VERSION "hnnbnnnynnnnnnnnnnnnnnnnnnnnnnnnnnnnnnnnnn/4/%%%/4/'%**4nnn///"

NS_ :

BS_:

BU_: BAP_Tester Fahrerdisplay_Kombi HUD ICAS1_X_Gateway ICAS3_Gateway ICC_IO_Node Kombi SmartLight_01 ZR_MIB_TOP_ab_Gen3

BO_ 1646 Klima_03: 8 ICAS1_X_Gateway
	SG_ KL_Anf_AussenspiegelHzg : 48|1@1+ (1,0) [0|1] ""  Vector__XXX
	SG_ KL_BCmE_Livetip_Freigabe : 24|1@1+ (1,0) [0|1] ""  Kombi
	SG_ KL_ErwVK_Anf : 31|1@1+ (1,0) [0|1] ""  Vector__XXX
	SG_ KL_FSH_Automatikbetrieb : 51|1@1+ (1,0) [0|1] ""  Vector__XXX
	SG_ KL_Geblaese_Fond_Status : 4|4@1+ (1,0) [0|15] ""  Vector__XXX
	SG_ KL_Geblaese_Status : 18|4@1+ (1,0) [0|15] ""  Kombi
	SG_ KL_Heizkreisventilstellung : 49|2@1+ (1,0) [0|3] ""  Vector__XXX
	SG_ KL_I_Geblaese_Fond : 40|8@1+ (0.25,0) [0|63.5] "Amper"  Vector__XXX
	SG_ KL_Innen_Temp : 32|8@1+ (0.5,-50) [-50|76] "DegreCelsi"  SmartLight_01
	SG_ KL_Kompressorkupplung : 23|1@1+ (1,0) [0|1] ""  Vector__XXX
	SG_ KL_Magnetventil : 16|1@1+ (1,0) [0|1] ""  Vector__XXX
	SG_ KL_Restwaerme_aktiv : 22|1@1+ (1,0) [0|1] ""  Vector__XXX
	SG_ KL_SH_Soll_hl : 25|3@1+ (1,0) [0|7] ""  Vector__XXX
	SG_ KL_SH_Soll_hr : 28|3@1+ (1,0) [0|7] ""  Vector__XXX
	SG_ KL_SIH_LEH_Verteilung_VL : 52|3@1+ (1,0) [0|7] ""  Vector__XXX
	SG_ KL_SIH_LEH_Verteilung_VR : 58|3@1+ (1,0) [0|7] ""  Vector__XXX
	SG_ KL_SIH_LEL_Verteilung_VL : 55|3@1+ (1,0) [0|7] ""  Vector__XXX
	SG_ KL_SIH_LEL_Verteilung_VR : 61|3@1+ (1,0) [0|7] ""  Vector__XXX
	SG_ KL_Solarluefter_aktiv : 2|1@1+ (1,0) [0|1] ""  Vector__XXX
	SG_ KL_STH_aktiv : 1|1@1+ (1,0) [0|1] ""  Vector__XXX
	SG_ KL_STH_Ansteuerung : 8|2@1+ (1,0) [0|3] ""  Vector__XXX
	SG_ KL_STH_Betriebsdauer : 10|6@1+ (1,0) [0|60] "Minut"  Vector__XXX
	SG_ KL_STL_aktiv : 0|1@1+ (1,0) [0|1] ""  Vector__XXX
	SG_ KL_Umluft_Taste : 3|1@1+ (1,0) [0|1] ""  Vector__XXX
	SG_ KL_WaPu : 17|1@1+ (1,0) [0|1] ""  Vector__XXX

BO_ 1649 Klima_06: 8 ICAS1_X_Gateway
	SG_ KL_Betriebsmodus_FH : 29|3@1+ (1,0) [0|7] ""  Vector__XXX
	SG_ KL_ErwVK_Beifahrerzone : 60|1@1+ (1,0) [0|1] ""  Vector__XXX
	SG_ KL_ErwVK_Fahrerzone : 61|1@1+ (1,0) [0|1] ""  Vector__XXX
	SG_ KL_ErwVK_Heckzone_links : 62|1@1+ (1,0) [0|1] ""  Vector__XXX
	SG_ Kl_ErwVK_Heckzone_rechts : 63|1@1+ (1,0) [0|1] ""  Vector__XXX
	SG_ KL_ErwVK_Scheibenheizung : 12|1@1+ (1,0) [0|1] ""  Vector__XXX
	SG_ KL_ErwVK_Status : 54|4@1+ (1,0) [0|15] ""  Vector__XXX
	SG_ KL_Hinweis_Kuehlmodus : 58|2@1+ (1,0) [0|3] ""  ICAS3_Gateway,Kombi
	SG_ KL_Meldung_Status : 50|4@1+ (1,0) [0|15] ""  Kombi,ZR_MIB_TOP_ab_Gen3
	SG_ KL_STH_Betriebsdauer_lang : 43|7@1+ (1,0) [0|120] "Minut"  Vector__XXX
	SG_ KL_Stopp_Wiederstart_Anz_01 : 32|1@1+ (1,0) [0|1] ""  Vector__XXX
	SG_ KL_Stopp_Wiederstart_Anz_02 : 33|1@1+ (1,0) [0|1] ""  Vector__XXX
	SG_ KL_Stopp_Wiederstart_Anz_03 : 34|1@1+ (1,0) [0|1] ""  Vector__XXX
	SG_ KL_Stopp_Wiederstart_Anz_04 : 35|1@1+ (1,0) [0|1] ""  Vector__XXX
	SG_ KL_Stopp_Wiederstart_Anz_05 : 36|1@1+ (1,0) [0|1] ""  Vector__XXX
	SG_ KL_Stopp_Wiederstart_Anz_06 : 37|1@1+ (1,0) [0|1] ""  Vector__XXX
	SG_ KL_Stopp_Wiederstart_Anz_07 : 38|1@1+ (1,0) [0|1] ""  Vector__XXX
	SG_ KL_Stopp_Wiederstart_Anz_08 : 39|1@1+ (1,0) [0|1] ""  Vector__XXX
	SG_ KL_Stopp_Wiederstart_Anz_09 : 40|1@1+ (1,0) [0|1] ""  Vector__XXX
	SG_ KL_Stopp_Wiederstart_Anz_Std1 : 41|1@1+ (1,0) [0|1] ""  Vector__XXX
	SG_ KL_Stopp_Wiederstart_Anz_Std2 : 42|1@1+ (1,0) [0|1] ""  Vector__XXX
	SG_ KL_ZZ_Betriebsmodus : 21|3@1+ (1,0) [0|7] ""  Vector__XXX
	SG_ KL_ZZ_Minute : 0|6@1+ (1,0) [0|59] "Minut"  Vector__XXX
	SG_ KL_ZZ_Monat : 8|4@1+ (1,0) [1|12] "Month"  Vector__XXX
	SG_ KL_ZZ_Status_Timer : 6|2@1+ (1,0) [0|3] ""  Vector__XXX
	SG_ KL_ZZ_Stunde : 16|5@1+ (1,0) [0|23] "Hours"  Vector__XXX
	SG_ KL_ZZ_Tag : 24|5@1+ (1,0) [1|31] "Day"  Vector__XXX

BO_ 1640 Klima_12: 8 ICAS1_X_Gateway
	SG_ FSH_Taster : 5|1@1+ (1,0) [0|1] ""  Vector__XXX
	SG_ HSH_Taster : 3|2@1+ (1,0) [0|3] ""  Vector__XXX
	SG_ KL_Beschlagsgefahr : 7|1@1+ (1,0) [0|1] ""  Vector__XXX
	SG_ KL_Geblspng_Fond_Soll : 32|8@1+ (0.05,1.45) [1.5|14] "Volt"  Vector__XXX
	SG_ KL_Geblspng_Soll : 24|8@1+ (0.05,1.45) [1.5|14] "Volt"  Vector__XXX
	SG_ KL_I_Geblaese : 40|8@1+ (0.25,0) [0|63.5] "Amper"  ZR_MIB_TOP_ab_Gen3
	SG_ KL_Kompressorstrom_soll : 48|10@1+ (1,0) [0|1021] ""  Vector__XXX
	SG_ KL_LRH_Stufe : 1|2@1+ (1,0) [0|3] ""  Kombi
	SG_ KL_LRH_Taster : 0|1@1+ (1,0) [0|1] ""  Vector__XXX
	SG_ KL_PTC_Verbauinfo : 62|2@1+ (1,0) [0|3] ""  Vector__XXX
	SG_ KL_SIH_Soll_li : 8|3@1+ (1,0) [0|6] ""  Vector__XXX
	SG_ KL_SIH_Soll_re : 11|3@1+ (1,0) [0|6] ""  Vector__XXX
	SG_ KL_SIL_Soll_li : 16|3@1+ (1,0) [0|6] ""  Vector__XXX
	SG_ KL_SIL_Soll_re : 19|3@1+ (1,0) [0|6] ""  Vector__XXX
	SG_ KL_Umluftklappe_Status : 58|4@1+ (1,0) [0|15] ""  Vector__XXX
	SG_ KL_Zuheizer_Freigabe : 6|1@1+ (1,0) [0|1] ""  Vector__XXX
	SG_ KRH_Soll_li : 14|2@1+ (1,0) [0|3] ""  Vector__XXX
	SG_ KRH_Soll_re : 22|2@1+ (1,0) [0|3] ""  Vector__XXX

BO_ 2527679635 Klima_16: 8 ICAS1_X_Gateway
	SG_ FSH_Status : 28|2@1+ (1,0) [0|3] ""  Vector__XXX
	SG_ HSH_Relais_Anf : 27|1@1+ (1,0) [0|1] ""  Vector__XXX
	SG_ KL_AL_HL_Anf : 18|2@1+ (1,0) [0|3] ""  Vector__XXX
	SG_ KL_AL_HR_Anf : 16|2@1+ (1,0) [0|3] ""  Vector__XXX
	SG_ KL_AL_VL_Anf : 14|2@1+ (1,0) [0|3] ""  Vector__XXX
	SG_ KL_AL_VR_Anf : 12|2@1+ (1,0) [0|3] ""  Vector__XXX
	SG_ KL_Defrost_LED : 25|1@1+ (1,0) [0|1] ""  Vector__XXX
	SG_ KL_FSH_LED : 36|1@1+ (1,0) [0|1] ""  Vector__XXX
	SG_ KL_FSH_Soll : 21|1@1+ (1,0) [0|1] ""  Vector__XXX
	SG_ KL_Heizstufe_LSH : 45|4@1+ (1,0) [0|15] ""  Vector__XXX
	SG_ KL_HSH_LED : 26|1@1+ (1,0) [0|1] ""  Vector__XXX
	SG_ KL_HSH_Soll : 20|1@1+ (1,0) [0|1] ""  Vector__XXX
	SG_ KL_HUP_aktiv : 37|1@1+ (1,0) [0|1] ""  Vector__XXX
	SG_ KL_Klappe_Status : 40|3@1+ (1,0) [0|7] ""  Vector__XXX
	SG_ KL_LRH_PWM : 4|7@1+ (1,0) [0|100] "PerCent"  Vector__XXX
	SG_ KL_LRH_Soll : 11|1@1+ (1,0) [0|1] ""  Vector__XXX
	SG_ KL_LSH_Ansteuerung : 43|2@1+ (1,0) [0|3] ""  Vector__XXX
	SG_ KL_LSH_Betriebsdauer : 49|7@1+ (1,0) [0|120] "Minut"  Vector__XXX
	SG_ KL_LSH_DBetr_Bestaet : 39|1@1+ (1,0) [0|1] ""  Vector__XXX
	SG_ KL_LSH_DBetr_Ein : 38|1@1+ (1,0) [0|1] ""  Vector__XXX
	SG_ KL_Temp_ZH_Soll : 56|8@1+ (0.5,0) [0.5|127] "DegreCelsi"  Vector__XXX
	SG_ KL_VoKo_LED : 24|1@1+ (1,0) [0|1] ""  Vector__XXX
	SG_ KL_Voko_Status : 0|4@1+ (1,0) [0|15] ""  Vector__XXX
	SG_ KL_ZR_Anforderung : 22|2@1+ (1,0) [0|3] ""  ICAS3_Gateway,ZR_MIB_TOP_ab_Gen3
	SG_ SIH_Stufe_LED_li : 30|3@1+ (1,0) [0|7] ""  Vector__XXX
	SG_ SIH_Stufe_LED_re : 33|3@1+ (1,0) [0|7] ""  Vector__XXX

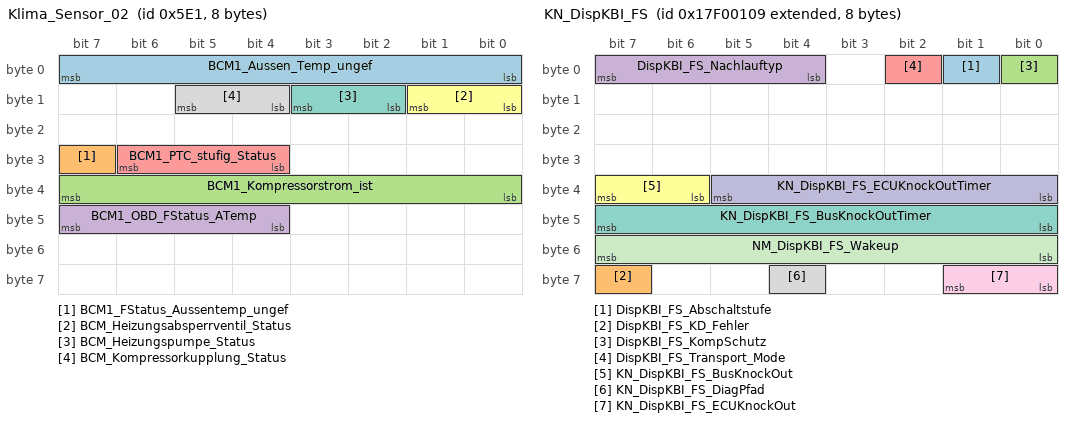
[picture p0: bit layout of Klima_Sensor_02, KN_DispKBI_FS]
BO_ 1505 Klima_Sensor_02: 8 ICAS1_X_Gateway
	SG_ BCM1_Aussen_Temp_ungef : 0|8@1+ (0.5,-50) [-50|76] "DegreCelsi"  ICAS3_Gateway,Kombi
	SG_ BCM1_FStatus_Aussentemp_ungef : 31|1@1+ (1,0) [0|1] ""  Kombi
	SG_ BCM1_Kompressorstrom_ist : 32|8@1+ (4,0) [0|1000] "MilliAmper"  Vector__XXX
	SG_ BCM1_OBD_FStatus_ATemp : 44|4@1+ (1,0) [0|15] ""  Vector__XXX
	SG_ BCM1_PTC_stufig_Status : 28|3@1+ (1,0) [0|7] ""  Vector__XXX
	SG_ BCM_Heizungsabsperrventil_Status : 8|2@1+ (1,0) [0|3] ""  Vector__XXX
	SG_ BCM_Heizungspumpe_Status : 10|2@1+ (1,0) [0|3] ""  Vector__XXX
	SG_ BCM_Kompressorkupplung_Status : 12|2@1+ (1,0) [0|3] ""  Vector__XXX

BO_ 2549088521 KN_DispKBI_FS: 8 Fahrerdisplay_Kombi
	SG_ DispKBI_FS_Abschaltstufe : 1|1@1+ (1,0) [0|1] ""  Vector__XXX
	SG_ DispKBI_FS_KD_Fehler : 63|1@1+ (1,0) [0|1] ""  ICAS1_X_Gateway
	SG_ DispKBI_FS_KompSchutz : 0|1@1+ (1,0) [0|1] ""  Vector__XXX
	SG_ DispKBI_FS_Nachlauftyp : 4|4@1+ (1,0) [0|15] ""  ICAS1_X_Gateway
	SG_ DispKBI_FS_Transport_Mode : 2|1@1+ (1,0) [0|1] ""  Vector__XXX
	SG_ KN_DispKBI_FS_BusKnockOut : 38|2@1+ (1,0) [0|3] ""  Vector__XXX
	SG_ KN_DispKBI_FS_BusKnockOutTimer : 40|8@1+ (1,0) [0|254] ""  Vector__XXX
	SG_ KN_DispKBI_FS_DiagPfad : 60|1@1+ (1,0) [0|1] ""  ICAS1_X_Gateway
	SG_ KN_DispKBI_FS_ECUKnockOut : 56|2@1+ (1,0) [0|3] ""  Vector__XXX
	SG_ KN_DispKBI_FS_ECUKnockOutTimer : 32|6@1+ (1,0) [0|62] ""  Vector__XXX
	SG_ NM_DispKBI_FS_Wakeup : 48|8@1+ (1,0) [0|255] ""  Vector__XXX

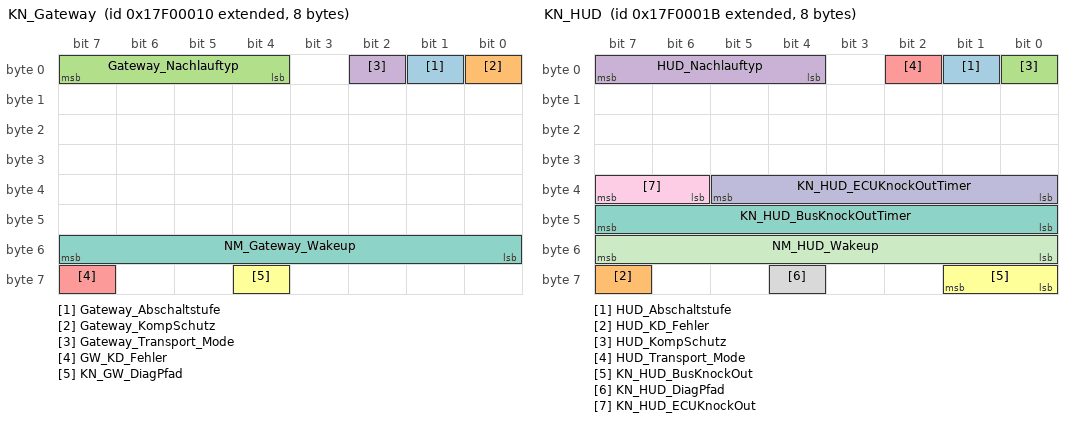
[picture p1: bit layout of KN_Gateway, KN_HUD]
BO_ 2549088272 KN_Gateway: 8 ICAS1_X_Gateway
	SG_ Gateway_Abschaltstufe : 1|1@1+ (1,0) [0|1] ""  Vector__XXX
	SG_ Gateway_KompSchutz : 0|1@1+ (1,0) [0|1] ""  Vector__XXX
	SG_ Gateway_Nachlauftyp : 4|4@1+ (1,0) [0|15] ""  Vector__XXX
	SG_ Gateway_Transport_Mode : 2|1@1+ (1,0) [0|1] ""  Vector__XXX
	SG_ GW_KD_Fehler : 63|1@1+ (1,0) [0|1] ""  Vector__XXX
	SG_ KN_GW_DiagPfad : 60|1@1+ (1,0) [0|1] ""  Vector__XXX
	SG_ NM_Gateway_Wakeup : 48|8@1+ (1,0) [0|255] ""  Vector__XXX

BO_ 2549088283 KN_HUD: 8 HUD
	SG_ HUD_Abschaltstufe : 1|1@1+ (1,0) [0|1] ""  Vector__XXX
	SG_ HUD_KD_Fehler : 63|1@1+ (1,0) [0|1] ""  ICAS1_X_Gateway
	SG_ HUD_KompSchutz : 0|1@1+ (1,0) [0|1] ""  Vector__XXX
	SG_ HUD_Nachlauftyp : 4|4@1+ (1,0) [0|15] ""  ICAS1_X_Gateway
	SG_ HUD_Transport_Mode : 2|1@1+ (1,0) [0|1] ""  Vector__XXX
	SG_ KN_HUD_BusKnockOut : 56|2@1+ (1,0) [0|3] ""  Vector__XXX
	SG_ KN_HUD_BusKnockOutTimer : 40|8@1+ (1,0) [0|254] "Minut"  Vector__XXX
	SG_ KN_HUD_DiagPfad : 60|1@1+ (1,0) [0|1] ""  ICAS1_X_Gateway
	SG_ KN_HUD_ECUKnockOut : 38|2@1+ (1,0) [0|3] ""  Vector__XXX
	SG_ KN_HUD_ECUKnockOutTimer : 32|6@1+ (1,0) [0|62] "Minut"  Vector__XXX
	SG_ NM_HUD_Wakeup : 48|8@1+ (1,0) [0|255] ""  Vector__XXX

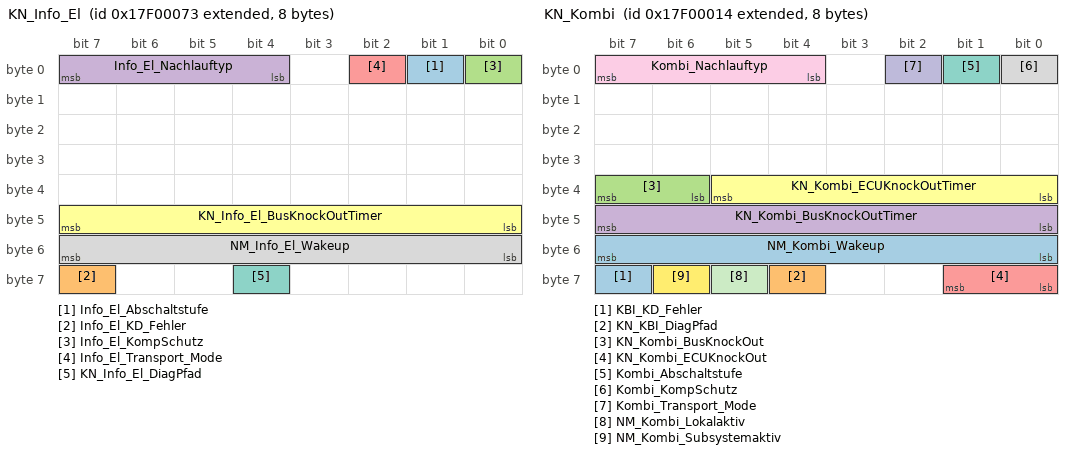
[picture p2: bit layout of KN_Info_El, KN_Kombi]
BO_ 2549088371 KN_Info_El: 8 ICAS3_Gateway
	SG_ Info_El_Abschaltstufe : 1|1@1+ (1,0) [0|1] ""  Vector__XXX
	SG_ Info_El_KD_Fehler : 63|1@1+ (1,0) [0|1] ""  ICAS1_X_Gateway
	SG_ Info_El_KompSchutz : 0|1@1+ (1,0) [0|1] ""  Vector__XXX
	SG_ Info_El_Nachlauftyp : 4|4@1+ (1,0) [0|15] ""  ICAS1_X_Gateway
	SG_ Info_El_Transport_Mode : 2|1@1+ (1,0) [0|1] ""  Vector__XXX
	SG_ KN_Info_El_BusKnockOutTimer : 40|8@1+ (1,0) [0|254] "Minut"  Vector__XXX
	SG_ KN_Info_El_DiagPfad : 60|1@1+ (1,0) [0|1] ""  ICAS1_X_Gateway
	SG_ NM_Info_El_Wakeup : 48|8@1+ (1,0) [0|255] ""  Vector__XXX

BO_ 2549088276 KN_Kombi: 8 Kombi
	SG_ KBI_KD_Fehler : 63|1@1+ (1,0) [0|1] ""  ICAS1_X_Gateway
	SG_ KN_KBI_DiagPfad : 60|1@1+ (1,0) [0|1] ""  ICAS1_X_Gateway
	SG_ KN_Kombi_BusKnockOut : 38|2@1+ (1,0) [0|3] ""  Vector__XXX
	SG_ KN_Kombi_BusKnockOutTimer : 40|8@1+ (1,0) [0|254] ""  Vector__XXX
	SG_ KN_Kombi_ECUKnockOut : 56|2@1+ (1,0) [0|3] ""  Vector__XXX
	SG_ KN_Kombi_ECUKnockOutTimer : 32|6@1+ (1,0) [0|62] "Minut"  Vector__XXX
	SG_ Kombi_Abschaltstufe : 1|1@1+ (1,0) [0|1] ""  Vector__XXX
	SG_ Kombi_KompSchutz : 0|1@1+ (1,0) [0|1] ""  Vector__XXX
	SG_ Kombi_Nachlauftyp : 4|4@1+ (1,0) [0|15] ""  ICAS1_X_Gateway
	SG_ Kombi_Transport_Mode : 2|1@1+ (1,0) [0|1] ""  Vector__XXX
	SG_ NM_Kombi_Lokalaktiv : 61|1@1+ (1,0) [0|1] ""  Vector__XXX
	SG_ NM_Kombi_Subsystemaktiv : 62|1@1+ (1,0) [0|1] ""  Vector__XXX
	SG_ NM_Kombi_Wakeup : 48|8@1+ (1,0) [0|255] ""  Vector__XXX

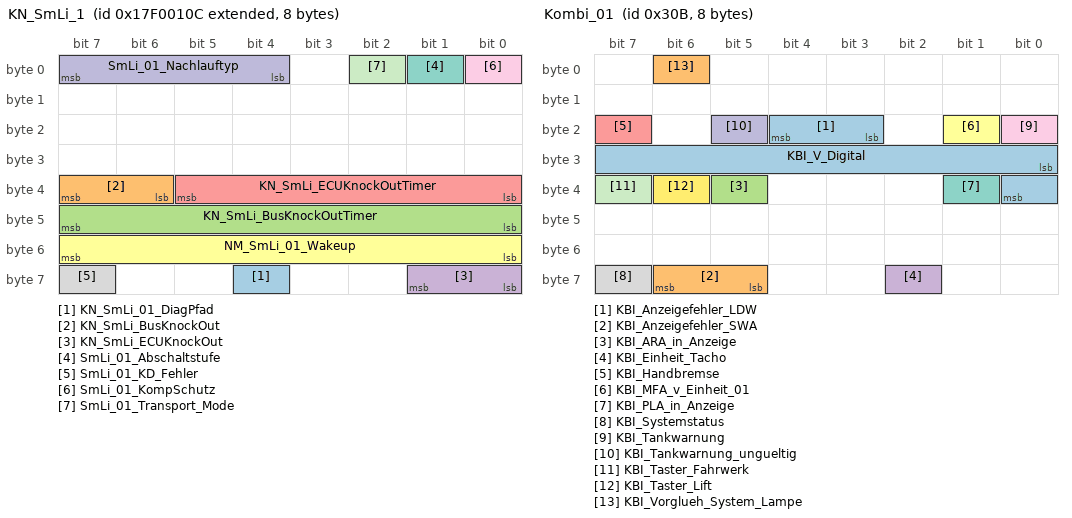
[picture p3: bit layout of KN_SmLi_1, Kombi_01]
BO_ 2549088524 KN_SmLi_1: 8 SmartLight_01
	SG_ KN_SmLi_01_DiagPfad : 60|1@1+ (1,0) [0|1] ""  ICAS1_X_Gateway
	SG_ KN_SmLi_BusKnockOut : 38|2@1+ (1,0) [0|3] ""  Vector__XXX
	SG_ KN_SmLi_BusKnockOutTimer : 40|8@1+ (1,0) [0|254] ""  Vector__XXX
	SG_ KN_SmLi_ECUKnockOut : 56|2@1+ (1,0) [0|3] ""  Vector__XXX
	SG_ KN_SmLi_ECUKnockOutTimer : 32|6@1+ (1,0) [0|62] "Minut"  Vector__XXX
	SG_ NM_SmLi_01_Wakeup : 48|8@1+ (1,0) [0|255] ""  Vector__XXX
	SG_ SmLi_01_Abschaltstufe : 1|1@1+ (1,0) [0|1] ""  Vector__XXX
	SG_ SmLi_01_KD_Fehler : 63|1@1+ (1,0) [0|1] ""  ICAS1_X_Gateway
	SG_ SmLi_01_KompSchutz : 0|1@1+ (1,0) [0|1] ""  Vector__XXX
	SG_ SmLi_01_Nachlauftyp : 4|4@1+ (1,0) [0|15] ""  ICAS1_X_Gateway
	SG_ SmLi_01_Transport_Mode : 2|1@1+ (1,0) [0|1] ""  Vector__XXX

BO_ 779 Kombi_01: 8 Kombi
	SG_ KBI_Anzeigefehler_LDW : 19|2@1+ (1,0) [0|3] ""  ICAS1_X_Gateway
	SG_ KBI_Anzeigefehler_SWA : 61|2@1+ (1,0) [0|3] ""  ICAS1_X_Gateway
	SG_ KBI_ARA_in_Anzeige : 37|1@1+ (1,0) [0|1] ""  ICAS1_X_Gateway
	SG_ KBI_Einheit_Tacho : 58|1@1+ (1,0) [0|1] ""  ICAS1_X_Gateway
	SG_ KBI_Handbremse : 23|1@1+ (1,0) [0|1] ""  ICAS1_X_Gateway
	SG_ KBI_MFA_v_Einheit_01 : 17|1@1+ (1,0) [0|1] ""  ICAS1_X_Gateway,ZR_MIB_TOP_ab_Gen3
	SG_ KBI_PLA_in_Anzeige : 33|1@1+ (1,0) [0|1] ""  ICAS1_X_Gateway
	SG_ KBI_Systemstatus : 63|1@1+ (1,0) [0|1] ""  ICAS1_X_Gateway
	SG_ KBI_Tankwarnung : 16|1@1+ (1,0) [0|1] ""  ICAS1_X_Gateway
	SG_ KBI_Tankwarnung_ungueltig : 21|1@1+ (1,0) [0|1] ""  ICAS1_X_Gateway
	SG_ KBI_Taster_Fahrwerk : 39|1@1+ (1,0) [0|1] ""  ICAS1_X_Gateway
	SG_ KBI_Taster_Lift : 38|1@1+ (1,0) [0|1] ""  ICAS1_X_Gateway
	SG_ KBI_V_Digital : 24|9@1+ (1,0) [0|511] ""  ICAS1_X_Gateway,ZR_MIB_TOP_ab_Gen3
	SG_ KBI_Vorglueh_System_Lampe : 6|1@1+ (1,0) [0|1] ""  ICAS1_X_Gateway

BO_ 1719 Kombi_02: 8 Kombi
	SG_ KBI_FoD_PopUP_Quittiert : 52|1@1+ (1,0) [0|1] ""  ICAS1_X_Gateway
	SG_ KBI_FStatus_Tank : 47|1@1+ (1,0) [0|1] ""  ICAS1_X_Gateway,ZR_MIB_TOP_ab_Gen3

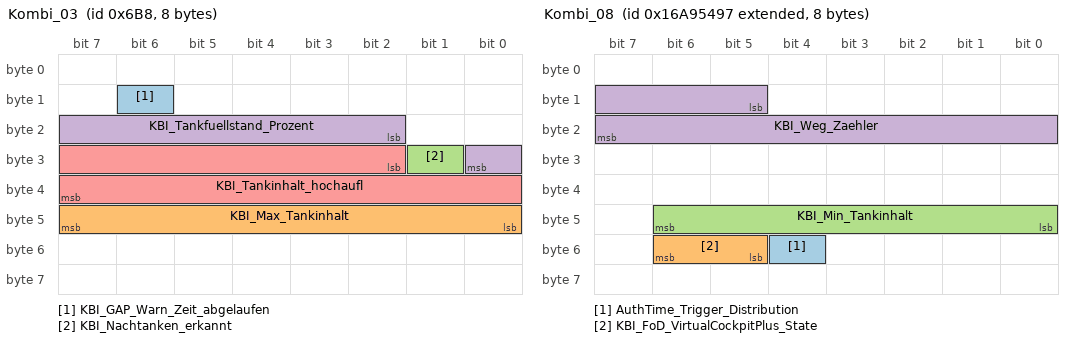
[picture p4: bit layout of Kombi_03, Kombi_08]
BO_ 1720 Kombi_03: 8 Kombi
	SG_ KBI_GAP_Warn_Zeit_abgelaufen : 14|1@1+ (1,0) [0|1] ""  ICAS1_X_Gateway
	SG_ KBI_Max_Tankinhalt : 40|8@1+ (0.5,0) [0|126.5] ""  ICAS1_X_Gateway
	SG_ KBI_Nachtanken_erkannt : 25|1@1+ (1,0) [0|1] ""  ICAS1_X_Gateway
	SG_ KBI_Tankfuellstand_Prozent : 18|7@1+ (1,0) [0|100] "PerCent"  ICAS1_X_Gateway
	SG_ KBI_Tankinhalt_hochaufl : 26|14@1+ (0.01,0) [0|163.81] "Liter"  ICAS1_X_Gateway,ICAS3_Gateway

BO_ 2527679639 Kombi_08: 8 Kombi
	SG_ AuthTime_Trigger_Distribution : 52|1@1+ (1,0) [0|1] ""  Vector__XXX
	SG_ KBI_FoD_VirtualCockpitPlus_State : 53|2@1+ (1,0) [0|3] ""  ICAS1_X_Gateway
	SG_ KBI_Min_Tankinhalt : 40|7@1+ (0.1,0) [0|12.5] "Liter"  Vector__XXX
	SG_ KBI_Weg_Zaehler : 13|11@1+ (1,0) [0|2047] "Meter"  Vector__XXX

BO_ 2589283631 Kombi_21: 8 Kombi
	SG_ KBI_BC_Reset_E1 : 23|3@1+ (1,0) [0|7] ""  ICAS1_X_Gateway
	SG_ KBI_Tankinhalt_roh : 12|11@1+ (0.1,0) [0|204.5] "Liter"  ICAS1_X_Gateway

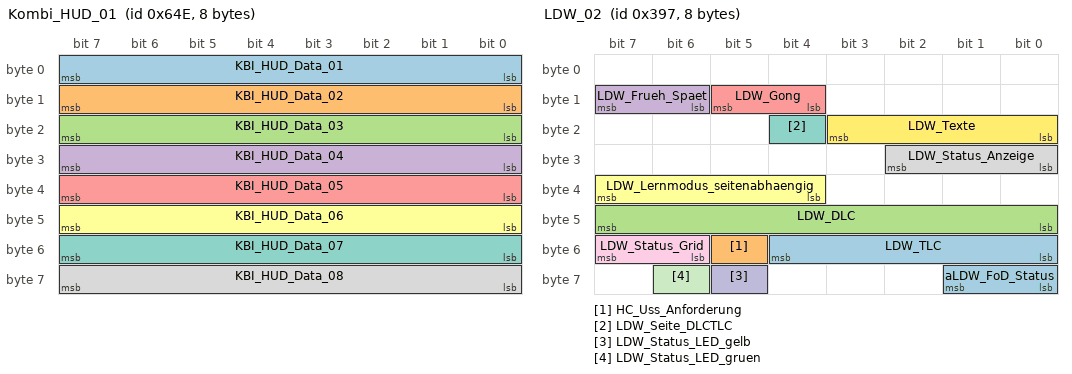
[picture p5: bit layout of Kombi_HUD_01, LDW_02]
BO_ 1614 Kombi_HUD_01: 8 Kombi
	SG_ KBI_HUD_Data_01 : 0|8@1+ (1,0) [0|255] ""  ICAS1_X_Gateway,ZR_MIB_TOP_ab_Gen3
	SG_ KBI_HUD_Data_02 : 8|8@1+ (1,0) [0|255] ""  ICAS1_X_Gateway,ZR_MIB_TOP_ab_Gen3
	SG_ KBI_HUD_Data_03 : 16|8@1+ (1,0) [0|255] ""  ICAS1_X_Gateway,ZR_MIB_TOP_ab_Gen3
	SG_ KBI_HUD_Data_04 : 24|8@1+ (1,0) [0|255] ""  ICAS1_X_Gateway,ZR_MIB_TOP_ab_Gen3
	SG_ KBI_HUD_Data_05 : 32|8@1+ (1,0) [0|255] ""  ICAS1_X_Gateway,ZR_MIB_TOP_ab_Gen3
	SG_ KBI_HUD_Data_06 : 40|8@1+ (1,0) [0|255] ""  ICAS1_X_Gateway,ZR_MIB_TOP_ab_Gen3
	SG_ KBI_HUD_Data_07 : 48|8@1+ (1,0) [0|255] ""  ICAS1_X_Gateway,ZR_MIB_TOP_ab_Gen3
	SG_ KBI_HUD_Data_08 : 56|8@1+ (1,0) [0|255] ""  ICAS1_X_Gateway,ZR_MIB_TOP_ab_Gen3

BO_ 2621702408 KS_ICAS3Sys01_Req_FD: 16 ICAS1_X_Gateway
	SG_ KS_ICAS3Sys01_Req_FD_Data : 0|128@1+ (1,0) [0|340282366920938463463374607431768211456] ""  ICAS3_Gateway

BO_ 2621833480 KS_ICAS3Sys01_Resp_FD: 16 ICAS3_Gateway
	SG_ KS_ICAS3Sys01_Resp_FD_Data : 0|128@1+ (1,0) [0|340282366920938463463374607431768211456] ""  ICAS1_X_Gateway

BO_ 2621440371 KS_Info_El_Req_FD: 16 ICAS1_X_Gateway
	SG_ KS_Info_El_Req_FD_Data : 0|128@1+ (1,0) [0|340282366920938463463374607431768211456] ""  ICC_IO_Node,ZR_MIB_TOP_ab_Gen3

BO_ 2621571443 KS_Info_El_Resp_FD: 16 ICC_IO_Node
	SG_ KS_Info_El_Resp_FD_Data : 0|128@1+ (1,0) [0|340282366920938463463374607431768211456] ""  ICAS1_X_Gateway

BO_ 2621440276 KS_Kombi_Req_FD: 16 ICAS1_X_Gateway
	SG_ KS_Kombi_Req_FD_Data : 0|128@1+ (1,0) [0|340282366920938463463374607431768211456] ""  Kombi

BO_ 2621571348 KS_Kombi_Resp_FD: 16 Kombi
	SG_ KS_Kombi_Resp_FD_Data : 0|128@1+ (1,0) [0|340282366920938463463374607431768211456] ""  ICAS1_X_Gateway

BO_ 2549899278 KS_SSN_ABT_1_Req: 8 ICAS1_X_Gateway
	SG_ KS_SSN_ABT_1_Req_Data : 0|64@1+ (1,0) [0|18446744073709551616] ""  ICAS3_Gateway,ICC_IO_Node,ZR_MIB_TOP_ab_Gen3

BO_ 2550030350 KS_SSN_ABT_1_Resp: 8 ICAS3_Gateway
	SG_ KS_SSN_ABT_1_Resp_Data : 0|64@1+ (1,0) [0|18446744073709551616] ""  ICAS1_X_Gateway

BO_ 2549875053 KS_TV_Tuner_Req: 8 ICAS1_X_Gateway
	SG_ KS_TV_Tuner_Req_Data : 0|64@1+ (1,0) [0|18446744073709551616] ""  ZR_MIB_TOP_ab_Gen3

BO_ 2550006125 KS_TV_Tuner_Resp: 8 ZR_MIB_TOP_ab_Gen3
	SG_ KS_TV_Tuner_Resp_Data : 0|64@1+ (1,0) [0|18446744073709551616] ""  ICAS1_X_Gateway

BO_ 919 LDW_02: 8 ICAS1_X_Gateway
	SG_ aLDW_FoD_Status : 56|2@1+ (1,0) [0|3] ""  Kombi,ZR_MIB_TOP_ab_Gen3
	SG_ HC_Uss_Anforderung : 53|1@1+ (1,0) [0|1] ""  Vector__XXX
	SG_ LDW_DLC : 40|8@1+ (0.01,-1.25) [-1.25|1.25] "Meter"  Vector__XXX
	SG_ LDW_Frueh_Spaet : 14|2@1+ (1,0) [0|3] ""  Vector__XXX
	SG_ LDW_Gong : 12|2@1+ (1,0) [0|3] ""  Kombi
	SG_ LDW_Lernmodus_seitenabhaengig : 36|4@1+ (1,0) [0|15] ""  Kombi
	SG_ LDW_Seite_DLCTLC : 20|1@1+ (1,0) [0|1] ""  Vector__XXX
	SG_ LDW_Status_Anzeige : 24|3@1+ (1,0) [0|7] ""  Kombi
	SG_ LDW_Status_Grid : 54|2@1+ (1,0) [0|3] ""  Vector__XXX
	SG_ LDW_Status_LED_gelb : 61|1@1+ (1,0) [0|1] ""  Vector__XXX
	SG_ LDW_Status_LED_gruen : 62|1@1+ (1,0) [0|1] ""  Vector__XXX
	SG_ LDW_Texte : 16|4@1+ (1,0) [0|15] ""  Kombi
	SG_ LDW_TLC : 48|5@1+ (0.1,0) [0|3] "Secon"  Vector__XXX

BO_ 810 LH_EPS_01: 8 ICAS1_X_Gateway
	SG_ EPS_01_BZ : 8|4@1+ (1,0) [0|15] ""  Fahrerdisplay_Kombi,Kombi
	SG_ EPS_01_CRC : 0|8@1+ (1,0) [0|255] ""  Fahrerdisplay_Kombi,Kombi
	SG_ EPS_Akustiksignal : 16|1@1+ (1,0) [0|1] ""  Vector__XXX
	SG_ EPS_Anf_KL : 43|1@1+ (1,0) [0|1] ""  Vector__XXX
	SG_ EPS_ARA_Status : 44|4@1+ (1,0) [0|15] ""  Vector__XXX
	SG_ EPS_Charisma_FahrPr : 34|4@1+ (1,0) [0|15] ""  Vector__XXX
	SG_ EPS_Charisma_Status : 38|2@1+ (1,0) [0|3] ""  Vector__XXX
	SG_ EPS_Endanschlag : 14|2@1+ (1,0) [0|3] ""  Vector__XXX
	SG_ EPS_Fehlerlampe : 17|1@1+ (1,0) [0|1] ""  Vector__XXX
	SG_ EPS_Lenkerposition : 41|2@1+ (1,0) [0|3] ""  Vector__XXX
	SG_ EPS_PLA_Abbruch : 22|4@1+ (1,0) [0|15] ""  Vector__XXX
	SG_ EPS_PLA_Fehler : 26|4@1+ (1,0) [0|15] ""  Vector__XXX
	SG_ EPS_PLA_Status : 30|4@1+ (1,0) [0|15] ""  Vector__XXX
	SG_ EPS_SpannungsAnf : 12|2@1+ (1,0) [0|3] ""  Vector__XXX
	SG_ EPS_VZ_Zst_Offset_Geradeaus : 40|1@1+ (1,0) [0|1] ""  Vector__XXX
	SG_ EPS_Warnungen : 19|3@1+ (1,0) [0|7] ""  Fahrerdisplay_Kombi,Kombi
	SG_ EPS_Zst_Offset_Geradeaus : 48|9@1+ (0.00306,0) [0|1.55754] "MilliMeter"  Vector__XXX

BO_ 981 Licht_Anf_01: 8 ICAS1_X_Gateway
	SG_ BCM1_Abblendlicht_Anf : 15|1@1+ (1,0) [0|1] ""  Kombi
	SG_ BCM1_Adaptive_Lichtvert_Anf : 34|1@1+ (1,0) [0|1] ""  Vector__XXX
	SG_ BCM1_Allwetterlicht_Anf : 41|1@1+ (1,0) [0|1] ""  Vector__XXX
	SG_ BCM1_Autobahnlicht_Anf : 28|1@1+ (1,0) [0|1] ""  Vector__XXX
	SG_ BCM1_CH_aktiv : 30|1@1+ (1,0) [0|1] ""  Vector__XXX
	SG_ BCM1_CH_LH_aktiv : 40|1@1+ (1,0) [0|1] ""  Vector__XXX
	SG_ BCM1_Fahrlicht_Hinweis : 46|1@1+ (1,0) [0|1] ""  Kombi
	SG_ BCM1_Fernlicht_Anf : 16|1@1+ (1,0) [0|1] ""  Vector__XXX
	SG_ BCM1_Gleitende_Leuchtw_Anf : 32|1@1+ (1,0) [0|1] ""  Vector__XXX
	SG_ BCM1_GLW_Fernlicht_Anf : 33|1@1+ (1,0) [0|1] ""  Vector__XXX
	SG_ BCM1_Hinweis_Lichtnachlauf : 49|1@1+ (1,0) [0|1] ""  Kombi
	SG_ BCM1_Kurvenlicht_links_Anf : 12|1@1+ (1,0) [0|1] ""  Vector__XXX
	SG_ BCM1_Kurvenlicht_rechts_Anf : 13|1@1+ (1,0) [0|1] ""  Vector__XXX
	SG_ BCM1_LH_aktiv : 31|1@1+ (1,0) [0|1] ""  Vector__XXX
	SG_ BCM1_Lichtwarn_Texte : 47|2@1+ (1,0) [0|3] ""  Kombi
	SG_ BCM1_Nebellicht_Anf : 17|1@1+ (1,0) [0|1] ""  Vector__XXX
	SG_ BCM1_Nebelschluss_Ahg_Anf : 20|1@1+ (1,0) [0|1] ""  Vector__XXX
	SG_ BCM1_Nebelschluss_Fzg_Anf : 21|1@1+ (1,0) [0|1] ""  Vector__XXX
	SG_ BCM1_Parklicht_li_Anf : 18|1@1+ (1,0) [0|1] ""  Vector__XXX
	SG_ BCM1_Parklicht_re_Anf : 19|1@1+ (1,0) [0|1] ""  Vector__XXX
	SG_ BCM1_Regenlicht_Anf : 27|1@1+ (1,0) [0|1] ""  Vector__XXX
	SG_ BCM1_Schlusslicht_Anf : 22|1@1+ (1,0) [0|1] ""  Vector__XXX
	SG_ BCM1_Signaturlicht_Anf : 24|1@1+ (1,0) [0|1] ""  Vector__XXX
	SG_ BCM1_Standlicht_Anf : 14|1@1+ (1,0) [0|1] ""  Kombi
	SG_ BCM1_Tagfahrlicht_Anf : 26|1@1+ (1,0) [0|1] ""  Vector__XXX
	SG_ BCM1_Touristen_Licht_Anf : 29|1@1+ (1,0) [0|1] ""  Vector__XXX
	SG_ BCM1_Umfeldleuchten_Anf : 25|1@1+ (1,0) [0|1] ""  Vector__XXX
	SG_ BCM_Rueckfahrlicht_Anf : 23|1@1+ (1,0) [0|1] ""  ICAS3_Gateway,Kombi,ZR_MIB_TOP_ab_Gen3
	SG_ Licht_Anf_01_BZ : 8|4@1+ (1,0) [0|15] ""  Vector__XXX
	SG_ Licht_Anf_01_CRC : 0|8@1+ (1,0) [0|255] ""  Vector__XXX
	SG_ TFL_Matrix_Variante01_Anf : 42|1@1+ (1,0) [0|1] ""  Vector__XXX
	SG_ TFL_Matrix_Variante02_Anf : 43|1@1+ (1,0) [0|1] ""  Vector__XXX
	SG_ TFL_Matrix_Variante03_Anf : 44|1@1+ (1,0) [0|1] ""  Vector__XXX
	SG_ TFL_Matrix_Variante04_Anf : 45|1@1+ (1,0) [0|1] ""  Vector__XXX

BO_ 982 Licht_hinten_01: 8 ICAS1_X_Gateway
	SG_ BRL_als_SHL : 62|1@1+ (1,0) [0|1] ""  Vector__XXX
	SG_ LH_3_Bremsl_def : 49|1@1+ (1,0) [0|1] ""  Kombi
	SG_ LH_Aussenlicht_def : 7|1@1+ (1,0) [0|1] ""  Kombi
	SG_ LH_Blinker_HL_akt : 14|1@1+ (1,0) [0|1] ""  Vector__XXX
	SG_ LH_Blinker_HR_akt : 15|1@1+ (1,0) [0|1] ""  Vector__XXX
	SG_ LH_Blinker_li_def : 16|1@1+ (1,0) [0|1] ""  Kombi
	SG_ LH_Blinker_re_def : 32|1@1+ (1,0) [0|1] ""  Kombi
	SG_ LH_Brems_Blk_li_def : 27|1@1+ (1,0) [0|1] ""  Kombi
	SG_ LH_Brems_Blk_re_def : 43|1@1+ (1,0) [0|1] ""  Kombi
	SG_ LH_Bremsl_li_def : 17|1@1+ (1,0) [0|1] ""  Kombi
	SG_ LH_Bremsl_li_ges_def : 54|1@1+ (1,0) [0|1] ""  Kombi
	SG_ LH_Bremsl_mi_def : 61|1@1+ (1,0) [0|1] ""  Vector__XXX
	SG_ LH_Bremsl_re_def : 33|1@1+ (1,0) [0|1] ""  Kombi
	SG_ LH_Bremsl_re_ges_def : 55|1@1+ (1,0) [0|1] ""  Kombi
	SG_ LH_Bremslicht_H_aktiv : 11|1@1+ (1,0) [0|1] ""  Kombi
	SG_ LH_Diag_LED_li_def : 30|1@1+ (1,0) [0|1] ""  Vector__XXX
	SG_ LH_Diag_LED_re_def : 31|1@1+ (1,0) [0|1] ""  Vector__XXX
	SG_ LH_Diag_Status_li_def : 29|1@1+ (1,0) [0|1] ""  Vector__XXX
	SG_ LH_Diag_Status_re_def : 28|1@1+ (1,0) [0|1] ""  Vector__XXX
	SG_ LH_Kennzl_def : 48|1@1+ (1,0) [0|1] ""  Kombi
	SG_ LH_Nebel_li_def : 20|1@1+ (1,0) [0|1] ""  Kombi
	SG_ LH_Nebel_mi_def : 50|1@1+ (1,0) [0|1] ""  Kombi
	SG_ LH_Nebel_re_def : 36|1@1+ (1,0) [0|1] ""  Kombi
	SG_ LH_Nebelschluss_aktiv : 12|1@1+ (1,0) [0|1] ""  Vector__XXX
	SG_ LH_Parklicht_HL_aktiv : 9|1@1+ (1,0) [0|1] ""  Vector__XXX
	SG_ LH_Parklicht_HR_aktiv : 10|1@1+ (1,0) [0|1] ""  Vector__XXX
	SG_ LH_Rueckf_li_def : 19|1@1+ (1,0) [0|1] ""  Kombi
	SG_ LH_Rueckf_mi_def : 51|1@1+ (1,0) [0|1] ""  Kombi
	SG_ LH_Rueckf_re_def : 35|1@1+ (1,0) [0|1] ""  Kombi
	SG_ LH_Rueckfahrlicht_aktiv : 13|1@1+ (1,0) [0|1] ""  Vector__XXX
	SG_ LH_Schluss_Brems_li_def : 24|1@1+ (1,0) [0|1] ""  Kombi
	SG_ LH_Schluss_Brems_mi_def : 37|1@1+ (1,0) [0|1] ""  Kombi
	SG_ LH_Schluss_Brems_Nebel_li_def : 21|1@1+ (1,0) [0|1] ""  Kombi
	SG_ LH_Schluss_Brems_Nebel_re_def : 22|1@1+ (1,0) [0|1] ""  Kombi
	SG_ LH_Schluss_Brems_re_def : 40|1@1+ (1,0) [0|1] ""  Kombi
	SG_ LH_Schluss_Nebel_li_def : 25|1@1+ (1,0) [0|1] ""  Kombi
	SG_ LH_Schluss_Nebel_re_def : 41|1@1+ (1,0) [0|1] ""  Kombi
	SG_ LH_Schlusslicht_li_def : 18|1@1+ (1,0) [0|1] ""  Kombi
	SG_ LH_Schlusslicht_mi_def : 52|1@1+ (1,0) [0|1] ""  Kombi
	SG_ LH_Schlusslicht_re_def : 34|1@1+ (1,0) [0|1] ""  Kombi
	SG_ LH_SL_BRL_BLK_li_def : 26|1@1+ (1,0) [0|1] ""  Kombi
	SG_ LH_SL_BRL_BLK_re_def : 42|1@1+ (1,0) [0|1] ""  Kombi
	SG_ LH_Standlicht_H_aktiv : 8|1@1+ (1,0) [0|1] ""  Vector__XXX
	SG_ LH_Zusatzschlussl_def : 23|1@1+ (1,0) [0|1] ""  Vector__XXX
	SG_ Licht_hinten_01_BZ : 0|4@1+ (1,0) [0|15] ""  Vector__XXX

BO_ 1624 Licht_vorne_01: 8 ICAS1_X_Gateway
	SG_ BCM1_Licht_Dunkelheit_aktiv : 49|1@1+ (1,0) [0|1] ""  Vector__XXX
	SG_ LV_Abbiegelicht_li_def : 46|1@1+ (1,0) [0|1] ""  Kombi
	SG_ LV_Abbiegelicht_re_def : 47|1@1+ (1,0) [0|1] ""  Kombi
	SG_ LV_Abblend_Fernlicht_li_def : 41|1@1+ (1,0) [0|1] ""  Kombi
	SG_ LV_Abblend_Fernlicht_re_def : 45|1@1+ (1,0) [0|1] ""  Kombi
	SG_ LV_Abblendlicht_Anzeige : 13|1@1+ (1,0) [0|1] ""  Kombi
	SG_ LV_Abblendlicht_li_def : 22|1@1+ (1,0) [0|1] ""  Kombi
	SG_ LV_Abblendlicht_re_def : 32|1@1+ (1,0) [0|1] ""  Kombi
	SG_ LV_Abblendlicht_TFL_li_def : 38|1@1+ (1,0) [0|1] ""  Kombi
	SG_ LV_Abblendlicht_TFL_re_def : 42|1@1+ (1,0) [0|1] ""  Kombi
	SG_ LV_AFL_aktiv_Anzeige : 18|1@1+ (1,0) [0|1] ""  Kombi
	SG_ LV_AFL_defekt : 19|1@1+ (1,0) [0|1] ""  Kombi
	SG_ LV_Aussenlicht_def : 37|1@1+ (1,0) [0|1] ""  Kombi
	SG_ LV_Blinker_li_def : 20|1@1+ (1,0) [0|1] ""  Kombi
	SG_ LV_Blinker_re_def : 30|1@1+ (1,0) [0|1] ""  Kombi
	SG_ LV_Blinker_VL_aktiv : 52|1@1+ (1,0) [0|1] ""  Vector__XXX
	SG_ LV_Blinker_VR_aktiv : 53|1@1+ (1,0) [0|1] ""  Vector__XXX
	SG_ LV_Blk_li_Seite_def : 25|1@1+ (1,0) [0|1] ""  Kombi
	SG_ LV_Blk_re_Seite_def : 35|1@1+ (1,0) [0|1] ""  Kombi
	SG_ LV_Fernlicht_Anzeige : 14|1@1+ (1,0) [0|1] ""  Fahrerdisplay_Kombi,Kombi
	SG_ LV_Fernlicht_li_def : 23|1@1+ (1,0) [0|1] ""  Kombi
	SG_ LV_Fernlicht_re_def : 33|1@1+ (1,0) [0|1] ""  Kombi
	SG_ LV_FLA_aktiv_Anzeige : 27|1@1+ (1,0) [0|1] ""  Fahrerdisplay_Kombi,Kombi
	SG_ LV_FLA_defekt : 28|1@1+ (1,0) [0|1] ""  Kombi
	SG_ LV_FLA_Sensor_blockiert : 29|1@1+ (1,0) [0|1] ""  Kombi
	SG_ LV_LED_Scheinwerfer_li_def : 50|1@1+ (1,0) [0|1] ""  Kombi
	SG_ LV_LED_Scheinwerfer_re_def : 51|1@1+ (1,0) [0|1] ""  Kombi
	SG_ LV_MXB_Status_Anzeige : 54|2@1+ (1,0) [0|3] ""  Kombi
	SG_ LV_Nebellicht_Anzeige : 15|1@1+ (1,0) [0|1] ""  Kombi
	SG_ LV_Nebellicht_li_def : 24|1@1+ (1,0) [0|1] ""  Kombi
	SG_ LV_Nebellicht_re_def : 34|1@1+ (1,0) [0|1] ""  Kombi
	SG_ LV_Nebellicht_TFL_li_def : 39|1@1+ (1,0) [0|1] ""  Kombi
	SG_ LV_Nebellicht_TFL_re_def : 43|1@1+ (1,0) [0|1] ""  Kombi
	SG_ LV_Nebelschlusslicht_Anzeige : 16|1@1+ (1,0) [0|1] ""  Kombi
	SG_ LV_Standlicht_Anzeige : 12|1@1+ (1,0) [0|1] ""  Kombi
	SG_ LV_Standlicht_li_def : 21|1@1+ (1,0) [0|1] ""  Kombi
	SG_ LV_Standlicht_re_def : 31|1@1+ (1,0) [0|1] ""  Kombi
	SG_ LV_Standlicht_TFL_li_def : 40|1@1+ (1,0) [0|1] ""  Kombi
	SG_ LV_Standlicht_TFL_re_def : 44|1@1+ (1,0) [0|1] ""  Kombi
	SG_ LV_Tagfahrlicht_Anzeige : 17|1@1+ (1,0) [0|1] ""  Kombi
	SG_ LV_Tagfahrlicht_li_def : 26|1@1+ (1,0) [0|1] ""  Kombi
	SG_ LV_Tagfahrlicht_re_def : 36|1@1+ (1,0) [0|1] ""  Kombi

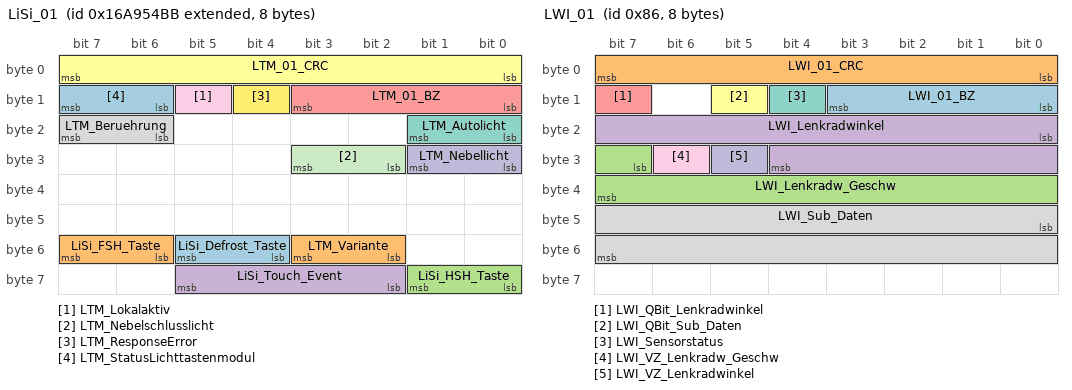
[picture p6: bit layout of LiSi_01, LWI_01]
BO_ 2527679675 LiSi_01: 8 ICAS1_X_Gateway
	SG_ LiSi_Defrost_Taste : 52|2@1+ (1,0) [0|3] ""  Vector__XXX
	SG_ LiSi_FSH_Taste : 54|2@1+ (1,0) [0|3] ""  Vector__XXX
	SG_ LiSi_HSH_Taste : 56|2@1+ (1,0) [0|3] ""  Vector__XXX
	SG_ LiSi_Touch_Event : 58|4@1+ (1,0) [0|15] ""  ICAS3_Gateway,ICC_IO_Node
	SG_ LTM_01_BZ : 8|4@1+ (1,0) [0|15] ""  Vector__XXX
	SG_ LTM_01_CRC : 0|8@1+ (1,0) [0|255] ""  Vector__XXX
	SG_ LTM_Autolicht : 16|2@1+ (1,0) [0|3] ""  Vector__XXX
	SG_ LTM_Beruehrung : 22|2@1+ (1,0) [0|3] ""  Vector__XXX
	SG_ LTM_Lokalaktiv : 13|1@1+ (1,0) [0|1] ""  Vector__XXX
	SG_ LTM_Nebellicht : 24|2@1+ (1,0) [0|3] ""  Vector__XXX
	SG_ LTM_Nebelschlusslicht : 26|2@1+ (1,0) [0|3] ""  Vector__XXX
	SG_ LTM_ResponseError : 12|1@1+ (1,0) [0|1] ""  Vector__XXX
	SG_ LTM_StatusLichttastenmodul : 14|2@1+ (1,0) [0|3] ""  Vector__XXX
	SG_ LTM_Variante : 50|2@1+ (1,0) [0|3] ""  Vector__XXX

BO_ 134 LWI_01: 8 ICAS1_X_Gateway
	SG_ LWI_01_BZ : 8|4@1+ (1,0) [0|15] ""  Vector__XXX
	SG_ LWI_01_CRC : 0|8@1+ (1,0) [0|255] ""  Vector__XXX
	SG_ LWI_Lenkradw_Geschw : 31|9@1+ (5,0) [0|2500] "DegreOfArcPerSecon"  ZR_MIB_TOP_ab_Gen3
	SG_ LWI_Lenkradwinkel : 16|13@1+ (0.1,0) [0|800] "DegreOfArc"  ICAS3_Gateway,ZR_MIB_TOP_ab_Gen3
	SG_ LWI_QBit_Lenkradwinkel : 15|1@1+ (1,0) [0|1] ""  ICAS3_Gateway,ZR_MIB_TOP_ab_Gen3
	SG_ LWI_QBit_Sub_Daten : 13|1@1+ (1,0) [0|1] ""  Vector__XXX
	SG_ LWI_Sensorstatus : 12|1@1+ (1,0) [0|1] ""  ICAS3_Gateway,ZR_MIB_TOP_ab_Gen3
	SG_ LWI_Sub_Daten : 40|16@1+ (1,0) [0|65535] ""  Vector__XXX
	SG_ LWI_VZ_Lenkradw_Geschw : 30|1@1+ (1,0) [0|1] ""  ZR_MIB_TOP_ab_Gen3
	SG_ LWI_VZ_Lenkradwinkel : 29|1@1+ (1,0) [0|1] ""  ICAS3_Gateway,ZR_MIB_TOP_ab_Gen3

BO_TX_BU_ 1646 :ICAS1_X_Gateway;
BO_TX_BU_ 1649 :ICAS1_X_Gateway;
BO_TX_BU_ 1640 :ICAS1_X_Gateway;
BO_TX_BU_ 2527679635 :ICAS1_X_Gateway;
BO_TX_BU_ 1505 :ICAS1_X_Gateway;
BO_TX_BU_ 2549088521 :Fahrerdisplay_Kombi;
BO_TX_BU_ 2549088272 :ICAS1_X_Gateway;
BO_TX_BU_ 2549088283 :HUD;
BO_TX_BU_ 2549088371 :ICAS3_Gateway,ICC_IO_Node,ZR_MIB_TOP_ab_Gen3;
BO_TX_BU_ 2549088276 :Kombi;
BO_TX_BU_ 2549088524 :SmartLight_01;
BO_TX_BU_ 779 :Kombi;
BO_TX_BU_ 1719 :Kombi;
BO_TX_BU_ 1720 :Kombi;
BO_TX_BU_ 2527679639 :Kombi;
BO_TX_BU_ 2589283631 :Kombi;
BO_TX_BU_ 1614 :Kombi;
BO_TX_BU_ 2621702408 :ICAS1_X_Gateway;
BO_TX_BU_ 2621833480 :ICAS3_Gateway;
BO_TX_BU_ 2621440371 :ICAS1_X_Gateway;
BO_TX_BU_ 2621571443 :ICC_IO_Node,ZR_MIB_TOP_ab_Gen3;
BO_TX_BU_ 2621440276 :ICAS1_X_Gateway;
BO_TX_BU_ 2621571348 :Kombi;
BO_TX_BU_ 2549899278 :ICAS1_X_Gateway;
BO_TX_BU_ 2550030350 :ICAS3_Gateway,ICC_IO_Node,ZR_MIB_TOP_ab_Gen3;
BO_TX_BU_ 2549875053 :ICAS1_X_Gateway;
BO_TX_BU_ 2550006125 :ZR_MIB_TOP_ab_Gen3;
BO_TX_BU_ 919 :ICAS1_X_Gateway;
BO_TX_BU_ 810 :ICAS1_X_Gateway;
BO_TX_BU_ 981 :ICAS1_X_Gateway;
BO_TX_BU_ 982 :ICAS1_X_Gateway;
BO_TX_BU_ 1624 :ICAS1_X_Gateway;
BO_TX_BU_ 2527679675 :ICAS1_X_Gateway;
BO_TX_BU_ 134 :ICAS1_X_Gateway;
CM_ BO_ 1646 "ab MQB 7.3";
CM_ BO_ 1640 "ab MQB IS-4";
CM_ BO_ 1505 "ab MQB 7.3";
CM_ BO_ 779 "MQB";
CM_ BO_ 919 "ab MQB ohne CHK/BZ, LDW_SW_Warnung_links/rechts, KD-Fehler und mit Zyklus 100ms";
CM_ BO_ 810 "MQB: 50ms (fï?½r CAN-SG), geï?½ndertes Charisma, Entfall KD-Fehler";
CM_ BO_ 982 "MQB";
CM_ BO_ 134 "ab MQB mit CRC in Byte 1";
CM_ SG_ 1646 KL_Anf_AussenspiegelHzg "Anforderung Auï?½enspiegelheizung seitens Klimafunktion (z.B. bei Erweiterter VoKo)";
CM_ SG_ 1646 KL_BCmE_Livetip_Freigabe "Status der Klimaanlage. \nZeigt an, ob der Livetip 'Fenster schlieï?½en wegen Ineffizienz Klimaanlage' sinvollerweise angezeigt werden soll";
CM_ SG_ 1646 KL_ErwVK_Anf "Erweiterte Voko angefordertert / aktiv";
CM_ SG_ 1646 KL_FSH_Automatikbetrieb "Ermï?½glicht eine Unterscheidung von Anforderung FSH durch Kundenwunsch und Anforderung FSH durch Regelung des Klimasteuergerï?½ts.\nDas Signal liegt als Pegel an.";
CM_ SG_ 1646 KL_Geblaese_Fond_Status "Status Geblaese\n\n\n\n\n\n\n\n\n\n";
CM_ SG_ 1646 KL_Geblaese_Status "Status Geblaese\n\n\n\n\n\n\n\n\n\n";
CM_ SG_ 1646 KL_Heizkreisventilstellung "Bei MQB PHEV: Stellung Heizkreisventil Motor";
CM_ SG_ 1646 KL_I_Geblaese_Fond "Stromaufnahme Geblï?½se Heck";
CM_ SG_ 1646 KL_Innen_Temp "Innentemperatur\n\n";
CM_ SG_ 1646 KL_Kompressorkupplung "Signal zur Aktivierung/Deaktivierung der Kompressorkupplung";
CM_ SG_ 1646 KL_Magnetventil "Anforderung des Bypassventils.";
CM_ SG_ 1646 KL_Restwaerme_aktiv "Signal zur Aktivierung/Deaktivierung der Wasserpumpe bei Restwï?½rme; \nreduzierte IRï?½ Empfindlichkeit";
CM_ SG_ 1646 KL_SH_Soll_hl "Einstellung Sitzheizung hinten links (0...6)";
CM_ SG_ 1646 KL_SH_Soll_hr "Einstellung Sitzheizung hinten rechts (0...6)";
CM_ SG_ 1646 KL_SIH_LEH_Verteilung_VL "Vom Kunden eingestellte Aufteilung der Heizleistung auf Sitzflï?½che und Lehneflï?½che fï?½r Sitz vorne links";
CM_ SG_ 1646 KL_SIH_LEH_Verteilung_VR "Vom Kunden eingestellte Aufteilung der Heizleistung auf Sitzflï?½che und Lehneflï?½che fï?½r Sitz vorne rechts";
CM_ SG_ 1646 KL_SIH_LEL_Verteilung_VL "Vom Kunden eingestellte Aufteilung der Lï?½ftungsleistung auf Sitzflï?½che und Lehnenflï?½che fï?½r Sitz vorne links";
CM_ SG_ 1646 KL_SIH_LEL_Verteilung_VR "Vom Kunden eingestellte Aufteilung der Lï?½ftungsleistung auf Sitzflï?½che und Lehnenflï?½che fï?½r Sitz vorne rechts";
CM_ SG_ 1646 KL_Solarluefter_aktiv "Betriebsstatus Solarluefter\n";
CM_ SG_ 1646 KL_STH_aktiv "Betriebsstatus Standheizung\n";
CM_ SG_ 1646 KL_STH_Ansteuerung "Ansteuerung STH\n\n";
CM_ SG_ 1646 KL_STH_Betriebsdauer "Betriebsdauer STH";
CM_ SG_ 1646 KL_STL_aktiv "Betriebsstatus Standlueftung\n";
CM_ SG_ 1646 KL_Umluft_Taste "Betaetigung Umlufttaste\n";
CM_ SG_ 1646 KL_WaPu "Ansteuerung der Standheizungswasserpumpe";
CM_ SG_ 1649 KL_Betriebsmodus_FH "Synchronisation des Betriebsmodus zwischen Front und Fond";
CM_ SG_ 1649 KL_ErwVK_Beifahrerzone "Erweiterte Voko Beifahrerseite";
CM_ SG_ 1649 KL_ErwVK_Fahrerzone "Erweiterte Voko Fahrerseite";
CM_ SG_ 1649 KL_ErwVK_Heckzone_links "Erweiterte Voko Heckzone links";
CM_ SG_ 1649 Kl_ErwVK_Heckzone_rechts "Erweiterte Voko Heckzone rechts.";
CM_ SG_ 1649 KL_ErwVK_Scheibenheizung "Erweiterte Voko Scheibenheizung";
CM_ SG_ 1649 KL_ErwVK_Status "Erweiterte Voko angefordert fï?½r\nFahrerzone_aktiv\nAlle Zonen_aktiv\nBeifahrerzone_aktiv\nHeckzone_aktiv\nScheibenheizung_aktiv";
CM_ SG_ 1649 KL_Hinweis_Kuehlmodus "Signal generiert einen Kundenhinweis, ob eine normale Klimatisierung umgesetzt werden kann, oder ein Sondermodus aktiv ist";
CM_ SG_ 1649 KL_Meldung_Status "Klima gibt den Status der Fahrermeldungen aus.";
CM_ SG_ 1649 KL_STH_Betriebsdauer_lang "Betriebsdauer STH im Falle eines mï?½glichen 120min Betriebes.";
CM_ SG_ 1649 KL_Stopp_Wiederstart_Anz_01 "Dieses Signal gibt die detaillierte Begrï?½ndung fï?½r eine Stoppverbot-/Wiederstartanfrage der Klima-SG an.";
CM_ SG_ 1649 KL_Stopp_Wiederstart_Anz_02 "Dieses Signal gibt die detaillierte Begrï?½ndung fï?½r eine Stoppverbot-/Wiederstartanfrage der Klima-SG an.";
CM_ SG_ 1649 KL_Stopp_Wiederstart_Anz_03 "Dieses Signal gibt die detaillierte Begrï?½ndung fï?½r eine Stoppverbot-/Wiederstartanfrage der Klima-SG an.";
CM_ SG_ 1649 KL_Stopp_Wiederstart_Anz_04 "Dieses Signal gibt die detaillierte Begrï?½ndung fï?½r eine Stoppverbot-/Wiederstartanfrage der Klima-SG an.";
CM_ SG_ 1649 KL_Stopp_Wiederstart_Anz_05 "Dieses Signal gibt die detaillierte Begrï?½ndung fï?½r eine Stoppverbot-/Wiederstartanfrage der Klima-SG an.";
CM_ SG_ 1649 KL_Stopp_Wiederstart_Anz_06 "Dieses Signal gibt die detaillierte Begrï?½ndung fï?½r eine Stoppverbot-/Wiederstartanfrage der Klima-SG an.";
CM_ SG_ 1649 KL_Stopp_Wiederstart_Anz_07 "Dieses Signal gibt die detaillierte Begrï?½ndung fï?½r eine Stoppverbot-/Wiederstartanfrage der Klima-SG an.";
CM_ SG_ 1649 KL_Stopp_Wiederstart_Anz_08 "Dieses Signal gibt die detaillierte Begrï?½ndung fï?½r eine Stoppverbot-/Wiederstartanfrage der Klima-SG an.";
CM_ SG_ 1649 KL_Stopp_Wiederstart_Anz_09 "Dieses Signal gibt die detaillierte Begrï?½ndung fï?½r eine Stoppverbot-/Wiederstartanfrage der Klima-SG an.";
CM_ SG_ 1649 KL_Stopp_Wiederstart_Anz_Std1 "Dieses Signal gibt die detaillierte Begrï?½ndung fï?½r eine Stoppverbot-/Wiederstartanfrage der Klima-SG an.";
CM_ SG_ 1649 KL_Stopp_Wiederstart_Anz_Std2 "Dieses Signal gibt die detaillierte Begrï?½ndung fï?½r eine Stoppverbot-/Wiederstartanfrage der Klima-SG an.";
CM_ SG_ 1649 KL_ZZ_Betriebsmodus "Betriebsdauerberechnung anhand Aussentemperaturauswertung mit Faktor 'ZZ_Betriebsmodus'";
CM_ SG_ 1649 KL_ZZ_Minute "Zielzeittimeranzeige im Display der Funkfernbedienung (Minute); Initwert ist der zuletzt gï?½ltige Wert";
CM_ SG_ 1649 KL_ZZ_Monat "Zielzeittimeranzeige im Display der Funkfernbedienung (Datum, Monat); Initwert ist der zuletzt gï?½ltige Wert";
CM_ SG_ 1649 KL_ZZ_Status_Timer "Timerstatusanzeige im Display der Funkfernbedienung (Timer aktiv/n.aktiv)";
CM_ SG_ 1649 KL_ZZ_Stunde "Zielzeittimeranzeige im Display der Funkfernbedienung (Stunde); Initwert ist der zuletzt gï?½ltige Wert";
CM_ SG_ 1649 KL_ZZ_Tag "Zielzeittimeranzeige im Display der Funkfernbedienung (Datum, Tag); Initwert ist der zuletzt gï?½ltige Wert";
CM_ SG_ 1640 FSH_Taster "Tasterbetï?½tigung Frontscheibenheizung\n";
CM_ SG_ 1640 HSH_Taster "An-/Abforderung Heckscheibenheizung ï?½ber spezielles Tastersignal\n";
CM_ SG_ 1640 KL_Beschlagsgefahr "Beschlagsgefahr auf der Frontscheibe im Bereich des Spiegelfusses. Dient zur prï?½ventiven Ansteuerung der  Kamera-Scheibenheizung, um Kamera-Blindheit zu vermeiden\nPHEV: volle Leistungsfreigabe \nHV Heizer und HV EKK bei Scheibenbeschlag ";
CM_ SG_ 1640 KL_Geblspng_Fond_Soll "Ausgabe des Sollwertes fï?½r die Spannung des Klimageblï?½semotores hinten.\n\n\n\n\n\n\n";
CM_ SG_ 1640 KL_Geblspng_Soll "Ausgabe des Sollwertes fï?½r die Spannung des Klimageblï?½semotores vorne.\n\n\n\n\n\n\n\n";
CM_ SG_ 1640 KL_I_Geblaese "Stromaufnahme Geblï?½se";
CM_ SG_ 1640 KL_Kompressorstrom_soll "Sollvorgabe Klima-Kompressorstrom";
CM_ SG_ 1640 KL_LRH_Stufe "Eingestellte Temperaturstufe der Lenkradheizung";
CM_ SG_ 1640 KL_LRH_Taster "Tasterbetï?½tigung Lenkradheizung";
CM_ SG_ 1640 KL_PTC_Verbauinfo "Im Klima- bzw. Heizungsbedienteil wird der Verbau eines PTCs und dessen elektr. Leistungsklasse codiert";
CM_ SG_ 1640 KL_SIH_Soll_li "Einstellung Sitzheizung Fahrer (0...6)";
CM_ SG_ 1640 KL_SIH_Soll_re "Einstellung Sitzheizung Beifahrer (0...6)";
CM_ SG_ 1640 KL_SIL_Soll_li "Einstellung Sitzlï?½ftung Fahrer (0...6)";
CM_ SG_ 1640 KL_SIL_Soll_re "Einstellung Sitzlï?½ftung Beifahrer (0...6)";
CM_ SG_ 1640 KL_Umluftklappe_Status "Status Umluftklappe";
CM_ SG_ 1640 KL_Zuheizer_Freigabe "Freigabe Zuheizer\n";
CM_ SG_ 1640 KRH_Soll_li "Ausgabe des Sollwertes fï?½r die Kopfraumheizung links.";
CM_ SG_ 1640 KRH_Soll_re "Ausgabe des Sollwertes fï?½r die Kopfraumheizung rechts.";
CM_ SG_ 2527679635 FSH_Status "Fehlerstatus der Frontscheibenheizung\n";
CM_ SG_ 2527679635 HSH_Relais_Anf "Relaisanforderung Heckscheibenheizung";
CM_ SG_ 2527679635 KL_AL_HL_Anf "Anforderung an das funktionale Ambientelicht eine Solltemperaturverï?½nderung hinten links darzustellen.";
CM_ SG_ 2527679635 KL_AL_HR_Anf "Anforderung an das funktionale Ambientelicht eine Solltemperaturverï?½nderung hinten rechts darzustellen.";
CM_ SG_ 2527679635 KL_AL_VL_Anf "Anforderung an das funktionale Ambientelicht eine Solltemperaturverï?½nderung vorn links darzustellen.";
CM_ SG_ 2527679635 KL_AL_VR_Anf "Anforderung an das funktionale Ambientelicht eine Solltemperaturverï?½nderung vorn rechts darzustellen.";
CM_ SG_ 2527679635 KL_Defrost_LED "Beleuchtung LED Defrost";
CM_ SG_ 2527679635 KL_FSH_LED "Beleuchtung LED Frontscheibenheizung";
CM_ SG_ 2527679635 KL_FSH_Soll "Sollstatus der Frontscheibenheizung";
CM_ SG_ 2527679635 KL_Heizstufe_LSH "Vom Klimabedienteil gesendete Heizstufe der Luftstandheizung";
CM_ SG_ 2527679635 KL_HSH_LED "Beleuchtung LED Heckscheibenheizung";
CM_ SG_ 2527679635 KL_HSH_Soll "Sollstatus Heckscheibenheizung";
CM_ SG_ 2527679635 KL_HUP_aktiv "Signal des Klimabedienteils ob HUP aktiv ist.\n\n0 = HUP aus\n1 = HUP ein";
CM_ SG_ 2527679635 KL_Klappe_Status "Status Luftklappe";
CM_ SG_ 2527679635 KL_LRH_PWM "LRH PWM Signal zur Ansteuerung der Treiberstufe im SMLS (0% - 100%)";
CM_ SG_ 2527679635 KL_LRH_Soll "Sollstatus der Lenkradheizung";
CM_ SG_ 2527679635 KL_LSH_Ansteuerung "Ansteuerung LSH";
CM_ SG_ 2527679635 KL_LSH_Betriebsdauer "Betriebsdauer LSH";
CM_ SG_ 2527679635 KL_LSH_DBetr_Bestaet "Bestï?½tigung des Klimabedienteils an die LSH das Dauerbetrieb tatsï?½chlich angefordert ist.";
CM_ SG_ 2527679635 KL_LSH_DBetr_Ein "Dauerbetrieb der Luftstandheizung Ein";
CM_ SG_ 2527679635 KL_Temp_ZH_Soll "ï?½bertragung der Temperaturvorgabe der Klimaanlage an die Wasserzusatzheizung";
CM_ SG_ 2527679635 KL_VoKo_LED "Signalisierung Vorkonditionierung";
CM_ SG_ 2527679635 KL_Voko_Status "Status der Vorkonditionierung.\n\n0 = aus\n1 = ein\n\n14 = Init\n15 = Fehler";
CM_ SG_ 2527679635 KL_ZR_Anforderung "Anforderung an MIB die Displays zu aktivieren";
CM_ SG_ 2527679635 SIH_Stufe_LED_li "Statusmeldung Sitzheizung links";
CM_ SG_ 2527679635 SIH_Stufe_LED_re "Statusmeldung Sitzheizung rechts";
CM_ SG_ 1505 BCM1_Aussen_Temp_ungef "ungefilterter Wert des Aussentemperatursensors\n";
CM_ SG_ 1505 BCM1_FStatus_Aussentemp_ungef "Fehlerstatus fï?½r Aussentemperatur (Kombianzeige)";
CM_ SG_ 1505 BCM1_Kompressorstrom_ist "IST-Strom vom Klima-Kompressor";
CM_ SG_ 1505 BCM1_OBD_FStatus_ATemp "Fehlerstatus Umgebungstemperatursensor (OBD relevanter Sensor)\n";
CM_ SG_ 1505 BCM1_PTC_stufig_Status "Status des BCM1-Heizverbrauchers PTC (stufig)";
CM_ SG_ 1505 BCM_Heizungsabsperrventil_Status "Das Signal beschreibt den Zustand des Heizungsabsperrventils, welches als Portexpander vom BCM1 elektrisch angesteuert wird.";
CM_ SG_ 1505 BCM_Heizungspumpe_Status "Das Signal beschreibt den Zustand der Heizungspumpe, welche als Portexpander vom BCM1 elektrisch angesteuert wird.";
CM_ SG_ 1505 BCM_Kompressorkupplung_Status "Das Signal beschreibt den Zustand der Klimakompressorkupplung, welche als Portexpander vom BCM1 elektrisch angesteuert wird.";
CM_ SG_ 2549088521 DispKBI_FS_Abschaltstufe "Funktionseinschrï?½nkung aufgrund aktiver Abschaltstufe";
CM_ SG_ 2549088521 DispKBI_FS_KD_Fehler "Bei gesetztem Bit ist mindestens ein Kundendienstfehler eingetragen";
CM_ SG_ 2549088521 DispKBI_FS_KompSchutz "Funktionseinschrï?½nkung aufgrund Komponentenschutz aktiv";
CM_ SG_ 2549088521 DispKBI_FS_Nachlauftyp "Abgebildet wird die von der Hardware vorgegebene Mï?½glichkeit, die Kommunikation nach Klemme 15 = AUS aufrecht zu erhalten. Es wird ein Init-Wert gesendet.";
CM_ SG_ 2549088521 DispKBI_FS_Transport_Mode "Funktionseinschrï?½nkung aufgrund aktivem Transport Mode und/oder Transport Schutz";
CM_ SG_ 2549088521 KN_DispKBI_FS_BusKnockOut "Ausgabe des BusKnockout-Status";
CM_ SG_ 2549088521 KN_DispKBI_FS_BusKnockOutTimer "Ausgabe des BusKnockOut-Timer";
CM_ SG_ 2549088521 KN_DispKBI_FS_DiagPfad "Kennzeichnung der Diagnosefï?½higkeit des BusInterfaces eines Steuergerï?½tes (Knoten)\nUmfang LAH 80127\n\nBei Nutzung des Signal explizit pro angebundenem BusInterface zu setzen:\nE_1_1_MEB auf AB-CANFD = 0 (aktiv)\nE_1_1_UNECE auf AB-CANFD = 0 (aktiv)";
CM_ SG_ 2549088521 KN_DispKBI_FS_ECUKnockOut "Ausgabe des ECUKnockout-Status";
CM_ SG_ 2549088521 KN_DispKBI_FS_ECUKnockOutTimer "Ausgabe des ECUKnockOut-Timer";
CM_ SG_ 2549088521 NM_DispKBI_FS_Wakeup "enthï?½lt die Weckursache; stehen mehrere Weckursachen parallel an, dann muss der kleinste Wert ï?½bertragen werden";
CM_ SG_ 2549088272 Gateway_Abschaltstufe "Funktionseinschrï?½nkung aufgrund aktiver Abschaltstufe";
CM_ SG_ 2549088272 Gateway_KompSchutz "Funktionseinschrï?½nkung aufgrund Komponentenschutz aktiv";
CM_ SG_ 2549088272 Gateway_Nachlauftyp "Abgebildet wird die von der Hardware vorgegebene Mï?½glichkeit, die Kommunikation nach Klemme 15 = AUS aufrecht zu erhalten. Es wird ein Init-Wert gesendet.";
CM_ SG_ 2549088272 Gateway_Transport_Mode "Funktionseinschrï?½nkung aufgrund aktivem Transport Mode und/oder Transport Schutz";
CM_ SG_ 2549088272 GW_KD_Fehler "Kundendienstfehlerbit Gateway zur Anzeige eines im Gateway abgelegten Fehlerspeichereintrages.";
CM_ SG_ 2549088272 KN_GW_DiagPfad "Kennzeichnung der Diagnosefï?½higkeit des BusInterfaces eines Steuergerï?½tes (Knoten)\nUmfang LAH 80127\n\nBei Nutzung des Signal explizit pro angebundenem BusInterface zu setzen:\nMQB auf Diag-CAN = 0 (aktiv)\nMLBevo auf Diag-CAN = 0 (aktiv)\nalle weiteren ";
CM_ SG_ 2549088272 NM_Gateway_Wakeup "enthï?½lt die Weckursache; stehen mehrere Weckursachen parallel an, dann muss der kleinste Wert ï?½bertragen werden";
CM_ SG_ 2549088283 HUD_Abschaltstufe "Funktionseinschrï?½nkung aufgrund aktiver Abschaltstufe";
CM_ SG_ 2549088283 HUD_KD_Fehler "Bei gesetztem Bit ist mindestens ein Kundendienstfehler eingetragen";
CM_ SG_ 2549088283 HUD_KompSchutz "Funktionseinschrï?½nkung aufgrund Komponentenschutz aktiv";
CM_ SG_ 2549088283 HUD_Nachlauftyp "Abgebildet wird die von der Hardware vorgegebene Mï?½glichkeit, die Kommunikation nach Klemme 15 = AUS aufrecht zu erhalten. Es wird ein Init-Wert gesendet.";
CM_ SG_ 2549088283 HUD_Transport_Mode "Funktionseinschrï?½nkung aufgrund aktivem Transport Mode und/oder Transport Schutz\n";
CM_ SG_ 2549088283 KN_HUD_BusKnockOut "Ausgabe des BusKnockout-Status";
CM_ SG_ 2549088283 KN_HUD_BusKnockOutTimer "Ausgabe des BusKnockOut-Timer";
CM_ SG_ 2549088283 KN_HUD_DiagPfad "Kennzeichnung der Diagnosefï?½higkeit des BusInterfaces eines Steuergerï?½tes (Knoten)\nUmfang LAH 80127\n\nBei Nutzung des Signal explizit pro angebundenem BusInterface zu setzen:\nMQB auf K-CAN = 0 (aktiv)\nMQB2020 auf K-CAN = 0 (aktiv)\nMQB2020 auf VLAN-Ko";
CM_ SG_ 2549088283 KN_HUD_ECUKnockOut "Ausgabe des ECUKnockout-Status";
CM_ SG_ 2549088283 KN_HUD_ECUKnockOutTimer "Ausgabe des ECUKnockOut-Timer";
CM_ SG_ 2549088283 NM_HUD_Wakeup "enthï?½lt die Weckursache; stehen mehrere Weckursachen parallel an, dann muss der kleinste Wert ï?½bertragen werden";
CM_ SG_ 2549088371 Info_El_Abschaltstufe "Funktionseinschrï?½nkung aufgrund aktiver Abschaltstufe";
CM_ SG_ 2549088371 Info_El_KD_Fehler "Bei gesetztem Bit ist mindestens ein Kundendienstfehler eingetragen";
CM_ SG_ 2549088371 Info_El_KompSchutz "Funktionseinschrï?½nkung aufgrund Komponentenschutz aktiv";
CM_ SG_ 2549088371 Info_El_Nachlauftyp "Abgebildet wird die von der Hardware vorgegebene Mï?½glichkeit, die Kommunikation nach Klemme 15 = AUS aufrecht zu erhalten. Es wird ein Init-Wert gesendet.";
CM_ SG_ 2549088371 Info_El_Transport_Mode "Funktionseinschrï?½nkung aufgrund aktivem Transport Mode und/oder Transport Schutz";
CM_ SG_ 2549088371 KN_Info_El_BusKnockOutTimer "Ausgabe des BusKnockOut-Timer";
CM_ SG_ 2549088371 KN_Info_El_DiagPfad "Kennzeichnung der Diagnosefï?½higkeit des BusInterfaces eines Steuergerï?½tes (Knoten)\nUmfang LAH 80127\n\nBei Nutzung des Signal explizit pro angebundenem BusInterface zu setzen:\nMQB AB auf I-CAN = 0 (aktiv)\nMQB A0 auf K-CAN = 0 (aktiv)\nMQB2020 auf I-CAN";
CM_ SG_ 2549088371 NM_Info_El_Wakeup "enthï?½lt die Weckursache; stehen mehrere Weckursachen parallel an, dann muss der kleinste Wert ï?½bertragen werden";
CM_ SG_ 2549088276 KN_KBI_DiagPfad "Kennzeichnung der Diagnosefï?½higkeit des BusInterfaces eines Steuergerï?½tes (Knoten)\nUmfang LAH 80127\n\nBei Nutzung des Signal explizit pro angebundenem BusInterface zu setzen:\nMLBevoGen1 auf I-CAN = 0 (aktiv)\nMLBevoGen2 auf D-CAN = 0 (aktiv)\nMQB auf K";
CM_ SG_ 2549088276 KN_Kombi_BusKnockOut "Ausgabe des BusKnockout-Status in der Knotenbotschaft";
CM_ SG_ 2549088276 KN_Kombi_BusKnockOutTimer "Ausgabe des BusKnockOut-Timer in der Knotenbotschaft";
CM_ SG_ 2549088276 KN_Kombi_ECUKnockOut "Ausgabe des ECUKnockout-Status in der Knotenbotschaft";
CM_ SG_ 2549088276 KN_Kombi_ECUKnockOutTimer "Ausgabe des ECUKnockOut-Timer in der Knotenbotschaft";
CM_ SG_ 2549088276 Kombi_Abschaltstufe "Funktionseinschrï?½nkung aufgrund aktiver Abschaltstufe";
CM_ SG_ 2549088276 Kombi_KompSchutz "Funktionseinschrï?½nkung aufgrund Komponentenschutz aktiv";
CM_ SG_ 2549088276 Kombi_Nachlauftyp "Abgebildet wird die von der Hardware vorgegebene Mï?½glichkeit, die Kommunikation nach Klemme 15 = AUS aufrecht zu erhalten. Es wird ein Init-Wert gesendet.";
CM_ SG_ 2549088276 Kombi_Transport_Mode "Funktionseinschrï?½nkung aufgrund aktivem Transport Mode und/oder Transport Schutz";
CM_ SG_ 2549088276 NM_Kombi_Lokalaktiv "Zeigt an ob das SG nach Klemme15 AUS und nach entsprechender MAX Aktivzeit noch aktiv war";
CM_ SG_ 2549088276 NM_Kombi_Subsystemaktiv "Zeigt an ob ein Subsystem des SGs nach Klemme15 AUS und nach entsprechender MAX Aktivzeit noch aktiv war";
CM_ SG_ 2549088276 NM_Kombi_Wakeup "enthï?½lt die Weckursache; stehen mehrere Weckursachen parallel an, dann muss der kleinste Wert ï?½bertragen werden";
CM_ SG_ 2549088524 KN_SmLi_01_DiagPfad "Kennzeichnung der Diagnosefï?½higkeit des BusInterfaces eines Steuergerï?½tes (Knoten)\nUmfang LAH 80127\n\nBei Nutzung des Signal explizit pro angebundenem BusInterface zu setzen:\nE3_1_1_MEB auf AB-CANFD = 0 (aktiv)\nE3_1_1_UNECE auf AB-CANFD = 0 (aktiv)";
CM_ SG_ 2549088524 KN_SmLi_BusKnockOut "Ausgabe des BusKnockout-Status in der Knotenbotschaft";
CM_ SG_ 2549088524 KN_SmLi_BusKnockOutTimer "Ausgabe des BusKnockOut-Timer in der Knotenbotschaft";
CM_ SG_ 2549088524 KN_SmLi_ECUKnockOut "Ausgabe des ECUKnockout-Status in der Knotenbotschaft";
CM_ SG_ 2549088524 KN_SmLi_ECUKnockOutTimer "Ausgabe des ECUKnockOut-Timer in der Knotenbotschaft";
CM_ SG_ 2549088524 NM_SmLi_01_Wakeup "enthï?½lt die Weckursache; stehen mehrere Weckursachen parallel an, dann muss der kleinste Wert ï?½bertragen werden";
CM_ SG_ 2549088524 SmLi_01_Abschaltstufe "Funktionseinschrï?½nkung aufgrund aktiver Abschaltstufe";
CM_ SG_ 2549088524 SmLi_01_KD_Fehler "Bei gesetztem Bit ist mindestens ein Kundendienstfehler eingetragen";
CM_ SG_ 2549088524 SmLi_01_KompSchutz "Funktionseinschrï?½nkung aufgrund Komponentenschutz aktiv";
CM_ SG_ 2549088524 SmLi_01_Nachlauftyp "Abgebildet wird die von der Hardware vorgegebene Mï?½glichkeit, die Kommunikation nach Klemme 15 = AUS aufrecht zu erhalten. Es wird ein Init-Wert gesendet.";
CM_ SG_ 2549088524 SmLi_01_Transport_Mode "Funktionseinschrï?½nkung aufgrund aktivem Transport Mode und/oder Transport Schutz";
CM_ SG_ 779 KBI_Anzeigefehler_SWA "Signal bezieht sich nur auf die SWA-Lampe, Vorhalt fï?½r Kombis mit SWA-Lampe. ";
CM_ SG_ 779 KBI_ARA_in_Anzeige "Anzeige von ARA im Kombi aktiv";
CM_ SG_ 779 KBI_Einheit_Tacho "Information, ob es sich um Meilen- oder Kmh-Kombi handelt, Einheit des Tachos entspricht dem Zifferblatt, Grï?½sse ist nicht verï?½nderlich";
CM_ SG_ 779 KBI_Handbremse "Handbremsen-Information vom Kombi.\nDas Signal bezieht sich ausschlieï?½lich auf den Zustand der konventionellen Handbremse.";
CM_ SG_ 779 KBI_MFA_v_Einheit_01 "Einheit der Geschwindigkeit, die vom Fahrer im Car-Menï?½ gewï?½hlt wurde. Verï?½nderliche Grï?½sse, im Gegensatz zur Einheit des Tachokranzes.";
CM_ SG_ 779 KBI_PLA_in_Anzeige "Das Signal wird als aktive Rï?½ckmeldung genutzt, ob die Info des PLA im Kombi angezeigt wird. Wenn nach Anforderung des Displays das Signal zweimal auf 0 ist, wird der Parkvorgang abgebrochen.\nEin Kombi, dass PLA Anzeige nicht unterstï?½tzt, schickt dauerha";
CM_ SG_ 779 KBI_Systemstatus "Signalisiert erkannte FuSi-relevante Fehler im Kombi\n(keinen Ausfall der Akustik oder des Displays)";
CM_ SG_ 779 KBI_Tankwarnung "Fahrer wird gewarnt, dass er den Reservebereich erreicht hat. Fzg.spezifische Warnschwelle";
CM_ SG_ 779 KBI_Tankwarnung_ungueltig "Validiert den Inhalt des Signales KBI_Tankwarnung";
CM_ SG_ 779 KBI_Taster_Fahrwerk "Betï?½tigung Taster 'Fahrwerk' im Kombi";
CM_ SG_ 779 KBI_Taster_Lift "Betï?½tigung Taster 'Lift' im Kombi J1 zur Verarbeitung im Porsche EFP Steuergerï?½t";
CM_ SG_ 779 KBI_V_Digital "Ausgabe der im Kombi angezeigten digitalen Geschwindigkeit.\n\nEinheit ist im KBI_MFA_v_Einheit_01 definiert";
CM_ SG_ 779 KBI_Vorglueh_System_Lampe "Rï?½ckmeldung der Vorglï?½hlampe bzw. Motor Systemlampe (MO_Systemlampe) an den Motor (bei Diesel und Otto!). Hardwaremï?½ssig gleiche LED im Kombi (EPC- oder Glï?½hwendel), Unterscheidung nur ï?½ber Ziffernblatt.";
CM_ SG_ 1719 KBI_FoD_PopUP_Quittiert "Angezeigte FoD-Warnung im Kombi wurde vom Fahrer quittiert; \nSignal wird fï?½r die Dauer von 2 Sekunden gesendet";
CM_ SG_ 1719 KBI_FStatus_Tank "Signal wird gesetzt:\n\na) Wï?½hrend der Fehlerentprellzeit (20 s Entprellung)\n\nb) Bei erkanntem Fehler wird der Tankinhalt wï?½hrend der laufenden KL15-Phase ï?½ber den \nVerbrauch zurï?½ckgerechnet. In dieser Zeit ist das Bit ebenfalls gesetzt. Nach einem";
CM_ SG_ 1720 KBI_GAP_Warn_Zeit_abgelaufen "Die Zeit, z.B. 1460 Tage, bis zur finalen Warnstufe der Gasanlagenprï?½fung wurde berechnet. Berechnung erfolgt auf Basis der aktuellen Uhrzeit mit einem Tageszï?½hler. Keine Berechnung des Zï?½hlers bei Kl.30 AUS.";
CM_ SG_ 1720 KBI_Max_Tankinhalt "Mitteilung des maximalen Tankinhalts an das Reichweitenmodul";
CM_ SG_ 1720 KBI_Nachtanken_erkannt "Statusinformation Nachtankmodus";
CM_ SG_ 1720 KBI_Tankfuellstand_Prozent "Tankfï?½llstand in %";
CM_ SG_ 1720 KBI_Tankinhalt_hochaufl "angezeigter Tankinhalt hochauflï?½send zur Restreichweitenberechnung";
CM_ SG_ 2527679639 AuthTime_Trigger_Distribution "Funktion Authentische Zeit-Verteilung.Broadcast- Triggersignal fï?½r Bekanntgabe an alle Clients, dass ein neuer Zeitstempel im Zeitmaster vorliegt.";
CM_ SG_ 2527679639 KBI_FoD_VirtualCockpitPlus_State "Informs if the function on demand feature 'Virtual Cockpit Plus' is locked or not.";
CM_ SG_ 2527679639 KBI_Min_Tankinhalt "Tankanzeigeleerwert fï?½r Reichweitenberechnung, kein reales Kraftstoffvolumen";
CM_ SG_ 2527679639 KBI_Weg_Zaehler "Inkrementaler Zï?½hler des Kombis\n\nPAG-Plattform:\nSendeart: Cyclic\nZykluszeit: 100ms\n\nMLBevo_Konzern:\nSendeart: OnChange\nZykluszeit: 1000ms\nInhibitzeit: 100ms\n";
CM_ SG_ 2589283631 KBI_BC_Reset_E1 "Signalisierung BC Reset. Bei jedem BC Reset wird um 1 hochgezaehlt, bei 0x6 erfolgt Ueberlauf auf 0x1. Bei SG-Reset und Datenverlust vom BC wird der Wert SG_Reset angenommen. Wï?½hrend der Init-Phase wird Init gesendet, nach der Init-Phase der letzte gï?½ltig";
CM_ SG_ 2589283631 KBI_Tankinhalt_roh "ï?½bertrï?½gt den ungefilterten und kalibrierten Tankinhalt (incl. ï?½berhub im Vollbereich). Die Bereitstellung des Signale erfolgt nicht nach OBD Richtlinien. Die OBD konforme Verarbeitung erfolgt im Empfï?½nger";
CM_ SG_ 1614 KBI_HUD_Data_01 "Kommunikation Kombi zu HUD. Prio.texte zur gleichzeitigen Anzeige im Kombi und HUD.";
CM_ SG_ 1614 KBI_HUD_Data_02 "Kommunikation Kombi zu HUD. Prio.texte zur gleichzeitigen Anzeige im Kombi und HUD.";
CM_ SG_ 1614 KBI_HUD_Data_03 "Kommunikation Kombi zu HUD. Prio.texte zur gleichzeitigen Anzeige im Kombi und HUD.";
CM_ SG_ 1614 KBI_HUD_Data_04 "Kommunikation Kombi zu HUD. Prio.texte zur gleichzeitigen Anzeige im Kombi und HUD.";
CM_ SG_ 1614 KBI_HUD_Data_05 "Kommunikation Kombi zu HUD. Prio.texte zur gleichzeitigen Anzeige im Kombi und HUD.";
CM_ SG_ 1614 KBI_HUD_Data_06 "Kommunikation Kombi zu HUD. Prio.texte zur gleichzeitigen Anzeige im Kombi und HUD.";
CM_ SG_ 1614 KBI_HUD_Data_07 "Kommunikation Kombi zu HUD. Prio.texte zur gleichzeitigen Anzeige im Kombi und HUD.";
CM_ SG_ 1614 KBI_HUD_Data_08 "Kommunikation Kombi zu HUD. Prio.texte zur gleichzeitigen Anzeige im Kombi und HUD.";
CM_ SG_ 2621702408 KS_ICAS3Sys01_Req_FD_Data "ISO-TP FD Datenkanal - FID2NA\nRequest Funktion 0x01 Komponentenschutz an Knoten 0x108";
CM_ SG_ 2621833480 KS_ICAS3Sys01_Resp_FD_Data "ISO-TP FD Datenkanal - FID2NA\nResponse Knoten 0x108 an Funktion 0x01 Komponentenschutz";
CM_ SG_ 2621440371 KS_Info_El_Req_FD_Data "Komponentenschutz ï?½ber ISO TP.";
CM_ SG_ 2621571443 KS_Info_El_Resp_FD_Data "Komponentenschutz ï?½ber ISO TP.";
CM_ SG_ 2621440276 KS_Kombi_Req_FD_Data "ISO-TP FD Datenkanal - FID2NA\nRequest Funktion 0x01 Komponentenschutz an Knoten";
CM_ SG_ 2621571348 KS_Kombi_Resp_FD_Data "ISO-TP FD Datenkanal - FID2NA\nResponse Knoten an Funktion 0x01 Komponentenschutz";
CM_ SG_ 2549899278 KS_SSN_ABT_1_Req_Data "Kompontenschutz DK2 ABT1";
CM_ SG_ 2550030350 KS_SSN_ABT_1_Resp_Data "Komponentenschutz DK2 ABT";
CM_ SG_ 2549875053 KS_TV_Tuner_Req_Data "Komponentenschutz (Funktion 01h). Request mit NA des Slaves.";
CM_ SG_ 2550006125 KS_TV_Tuner_Resp_Data "Komponentenschutz (Funktion 01h). Response mit eigener NA.";
CM_ SG_ 919 aLDW_FoD_Status "Im CBEV wird aLDW durch FoD geschï?½tzt sein und so reicht fï?½r Kombi und HUd die PR/Zieldatencontainer basierte Codierung nicht mehr aus.\n\nAus diesem Grund brauch wir ein separates Signal, dass uns den Freischaltezustand mitteilt.";
CM_ SG_ 919 HC_Uss_Anforderung "Ansteuerung der vorderen PLA (VLS, VRS) und APS Sensoren (VL, VR)\n0 = Ultraschallsensoren Aus\n1 = Ultraschallsensoren An";
CM_ SG_ 919 LDW_DLC "distance to line, Abstand vom Fahrzeug zur Fahrbahnmarkierung\nDer Wert gibt die Breite der Restspur zur Linie wieder (Abstand vom Fahrzeugï?½uï?½erem zur Linie) (Wert POSITIV wenn Fahrzeug in der Spur - Wert NEGATIV wenn Fahrzeug ï?½ber der Linie)";
CM_ SG_ 919 LDW_Frueh_Spaet "Im MMI eingestellter, aktiver Lenkeingriffszeitpunkt:\n0: frueh, frueh aktiv\n1: frueh, spaet aktiv\n2: spaet, spaet aktiv\n3: Fehler";
CM_ SG_ 919 LDW_Gong "Lï?½st ein definiertes akustisches Signal aus.";
CM_ SG_ 919 LDW_Lernmodus_seitenabhaengig "Signal dient zur Ansteuerung von Funktionsanzeigen im Mitteldisplay des Kombiinstruments fï?½r die Seitenabhï?½nige Liniendetektion (neue Funktion ab D4)";
CM_ SG_ 919 LDW_Seite_DLCTLC "Zuordnung auf welche Seite sich LDW_DLC bzw. LDW_TLC beziehen";
CM_ SG_ 919 LDW_Status_Anzeige "Signal dient zur Ansteuerung von Funktionsanzeigen im Mitteldisplay des Kombiinstruments.";
CM_ SG_ 919 LDW_Status_Grid "Im MEB-HUD angezeigtes Grid fï?½r die Anzeige im Lane- und Travel-Assist";
CM_ SG_ 919 LDW_Status_LED_gruen " ";
CM_ SG_ 919 LDW_Texte "Bei Anzeige eines Fehlertextes im Kombi ertï?½nt ein akustisches Signal";
CM_ SG_ 919 LDW_TLC "time to line, Zeit bis das Fahrzeug die Fahrbahnmarkierung ï?½berquert";
CM_ SG_ 810 EPS_01_CRC "Fï?½r MLB:\n'Berechnung siehe Lastenheft 'Kommunikationsabsicherung fï?½r FlexRay und CAN''\n\nAb MQB und MLBevo:\n'Berechnung siehe Lastenheft 'End-to-End Kommunikationsabsicherung''\n\nEndwerte siehe Begleitdokument 'S-PDU Kennungsfolgen'\n";
CM_ SG_ 810 EPS_Akustiksignal "Ansteuerung eines Akustiksignals im Kombi";
CM_ SG_ 810 EPS_Anf_KL "Nach ï?½berschreiten einer oberen Grenztemperatur innerhalb des Steuergerï?½tes der Lenkhilfe fordert die EPS die Zuschaltung einer externen Kï?½hlung durch den Kï?½hlerlï?½fter an.\nEs besteht kein technischer Zusammenhang mit einer Batterie_ab - Erkennung in der ";
CM_ SG_ 810 EPS_ARA_Status "Anforderung vom Anhï?½ngerrangierassistent. \n16 Statuswerte";
CM_ SG_ 810 EPS_Charisma_FahrPr "MLBevo: Aktuelles Fahrprogramm des Charisma-Teilnehmers (siehe Systemlastenheft Drive Select)\nMQB: Istwert der Kennlinie (siehe Systemlastenheft MQB FPA)";
CM_ SG_ 810 EPS_Charisma_Status "Rï?½ckmeldung an den Charisma-Master\n\nWert 0x3 ist nur fï?½r Fahrzeuge ab MQB relevant";
CM_ SG_ 810 EPS_Endanschlag "Die EPS muss applikativ ein Lenkhubmapping umsetzen. Das Lenkhubmapping muss fï?½r jeden NR-Reglerstatus den Defaultendanschlag oder die Lenkhubaufweitung zuordnen.";
CM_ SG_ 810 EPS_Fehlerlampe "Steuert direkt die Fehlerlampe Lenkhilfe (gelb); kein Aufprï?½fen bei Neustart, keine Rï?½ckleseinformation in Kombi-Botschaft (nur fï?½r VW526 Hybrid)";
CM_ SG_ 810 EPS_Lenkerposition "Position des Lenkers im Fahrzeug";
CM_ SG_ 810 EPS_PLA_Abbruch "Art des Fehlers ohne Eintrag, 16 Werte mï?½glich (siehe LH EPS/PLA)";
CM_ SG_ 810 EPS_PLA_Fehler "Art des Fehlers ohne Eintrag, 16 Werte mï?½glich (siehe LH EPS/PLA)";
CM_ SG_ 810 EPS_PLA_Status "Zustand der Statusmaschine der EPS fï?½r die korrespondierenden Statusmaschine im PLA.";
CM_ SG_ 810 EPS_SpannungsAnf "Forderung des EPS-SG's zur Spannungsanhebung.";
CM_ SG_ 810 EPS_VZ_Zst_Offset_Geradeaus "Vorzeichen des Offset Geradeauslauf gem. Schnittstellenbeschreibung Lenkhilfe";
CM_ SG_ 810 EPS_Warnungen "Diese Bits werden verwendet, um im Kombi Texte, Lampen oder Bilder fï?½r die Lenkhilfe darzustellen\nAudi MLB/RSe:\nText_1: Lenkung defekt (Prio 1)\nText_2: Lenkung Systemstï?½rung (Prio 2)\nVW526:\nText_1 (ID_TXT_1026.1): Ausfall Lenkunterstï?½tzung\nText_2 (I";
CM_ SG_ 810 EPS_Zst_Offset_Geradeaus "Lenkungsinterner Offset Geradeauslauf Nutzung gemaess Schnittstellendokumentation Lenkhilfe";
CM_ SG_ 981 BCM1_Abblendlicht_Anf "Anforderung Abblendlicht\n";
CM_ SG_ 981 BCM1_Adaptive_Lichtvert_Anf "Funktion 'Adaptive Lichtverteilung' im AFS-SG  Ein- und Ausschalten";
CM_ SG_ 981 BCM1_Allwetterlicht_Anf "Anforderung eines Allwetterlichts (ï?½ber AFS-SG realisiert): Licht fï?½r schlechte Sichtverhï?½ltnisse";
CM_ SG_ 981 BCM1_Autobahnlicht_Anf "Anforderung Autobahnlicht\n";
CM_ SG_ 981 BCM1_CH_aktiv "Coming Home (zusï?½tzlich zum Signal 'BCM1_CH_LH_aktiv' in der Botschaft BCM1_01)";
CM_ SG_ 981 BCM1_CH_LH_aktiv "Status Comming / Leaving Home\n";
CM_ SG_ 981 BCM1_Fahrlicht_Hinweis "Signal zum Kombi um den Hinweis 'Bitte Fahrlicht einschalten' anzufordern";
CM_ SG_ 981 BCM1_Fernlicht_Anf "Anforderung Fernlicht\n";
CM_ SG_ 981 BCM1_Gleitende_Leuchtw_Anf "Funktion 'Gleitende Leuchtweite' im AFS-SG  freischalten";
CM_ SG_ 981 BCM1_GLW_Fernlicht_Anf "Harte Fernlichtanforderung von BCM1 an die Funktion 'gleitende Leuchtweite' im AFS-SG";
CM_ SG_ 981 BCM1_Hinweis_Lichtnachlauf "Signal dient der Anzeige eines aktiven Lichtnachlaufes beim automatischen Abschalten der Klemme S und Klemme 15. Der Lichtnachlauf wird gestartet, wenn die Klemme 15 bei aktivem Fahrlicht deaktiviert wird.";
CM_ SG_ 981 BCM1_Kurvenlicht_links_Anf "Ansteuerung linkes Kurvenlicht/Abbiegelicht duch BCM1";
CM_ SG_ 981 BCM1_Kurvenlicht_rechts_Anf "Ansteuerung rechtes Kurvenlicht/Abbiegelicht duch BCM1";
CM_ SG_ 981 BCM1_LH_aktiv "Leaving Home (zusï?½tzlich zum Signal 'BCM1_CH_LH_aktiv' in der Botschaft BCM1_01)";
CM_ SG_ 981 BCM1_Lichtwarn_Texte "Anforderung von Lichtwarnungen vom BCM1 zum Kombi\nMLB: nur Werte 0..2";
CM_ SG_ 981 BCM1_Nebellicht_Anf "Anforderung Nebellicht\n";
CM_ SG_ 981 BCM1_Nebelschluss_Ahg_Anf "Anforderung: Nebelschlusslicht Anhï?½nger (Sollzustand)\n";
CM_ SG_ 981 BCM1_Nebelschluss_Fzg_Anf "Anforderung: Nebelschlusslicht Fahrzeug (Sollzustand)";
CM_ SG_ 981 BCM1_Parklicht_li_Anf "Anforderung: Parklicht links (Sollzustand)\n";
CM_ SG_ 981 BCM1_Parklicht_re_Anf "Anforderung: Parklicht rechts (Sollzustand)\n";
CM_ SG_ 981 BCM1_Regenlicht_Anf "Anforderung: Regenlicht (Sollzustand)\n";
CM_ SG_ 981 BCM1_Schlusslicht_Anf "Anforderung: Schlusslicht Fahrzeug (Sollzustand)\n";
CM_ SG_ 981 BCM1_Signaturlicht_Anf "Signal zur Anforderung des Signaturlichts";
CM_ SG_ 981 BCM1_Standlicht_Anf "Anforderung: Schlusslicht (Sollzustand)";
CM_ SG_ 981 BCM1_Tagfahrlicht_Anf "Anforderung: Tagfahrlicht (Sollzustand)";
CM_ SG_ 981 BCM1_Touristen_Licht_Anf "Anforderung: Touristenlicht (Sollzustand)";
CM_ SG_ 981 BCM1_Umfeldleuchten_Anf "Anforderung fï?½r Umfeldleuchten";
CM_ SG_ 981 BCM_Rueckfahrlicht_Anf "Anforderung Rï?½ckfahrlicht (Sollzustand). \nDas Signal wird entprellt (typisch 400ms) und bei KL15EIN gesendet. Das Signal ist unabhï?½ngig von der Position des Heckdeckels (kein ï?½berhitzungsschutz).";
CM_ SG_ 981 Licht_Anf_01_BZ "4bit Botschaftszaehler, wird mit jeder Sendebotschaft inkrementiert";
CM_ SG_ 981 Licht_Anf_01_CRC "Fï?½r MLB:\n'Berechnung siehe Lastenheft 'Kommunikationsabsicherung fï?½r FlexRay und CAN''\n\nAb MQB und MLBevo:\n'Berechnung siehe Lastenheft 'End-to-End Kommunikationsabsicherung''\n\nEndwerte siehe Begleitdokument 'S-PDU Kennungsfolgen'";
CM_ SG_ 981 TFL_Matrix_Variante01_Anf "Gibt die einzustellende Variante der Tagfahrlicht-Matrix an.";
CM_ SG_ 981 TFL_Matrix_Variante02_Anf "Gibt die einzustellende Variante der Tagfahrlicht-Matrix an.";
CM_ SG_ 981 TFL_Matrix_Variante03_Anf "Gibt die einzustellende Variante der Tagfahrlicht-Matrix an.";
CM_ SG_ 981 TFL_Matrix_Variante04_Anf "Gibt die einzustellende Variante der Tagfahrlicht-Matrix an.";
CM_ SG_ 982 BRL_als_SHL "Zeigt an ob das Bremslicht als Schlusslicht implementiert wird (Variante NAR)";
CM_ SG_ 982 LH_3_Bremsl_def "Fehlerstatus 3. Bremsleuchte\n";
CM_ SG_ 982 LH_Aussenlicht_def "Aussenlicht kann nicht mehr korrekt angesteuert werden (EEPROM Codierung kann nicht mehr ausgelesen werden)\n";
CM_ SG_ 982 LH_Blinker_HL_akt "Blinker hinten links\n";
CM_ SG_ 982 LH_Blinker_HR_akt "Blinker hinten rechts\n";
CM_ SG_ 982 LH_Blinker_li_def "Fehlerstatus Blinker hinten links\n";
CM_ SG_ 982 LH_Blinker_re_def "Fehlerstatus Blinker hinten rechts\n";
CM_ SG_ 982 LH_Brems_Blk_li_def "Konfiguration BRL + BLK links \n";
CM_ SG_ 982 LH_Brems_Blk_re_def "Konfiguration BRL + BLK rechts\n";
CM_ SG_ 982 LH_Bremsl_li_def "Fehlerstatus Bremslicht hinten links (Detektion Einzelausfall)\n";
CM_ SG_ 982 LH_Bremsl_li_ges_def "Fehlerstatus Bremslicht hinten links (Detektion Totalausfall)\n";
CM_ SG_ 982 LH_Bremsl_mi_def "Fehlerstatus Bremslicht mitte oder Gepï?½ckraumklappe  (Detektion Einzelausfall)";
CM_ SG_ 982 LH_Bremsl_re_def "Fehlerstatus Bremslicht hinten rechts  (Detektion Einzelausfall)\n";
CM_ SG_ 982 LH_Bremsl_re_ges_def "Fehlerstatus Bremslicht hinten rechts (Detektion Totalausfall)";
CM_ SG_ 982 LH_Bremslicht_H_aktiv "Bremslicht hinten\n";
CM_ SG_ 982 LH_Diag_LED_li_def "Heckleuchte links defekt";
CM_ SG_ 982 LH_Diag_LED_re_def "Heckleuchte rechts defekt";
CM_ SG_ 982 LH_Diag_Status_li_def "Auï?½enlicht Diagnose \nSystemstï?½rung links";
CM_ SG_ 982 LH_Diag_Status_re_def "Auï?½enlicht Diagnose Systemstï?½rung rechts ";
CM_ SG_ 982 LH_Kennzl_def "Fehlerstatus Kennzeichenbeleuchtung hinten\n";
CM_ SG_ 982 LH_Nebel_li_def "Fehlererkennung Nebelschlusslicht hinten links\n";
CM_ SG_ 982 LH_Nebel_mi_def "Fehlererkennung Nebelschlusslicht hinten Mitte\n\n\n";
CM_ SG_ 982 LH_Nebel_re_def "Fehlererkennung Nebelschlusslicht hinten rechts\n";
CM_ SG_ 982 LH_Nebelschluss_aktiv "Nebelschlusslicht\n";
CM_ SG_ 982 LH_Parklicht_HL_aktiv "Parklicht hinten links \n";
CM_ SG_ 982 LH_Parklicht_HR_aktiv "Parklicht hinten rechts \n";
CM_ SG_ 982 LH_Rueckf_li_def "Fehlererkennung Rï?½ckfahrlicht hinten links\n";
CM_ SG_ 982 LH_Rueckf_mi_def "Fehlererkennung Rï?½ckfahrlicht Mitte\n";
CM_ SG_ 982 LH_Rueckf_re_def "Fehlererkennung Rï?½ckfahrlicht hinten rechts\n";
CM_ SG_ 982 LH_Rueckfahrlicht_aktiv "Rueckfahrlicht";
CM_ SG_ 982 LH_Schluss_Brems_li_def "Konfiguration SL+ BRL + PL links und SL+ BRL  links\n";
CM_ SG_ 982 LH_Schluss_Brems_mi_def "Fehlerstatus Schluss + Bremslicht mitte defekt (Detektion Einzelausfall)";
CM_ SG_ 982 LH_Schluss_Brems_Nebel_li_def "Signal wird gesetzt, wenn eine Unterbrechung oder  ein Kurzschluss am Lampenausgang fï?½r Schluss_Brems_Nebelschlusslicht erkannt wird.";
CM_ SG_ 982 LH_Schluss_Brems_Nebel_re_def "Signal wird gesetzt, wenn eine Unterbrechung oder  ein Kurzschluss am Lampenausgang fï?½r Schluss_Brems_Nebelschlusslicht erkannt wird.";
CM_ SG_ 982 LH_Schluss_Brems_re_def "Konfiguration SL+ BRL + PL rechts und SL+ BRL  rechts\n";
CM_ SG_ 982 LH_Schluss_Nebel_li_def "Konfiguration SL + NSL links oder SL + NSL + PL links\n";
CM_ SG_ 982 LH_Schluss_Nebel_re_def "Konfiguration SL + NSL rechts oder SL + NSL + PL rechts\n";
CM_ SG_ 982 LH_Schlusslicht_li_def "Fehlererkennung Schlusslicht hinten links\n";
CM_ SG_ 982 LH_Schlusslicht_mi_def "Fehlererkennung Schlusslicht hinten Mitte";
CM_ SG_ 982 LH_Schlusslicht_re_def "Fehlererkennung Schlusslicht hinten rechts\n";
CM_ SG_ 982 LH_SL_BRL_BLK_li_def "Konfiguration SL + BRL + BLK links oder SL + BRL + BLK + PL links\n";
CM_ SG_ 982 LH_SL_BRL_BLK_re_def "Konfiguration SL + BRL + BLK rechts oder SL + BRL + BLK + PL rechts\n";
CM_ SG_ 982 LH_Standlicht_H_aktiv "Standlicht hinten\n";
CM_ SG_ 982 LH_Zusatzschlussl_def "mindestens ein Zusatzschlusslicht in der Heckbeleuchtung defekt.";
CM_ SG_ 982 Licht_hinten_01_BZ "ï?½berlaufender 4bit Botschaftszaehler; wird in jeder Sendebotschaft inkrementiert";
CM_ SG_ 1624 BCM1_Licht_Dunkelheit_aktiv "Licht aktiv aufgrund von Dunkelheit (nicht bei Autobahn-, Tagfahr- oder Regenlicht)";
CM_ SG_ 1624 LV_Abbiegelicht_li_def "Fehlerstatus Abbiegelicht vorne links\n";
CM_ SG_ 1624 LV_Abbiegelicht_re_def "Fehlerstatus Abbiegelicht vorne rechts\n";
CM_ SG_ 1624 LV_Abblend_Fernlicht_li_def "Fehlerstatus Abblendlicht und Fernlicht links ";
CM_ SG_ 1624 LV_Abblend_Fernlicht_re_def "Fehlerstatus Abblendlicht und Fernlicht rechts";
CM_ SG_ 1624 LV_Abblendlicht_Anzeige "Abblendlicht aktiv";
CM_ SG_ 1624 LV_Abblendlicht_li_def "Fehlerstatus Abblendlicht vorne links \n";
CM_ SG_ 1624 LV_Abblendlicht_re_def "Fehlerstatus Abblendlicht vorne rechts\n";
CM_ SG_ 1624 LV_Abblendlicht_TFL_li_def "Fehlerstatus Abblendlicht und Tagfahrlicht links\n";
CM_ SG_ 1624 LV_Abblendlicht_TFL_re_def "Fehlerstatus Abblendlicht und Tagfahrlicht rechts ";
CM_ SG_ 1624 LV_AFL_aktiv_Anzeige "Anzeige AFL-Funktion";
CM_ SG_ 1624 LV_AFL_defekt "Fehlerstatus AFL\n";
CM_ SG_ 1624 LV_Aussenlicht_def "Aussenlicht kann nicht mehr korrekt angesteuert werden (EEPROM Codierung kann nicht mehr ausgelesen werden)\n";
CM_ SG_ 1624 LV_Blinker_li_def "Fehlerstatus Blinker vorne links\n";
CM_ SG_ 1624 LV_Blinker_re_def "Fehlerstatus Blinker vorne rechts\n";
CM_ SG_ 1624 LV_Blinker_VL_aktiv "Blinker vorne links\n";
CM_ SG_ 1624 LV_Blinker_VR_aktiv "Blinker vorne links\n";
CM_ SG_ 1624 LV_Blk_li_Seite_def "Fehlerstatus Seitenblinker links\n";
CM_ SG_ 1624 LV_Blk_re_Seite_def "Fehlerstatus Blinker Seite rechts\n";
CM_ SG_ 1624 LV_Fernlicht_Anzeige "Fernlicht_aktiv";
CM_ SG_ 1624 LV_Fernlicht_li_def "Fehlerstatus Fernlicht vorne links\n";
CM_ SG_ 1624 LV_Fernlicht_re_def "Fehlerstatus Fernlicht vorne rechts\n";
CM_ SG_ 1624 LV_FLA_aktiv_Anzeige "Ansteuerung FLA-Lampe im Kombi (BCM1 Bedienmaster)";
CM_ SG_ 1624 LV_FLA_defekt "Fehlerstatus FLA (Anzeige des entsprechenden Fehlertext im Kombi)";
CM_ SG_ 1624 LV_FLA_Sensor_blockiert "Status FLA-Sensor (Anzeige des entsprechenden Fehlertext im Kombi)";
CM_ SG_ 1624 LV_LED_Scheinwerfer_li_def "Fehlerstatus LED-Scheinwerfer links\n";
CM_ SG_ 1624 LV_LED_Scheinwerfer_re_def "Fehlerstatus LED-Scheinwerfer rechts";
CM_ SG_ 1624 LV_MXB_Status_Anzeige "Aktueller Status des Fernlichts / MxB zur Signalisierung im Kombi.";
CM_ SG_ 1624 LV_Nebellicht_Anzeige "Nebellicht_aktiv\n";
CM_ SG_ 1624 LV_Nebellicht_li_def "Fehlerstatus Nebelscheinwerfer vorne links\n";
CM_ SG_ 1624 LV_Nebellicht_re_def "Fehlerstatus Nebelscheinwerfer vorne rechts\n";
CM_ SG_ 1624 LV_Nebellicht_TFL_li_def "Fehlerstatus Nebellicht und Tagfahrlicht links ";
CM_ SG_ 1624 LV_Nebellicht_TFL_re_def "Fehlerstatus Nebellicht und Tagfahrlicht rechts";
CM_ SG_ 1624 LV_Nebelschlusslicht_Anzeige "Nebelschlusslicht_aktiv\n";
CM_ SG_ 1624 LV_Standlicht_Anzeige "Anzeige Standlicht\n";
CM_ SG_ 1624 LV_Standlicht_li_def "Fehlerstatus Standlicht vorne links\n";
CM_ SG_ 1624 LV_Standlicht_re_def "Fehlerstatus Standlicht vorne rechts\n";
CM_ SG_ 1624 LV_Standlicht_TFL_li_def "Fehlerstatus Standlicht und Tagfahrlicht links ";
CM_ SG_ 1624 LV_Standlicht_TFL_re_def "Fehlerstatus Standlicht und Tagfahrlicht rechts ";
CM_ SG_ 1624 LV_Tagfahrlicht_Anzeige "Anzeige Tagfahrlicht\n";
CM_ SG_ 1624 LV_Tagfahrlicht_li_def "Fehlerstatus Tagfahrlicht links\n";
CM_ SG_ 1624 LV_Tagfahrlicht_re_def "Fehlerstatus Tagfahrlicht rechts";
CM_ SG_ 2527679675 LiSi_Defrost_Taste "Defrost AN/AUS und Status";
CM_ SG_ 2527679675 LiSi_FSH_Taste "Frontscheibenheizung AN/AUS und Status";
CM_ SG_ 2527679675 LiSi_HSH_Taste "Heckscheibenheizung AN/AUS";
CM_ SG_ 2527679675 LiSi_Touch_Event "Touch_Events fï?½r Informationen einer Funktionsauslï?½sung auf der LiSi, welches dann fï?½r bspw. ein akustiches Signal zentral umgesetzt werden kï?½nnen.";
CM_ SG_ 2527679675 LTM_01_BZ "4bit Botschaftszï?½hler";
CM_ SG_ 2527679675 LTM_01_CRC "Ab MQB und MLBevo:\n'Berechnung siehe Lastenheft 'End-to-End Kommunikationsabsicherung''\n\nEndwerte siehe Begleitdokument 'S-PDU Kennungsfolgen'";
CM_ SG_ 2527679675 LTM_Autolicht "Status Autolicht-Taste";
CM_ SG_ 2527679675 LTM_Beruehrung "Status fï?½r Berï?½hrung der Auto-Taste im Lichttastenmodul (LTM)";
CM_ SG_ 2527679675 LTM_Lokalaktiv "Lokalaktiv Statusbit";
CM_ SG_ 2527679675 LTM_Nebellicht "Status Nebellicht-Taste";
CM_ SG_ 2527679675 LTM_Nebelschlusslicht "Status Nebelschlusslicht-Taste";
CM_ SG_ 2527679675 LTM_ResponseError "siehe LIN2.0-Specification\n(Darf nicht ï?½ber ein Fehlergueltigkeitsbit abgesichtert werden!)";
CM_ SG_ 2527679675 LTM_StatusLichttastenmodul "Betriebszustand Lichttastenmodul";
CM_ SG_ 2527679675 LTM_Variante "LTM_Variante dient zur Unterscheidung, welche Variante des Lichttastenmoduls verbaut ist:\n0x00  1-Tasten-Bedienung  (LTM mit 1-Hauptlichttaste)\n0x01  3-Tasten-Bedienung  (LTM mit 3-Hauptlichttasten)\n0x02  Variante 3\n0x03  Variante 4";
CM_ SG_ 134 LWI_01_BZ "Botschaft asynchron geroutet. Zï?½hlerwert kann springen.";
CM_ SG_ 134 LWI_01_CRC "Fï?½r MLB:\n'Berechnung siehe Lastenheft 'Kommunikationsabsicherung fï?½r FlexRay und CAN''\n\nAb MQB und MLBevo:\n'Berechnung siehe Lastenheft 'End-to-End Kommunikationsabsicherung'\n\nEndwerte siehe Begleitdokument 'S-PDU Kennungsfolgen'";
CM_ SG_ 134 LWI_Lenkradw_Geschw "Wertebereich = +/- 2500 Grad/s\nAuflï?½sung = 5 Grad/s\n\nHinweis: Zusï?½tzlich gestellte Winkel bei Dynamiklenkung beachten !";
CM_ SG_ 134 LWI_Lenkradwinkel "Wertebereich = +/- 800 Grad\nAuflï?½sung = 0,1 Grad\nACHTUNG: spezifizierte Interne Auflï?½sung des Sensors betrï?½gt aber nur Schrittweite 0,5 Grad!\n\nHinweis:\nMLB: Zusï?½tzlich gestellte Winkel bei Dynamiklenkung beachten !\nMQB: Nicht konstante Lenkï?½bersetzu";
CM_ SG_ 134 LWI_QBit_Lenkradwinkel "Das QBit wird auch bei nicht abgeglichenem Lenkradwinkelsensor gesetzt";
CM_ SG_ 134 LWI_QBit_Sub_Daten "Es gilt die Signalspezifikation laut LAH";
CM_ SG_ 134 LWI_Sub_Daten "Verschlï?½sseltes Datenpaket vom Sub-Rechner des LWS, Verwendung nur durch SCU und ESP_ADS\nVerwendung gemï?½ï?½ 'Sicherheitsanforderungen an Empfï?½ngersteuergerï?½te'\n\nIm MLB gilt die Signalspezifikation: LAH 8K0953B\nIm MLBevo gilt die Signalspezifikation LAH.";
CM_ SG_ 134 LWI_VZ_Lenkradw_Geschw "Vorzeichen Lenkradwinkelgeschwindigkeit gemï?½ss DIN70000; \nNullstellung = +0";
CM_ SG_ 134 LWI_VZ_Lenkradwinkel "Vorzeichen Lenkradwinkel gemï?½ss DIN70000; \nNullstellung = +0";
BA_DEF_ BO_ "CANFD_BRS" ENUM "0", "1";
BA_DEF_ BO_ "DiagRequest" ENUM "No", "Yes";
BA_DEF_ BO_ "DiagResponse" ENUM "No", "Yes";
BA_DEF_ BO_ "DiagState" ENUM "No", "Yes";
BA_DEF_ BO_ "GenMsgChkConstant" HEX 0 4095;
BA_DEF_ BO_ "GenMsgCycleTime" INT 0 65535;
BA_DEF_ BO_ "GenMsgCycleTimeFast" INT 0 65535;
BA_DEF_ BO_ "GenMsgDelayTime" INT 0 100000;
BA_DEF_ BO_ "GenMsgILSupport" ENUM "No", "Yes";
BA_DEF_ BO_ "GenMsgNrOfRepetition" INT 0 100;
BA_DEF_ BO_ "GenMsgPDUConstants" STRING;
BA_DEF_ BO_ "GenMsgSendType" ENUM "Cyclic", "not_used", "not_used", "not_used", "not_used", "not_used", "not_used", "IfActive", "NoMsgSendType";
BA_DEF_ BO_ "GenMsgStartDelayTime" INT 0 100000;
BA_DEF_ BO_ "MsgType" ENUM "Application", "NM ", "NMH", "TP2.0", "ISO-TP ", "BAP", "EID", "KS", "XCP_PRE_CONFIGURED", "XCP_RUNTIME_CONFIGURED";
BA_DEF_ BO_ "NmMessage" ENUM "No", "Yes";
BA_DEF_ BO_ "NmhMessage" ENUM "No", "Yes";
BA_DEF_ BO_ "VAGTP20_API" HEX 0 255;
BA_DEF_ BO_ "VAGTP20_DynConnection" ENUM "No", "Yes";
BA_DEF_ BO_ "VAGTP20_DynSetup" ENUM "No", "Yes";
BA_DEF_ BO_ "VAGTP20_StatConnection" ENUM "No", "Yes";
BA_DEF_ BO_ "VFrameFormat" ENUM "StandardCAN", "ExtendedCAN", "reserved", "reserved", "reserved", "reserved", "reserved", "reserved", "reserved", "reserved", "reserved", "reserved", "reserved", "reserved", "StandardCAN_FD", "ExtendedCAN_FD";
BA_DEF_ SG_ "Fehlerwert" HEX 0 2147483647;
BA_DEF_ SG_ "GenSigActiveRepetitions" INT -2147483648 2147483647;
BA_DEF_ SG_ "GenSigFuncType" ENUM "NoFunction", "MsgCounter", "CRC-8", "XOR", "XOR-2", "DatedBit", "SW-Kl15", "CHK", "Constant", "Protocol", "CRC-8-SAE_J1850", "CRC-32", "DataLength", "DataID", "MsgCounter16", "SOK-Signatur", "Cluster";
BA_DEF_ SG_ "GenSigInactiveValue" INT -2147483648 2147483647;
BA_DEF_ SG_ "GenSigMissingSourceValue" HEX 0 2147483647;
BA_DEF_ SG_ "GenSigSendType" ENUM "Cyclic", "OnWrite", "OnWriteWithRepetition", "OnChange", "OnChangeWithRepetition", "IfActive", "IfActiveWithRepetition", "NoSigSendType", "OnChangeAndIfActive", "OnChangeAndIfActiveWithRepetition";
BA_DEF_ SG_ "GenSigStartValue" INT -2147483648 2147483647;
BA_DEF_ SG_ "GenSigSwitchedByIgnition" ENUM "No", "Yes";
BA_DEF_ SG_ "NWM-WakeupAllowed" ENUM "No", "Yes";

BA_DEF_REL_ BU_SG_REL_ "GenSigTimeoutTime" INT 0 65535;
BA_DEF_DEF_ "CANFD_BRS" "1";
BA_DEF_DEF_ "DiagRequest" "No";
BA_DEF_DEF_ "DiagResponse" "No";
BA_DEF_DEF_ "DiagState" "No";
BA_DEF_DEF_ "Fehlerwert" 0;
BA_DEF_DEF_ "GenMsgChkConstant" 0;
BA_DEF_DEF_ "GenMsgCycleTime" 0;
BA_DEF_DEF_ "GenMsgCycleTimeFast" 0;
BA_DEF_DEF_ "GenMsgDelayTime" 0;
BA_DEF_DEF_ "GenMsgILSupport" "No";
BA_DEF_DEF_ "GenMsgNrOfRepetition" 0;
BA_DEF_DEF_ "GenMsgPDUConstants" "";
BA_DEF_DEF_ "GenMsgSendType" "NoMsgSendType";
BA_DEF_DEF_ "GenMsgStartDelayTime" 0;
BA_DEF_DEF_ "GenSigActiveRepetitions" 0;
BA_DEF_DEF_ "GenSigFuncType" "NoFunction";
BA_DEF_DEF_ "GenSigInactiveValue" 0;
BA_DEF_DEF_ "GenSigMissingSourceValue" 0;
BA_DEF_DEF_ "GenSigSendType" "NoSigSendType";
BA_DEF_DEF_ "GenSigStartValue" 0;
BA_DEF_DEF_ "GenSigSwitchedByIgnition" "Yes";
BA_DEF_DEF_ "MsgType" "Application";
BA_DEF_DEF_ "NWM-WakeupAllowed" "No";
BA_DEF_DEF_ "NmMessage" "No";
BA_DEF_DEF_ "NmhMessage" "No";
BA_DEF_DEF_ "VAGTP20_API" 0;
BA_DEF_DEF_ "VAGTP20_DynConnection" "No";
BA_DEF_DEF_ "VAGTP20_DynSetup" "No";
BA_DEF_DEF_ "VAGTP20_StatConnection" "No";
BA_DEF_DEF_ "VFrameFormat" "StandardCAN";
BA_DEF_DEF_REL_ "GenSigTimeoutTime" 0;
BA_ "GenMsgCycleTime" BO_ 1646 2000;
BA_ "GenMsgDelayTime" BO_ 1646 200;
BA_ "GenMsgILSupport" BO_ 1646 1;
BA_ "GenMsgSendType" BO_ 1646 0;
BA_ "VFrameFormat" BO_ 1646 14;
BA_ "GenMsgCycleTime" BO_ 1649 2000;
BA_ "GenMsgDelayTime" BO_ 1649 200;
BA_ "GenMsgILSupport" BO_ 1649 1;
BA_ "GenMsgSendType" BO_ 1649 0;
BA_ "VFrameFormat" BO_ 1649 14;
BA_ "GenMsgCycleTime" BO_ 1640 200;
BA_ "GenMsgCycleTimeFast" BO_ 1640 100;
BA_ "GenMsgDelayTime" BO_ 1640 50;
BA_ "GenMsgILSupport" BO_ 1640 1;
BA_ "GenMsgNrOfRepetition" BO_ 1640 5;
BA_ "GenMsgSendType" BO_ 1640 0;
BA_ "VFrameFormat" BO_ 1640 14;
BA_ "GenMsgCycleTime" BO_ 2527679635 2000;
BA_ "GenMsgDelayTime" BO_ 2527679635 200;
BA_ "GenMsgILSupport" BO_ 2527679635 1;
BA_ "GenMsgSendType" BO_ 2527679635 0;
BA_ "VFrameFormat" BO_ 2527679635 15;
BA_ "GenMsgCycleTime" BO_ 1505 200;
BA_ "GenMsgILSupport" BO_ 1505 1;
BA_ "GenMsgSendType" BO_ 1505 0;
BA_ "VFrameFormat" BO_ 1505 14;
BA_ "GenMsgCycleTime" BO_ 2549088521 500;
BA_ "GenMsgILSupport" BO_ 2549088521 1;
BA_ "GenMsgSendType" BO_ 2549088521 0;
BA_ "VFrameFormat" BO_ 2549088521 15;
BA_ "GenMsgCycleTime" BO_ 2549088272 500;
BA_ "GenMsgILSupport" BO_ 2549088272 1;
BA_ "GenMsgSendType" BO_ 2549088272 0;
BA_ "VFrameFormat" BO_ 2549088272 15;
BA_ "GenMsgCycleTime" BO_ 2549088283 500;
BA_ "GenMsgILSupport" BO_ 2549088283 1;
BA_ "GenMsgSendType" BO_ 2549088283 0;
BA_ "VFrameFormat" BO_ 2549088283 15;
BA_ "GenMsgCycleTime" BO_ 2549088371 500;
BA_ "GenMsgILSupport" BO_ 2549088371 1;
BA_ "GenMsgSendType" BO_ 2549088371 0;
BA_ "VFrameFormat" BO_ 2549088371 15;
BA_ "GenMsgCycleTime" BO_ 2549088276 500;
BA_ "GenMsgILSupport" BO_ 2549088276 1;
BA_ "GenMsgSendType" BO_ 2549088276 0;
BA_ "VFrameFormat" BO_ 2549088276 15;
BA_ "GenMsgCycleTime" BO_ 2549088524 500;
BA_ "GenMsgILSupport" BO_ 2549088524 1;
BA_ "GenMsgSendType" BO_ 2549088524 0;
BA_ "VFrameFormat" BO_ 2549088524 15;
BA_ "GenMsgCycleTime" BO_ 779 50;
BA_ "GenMsgILSupport" BO_ 779 1;
BA_ "GenMsgSendType" BO_ 779 0;
BA_ "VFrameFormat" BO_ 779 14;
BA_ "GenMsgCycleTime" BO_ 1719 1000;
BA_ "GenMsgDelayTime" BO_ 1719 100;
BA_ "GenMsgILSupport" BO_ 1719 1;
BA_ "GenMsgSendType" BO_ 1719 0;
BA_ "VFrameFormat" BO_ 1719 14;
BA_ "GenMsgCycleTime" BO_ 1720 1000;
BA_ "GenMsgILSupport" BO_ 1720 1;
BA_ "GenMsgSendType" BO_ 1720 0;
BA_ "VFrameFormat" BO_ 1720 14;
BA_ "GenMsgCycleTime" BO_ 2527679639 1000;
BA_ "GenMsgCycleTimeFast" BO_ 2527679639 100;
BA_ "GenMsgDelayTime" BO_ 2527679639 100;
BA_ "GenMsgILSupport" BO_ 2527679639 1;
BA_ "GenMsgNrOfRepetition" BO_ 2527679639 5;
BA_ "GenMsgSendType" BO_ 2527679639 0;
BA_ "VFrameFormat" BO_ 2527679639 15;
BA_ "GenMsgCycleTime" BO_ 2589283631 500;
BA_ "GenMsgILSupport" BO_ 2589283631 1;
BA_ "GenMsgSendType" BO_ 2589283631 0;
BA_ "VFrameFormat" BO_ 2589283631 15;
BA_ "GenMsgCycleTime" BO_ 1614 1000;
BA_ "GenMsgDelayTime" BO_ 1614 20;
BA_ "GenMsgILSupport" BO_ 1614 1;
BA_ "GenMsgSendType" BO_ 1614 0;
BA_ "VFrameFormat" BO_ 1614 14;
BA_ "MsgType" BO_ 2621702408 4;
BA_ "VFrameFormat" BO_ 2621702408 15;
BA_ "MsgType" BO_ 2621833480 4;
BA_ "VFrameFormat" BO_ 2621833480 15;
BA_ "MsgType" BO_ 2621440371 4;
BA_ "VFrameFormat" BO_ 2621440371 15;
BA_ "MsgType" BO_ 2621571443 4;
BA_ "VFrameFormat" BO_ 2621571443 15;
BA_ "MsgType" BO_ 2621440276 4;
BA_ "VFrameFormat" BO_ 2621440276 15;
BA_ "MsgType" BO_ 2621571348 4;
BA_ "VFrameFormat" BO_ 2621571348 15;
BA_ "MsgType" BO_ 2549899278 4;
BA_ "VFrameFormat" BO_ 2549899278 15;
BA_ "MsgType" BO_ 2550030350 4;
BA_ "VFrameFormat" BO_ 2550030350 15;
BA_ "MsgType" BO_ 2549875053 4;
BA_ "VFrameFormat" BO_ 2549875053 15;
BA_ "MsgType" BO_ 2550006125 4;
BA_ "VFrameFormat" BO_ 2550006125 15;
BA_ "GenMsgCycleTime" BO_ 919 100;
BA_ "GenMsgDelayTime" BO_ 919 20;
BA_ "GenMsgILSupport" BO_ 919 1;
BA_ "GenMsgSendType" BO_ 919 0;
BA_ "VFrameFormat" BO_ 919 14;
BA_ "GenMsgChkConstant" BO_ 810 41;
BA_ "GenMsgCycleTime" BO_ 810 50;
BA_ "GenMsgILSupport" BO_ 810 1;
BA_ "GenMsgPDUConstants" BO_ 810 "0x29,0x29,0x29,0x29,0x29,0x29,0x29,0x29,0x29,0x29,0x29,0x29,0x29,0x29,0x29,0x29";
BA_ "GenMsgSendType" BO_ 810 0;
BA_ "VFrameFormat" BO_ 810 14;
BA_ "GenMsgCycleTime" BO_ 981 100;
BA_ "GenMsgDelayTime" BO_ 981 50;
BA_ "GenMsgILSupport" BO_ 981 1;
BA_ "GenMsgPDUConstants" BO_ 981 "0xc5,0x39,0xc7,0xf9,0x92,0xd8,0x24,0xce,0xf1,0xb5,0x7a,0xc4,0xbc,0x60,0xe3,0xd1";
BA_ "GenMsgSendType" BO_ 981 0;
BA_ "VFrameFormat" BO_ 981 14;
BA_ "GenMsgCycleTime" BO_ 982 100;
BA_ "GenMsgDelayTime" BO_ 982 20;
BA_ "GenMsgILSupport" BO_ 982 1;
BA_ "GenMsgSendType" BO_ 982 0;
BA_ "VFrameFormat" BO_ 982 14;
BA_ "GenMsgCycleTime" BO_ 1624 1000;
BA_ "GenMsgDelayTime" BO_ 1624 50;
BA_ "GenMsgILSupport" BO_ 1624 1;
BA_ "GenMsgSendType" BO_ 1624 0;
BA_ "VFrameFormat" BO_ 1624 14;
BA_ "GenMsgCycleTime" BO_ 2527679675 40;
BA_ "GenMsgILSupport" BO_ 2527679675 1;
BA_ "GenMsgSendType" BO_ 2527679675 0;
BA_ "VFrameFormat" BO_ 2527679675 15;
BA_ "GenMsgChkConstant" BO_ 134 134;
BA_ "GenMsgCycleTime" BO_ 134 20;
BA_ "GenMsgILSupport" BO_ 134 1;
BA_ "GenMsgPDUConstants" BO_ 134 "0x86,0x86,0x86,0x86,0x86,0x86,0x86,0x86,0x86,0x86,0x86,0x86,0x86,0x86,0x86,0x86";
BA_ "GenMsgSendType" BO_ 134 0;
BA_ "VFrameFormat" BO_ 134 14;
BA_ "GenSigSendType" SG_ 1646 KL_Anf_AussenspiegelHzg 3;
BA_ "GenSigSwitchedByIgnition" SG_ 1646 KL_Anf_AussenspiegelHzg 0;
BA_ "GenSigSendType" SG_ 1646 KL_BCmE_Livetip_Freigabe 3;
BA_ "GenSigSwitchedByIgnition" SG_ 1646 KL_BCmE_Livetip_Freigabe 0;
BA_ "GenSigSendType" SG_ 1646 KL_ErwVK_Anf 3;
BA_ "GenSigSwitchedByIgnition" SG_ 1646 KL_ErwVK_Anf 0;
BA_ "GenSigSendType" SG_ 1646 KL_FSH_Automatikbetrieb 3;
BA_ "GenSigSwitchedByIgnition" SG_ 1646 KL_FSH_Automatikbetrieb 0;
BA_ "Fehlerwert" SG_ 1646 KL_Geblaese_Fond_Status 15;
BA_ "GenSigSendType" SG_ 1646 KL_Geblaese_Fond_Status 0;
BA_ "GenSigStartValue" SG_ 1646 KL_Geblaese_Fond_Status 14;
BA_ "GenSigSwitchedByIgnition" SG_ 1646 KL_Geblaese_Fond_Status 0;
BA_ "Fehlerwert" SG_ 1646 KL_Geblaese_Status 15;
BA_ "GenSigSendType" SG_ 1646 KL_Geblaese_Status 0;
BA_ "GenSigStartValue" SG_ 1646 KL_Geblaese_Status 14;
BA_ "GenSigSwitchedByIgnition" SG_ 1646 KL_Geblaese_Status 0;
BA_ "Fehlerwert" SG_ 1646 KL_Heizkreisventilstellung 3;
BA_ "GenSigSendType" SG_ 1646 KL_Heizkreisventilstellung 0;
BA_ "GenSigSwitchedByIgnition" SG_ 1646 KL_Heizkreisventilstellung 0;
BA_ "Fehlerwert" SG_ 1646 KL_I_Geblaese_Fond 255;
BA_ "GenSigSendType" SG_ 1646 KL_I_Geblaese_Fond 3;
BA_ "GenSigSwitchedByIgnition" SG_ 1646 KL_I_Geblaese_Fond 0;
BA_ "Fehlerwert" SG_ 1646 KL_Innen_Temp 255;
BA_ "GenSigSendType" SG_ 1646 KL_Innen_Temp 0;
BA_ "GenSigStartValue" SG_ 1646 KL_Innen_Temp 254;
BA_ "GenSigSwitchedByIgnition" SG_ 1646 KL_Innen_Temp 0;
BA_ "GenSigSendType" SG_ 1646 KL_Kompressorkupplung 3;
BA_ "GenSigSwitchedByIgnition" SG_ 1646 KL_Kompressorkupplung 0;
BA_ "GenSigSendType" SG_ 1646 KL_Magnetventil 3;
BA_ "GenSigSwitchedByIgnition" SG_ 1646 KL_Magnetventil 0;
BA_ "GenSigSendType" SG_ 1646 KL_Restwaerme_aktiv 3;
BA_ "GenSigSwitchedByIgnition" SG_ 1646 KL_Restwaerme_aktiv 0;
BA_ "GenSigSendType" SG_ 1646 KL_SH_Soll_hl 3;
BA_ "GenSigSwitchedByIgnition" SG_ 1646 KL_SH_Soll_hl 0;
BA_ "GenSigSendType" SG_ 1646 KL_SH_Soll_hr 3;
BA_ "GenSigSwitchedByIgnition" SG_ 1646 KL_SH_Soll_hr 0;
BA_ "GenSigSendType" SG_ 1646 KL_SIH_LEH_Verteilung_VL 3;
BA_ "GenSigSwitchedByIgnition" SG_ 1646 KL_SIH_LEH_Verteilung_VL 0;
BA_ "GenSigSendType" SG_ 1646 KL_SIH_LEH_Verteilung_VR 3;
BA_ "GenSigSwitchedByIgnition" SG_ 1646 KL_SIH_LEH_Verteilung_VR 0;
BA_ "GenSigSendType" SG_ 1646 KL_SIH_LEL_Verteilung_VL 3;
BA_ "GenSigSwitchedByIgnition" SG_ 1646 KL_SIH_LEL_Verteilung_VL 0;
BA_ "GenSigSendType" SG_ 1646 KL_SIH_LEL_Verteilung_VR 3;
BA_ "GenSigSwitchedByIgnition" SG_ 1646 KL_SIH_LEL_Verteilung_VR 0;
BA_ "GenSigSendType" SG_ 1646 KL_Solarluefter_aktiv 3;
BA_ "GenSigSwitchedByIgnition" SG_ 1646 KL_Solarluefter_aktiv 0;
BA_ "GenSigSendType" SG_ 1646 KL_STH_aktiv 3;
BA_ "GenSigSwitchedByIgnition" SG_ 1646 KL_STH_aktiv 0;
BA_ "GenSigSendType" SG_ 1646 KL_STH_Ansteuerung 3;
BA_ "GenSigSwitchedByIgnition" SG_ 1646 KL_STH_Ansteuerung 0;
BA_ "GenSigSendType" SG_ 1646 KL_STH_Betriebsdauer 3;
BA_ "GenSigSwitchedByIgnition" SG_ 1646 KL_STH_Betriebsdauer 0;
BA_ "GenSigSendType" SG_ 1646 KL_STL_aktiv 3;
BA_ "GenSigSwitchedByIgnition" SG_ 1646 KL_STL_aktiv 0;
BA_ "GenSigSendType" SG_ 1646 KL_Umluft_Taste 3;
BA_ "GenSigSwitchedByIgnition" SG_ 1646 KL_Umluft_Taste 0;
BA_ "GenSigSendType" SG_ 1646 KL_WaPu 3;
BA_ "GenSigSwitchedByIgnition" SG_ 1646 KL_WaPu 0;
BA_ "GenSigSendType" SG_ 1649 KL_Betriebsmodus_FH 3;
BA_ "GenSigSwitchedByIgnition" SG_ 1649 KL_Betriebsmodus_FH 0;
BA_ "GenSigSendType" SG_ 1649 KL_ErwVK_Beifahrerzone 3;
BA_ "GenSigSwitchedByIgnition" SG_ 1649 KL_ErwVK_Beifahrerzone 0;
BA_ "GenSigSendType" SG_ 1649 KL_ErwVK_Fahrerzone 3;
BA_ "GenSigSwitchedByIgnition" SG_ 1649 KL_ErwVK_Fahrerzone 0;
BA_ "GenSigSendType" SG_ 1649 KL_ErwVK_Heckzone_links 3;
BA_ "GenSigSwitchedByIgnition" SG_ 1649 KL_ErwVK_Heckzone_links 0;
BA_ "GenSigSendType" SG_ 1649 Kl_ErwVK_Heckzone_rechts 3;
BA_ "GenSigSwitchedByIgnition" SG_ 1649 Kl_ErwVK_Heckzone_rechts 0;
BA_ "GenSigSendType" SG_ 1649 KL_ErwVK_Scheibenheizung 3;
BA_ "GenSigSwitchedByIgnition" SG_ 1649 KL_ErwVK_Scheibenheizung 0;
BA_ "GenSigSendType" SG_ 1649 KL_ErwVK_Status 3;
BA_ "GenSigSwitchedByIgnition" SG_ 1649 KL_ErwVK_Status 0;
BA_ "GenSigSendType" SG_ 1649 KL_Hinweis_Kuehlmodus 3;
BA_ "GenSigSwitchedByIgnition" SG_ 1649 KL_Hinweis_Kuehlmodus 0;
BA_ "GenSigSendType" SG_ 1649 KL_Meldung_Status 3;
BA_ "GenSigSwitchedByIgnition" SG_ 1649 KL_Meldung_Status 0;
BA_ "GenSigSendType" SG_ 1649 KL_STH_Betriebsdauer_lang 3;
BA_ "GenSigSwitchedByIgnition" SG_ 1649 KL_STH_Betriebsdauer_lang 0;
BA_ "GenSigSendType" SG_ 1649 KL_Stopp_Wiederstart_Anz_01 3;
BA_ "GenSigSwitchedByIgnition" SG_ 1649 KL_Stopp_Wiederstart_Anz_01 0;
BA_ "GenSigSendType" SG_ 1649 KL_Stopp_Wiederstart_Anz_02 3;
BA_ "GenSigSwitchedByIgnition" SG_ 1649 KL_Stopp_Wiederstart_Anz_02 0;
BA_ "GenSigSendType" SG_ 1649 KL_Stopp_Wiederstart_Anz_03 3;
BA_ "GenSigSwitchedByIgnition" SG_ 1649 KL_Stopp_Wiederstart_Anz_03 0;
BA_ "GenSigSendType" SG_ 1649 KL_Stopp_Wiederstart_Anz_04 3;
BA_ "GenSigSwitchedByIgnition" SG_ 1649 KL_Stopp_Wiederstart_Anz_04 0;
BA_ "GenSigSendType" SG_ 1649 KL_Stopp_Wiederstart_Anz_05 3;
BA_ "GenSigSwitchedByIgnition" SG_ 1649 KL_Stopp_Wiederstart_Anz_05 0;
BA_ "GenSigSendType" SG_ 1649 KL_Stopp_Wiederstart_Anz_06 3;
BA_ "GenSigSwitchedByIgnition" SG_ 1649 KL_Stopp_Wiederstart_Anz_06 0;
BA_ "GenSigSendType" SG_ 1649 KL_Stopp_Wiederstart_Anz_07 3;
BA_ "GenSigSwitchedByIgnition" SG_ 1649 KL_Stopp_Wiederstart_Anz_07 0;
BA_ "GenSigSendType" SG_ 1649 KL_Stopp_Wiederstart_Anz_08 3;
BA_ "GenSigSwitchedByIgnition" SG_ 1649 KL_Stopp_Wiederstart_Anz_08 0;
BA_ "GenSigSendType" SG_ 1649 KL_Stopp_Wiederstart_Anz_09 3;
BA_ "GenSigSwitchedByIgnition" SG_ 1649 KL_Stopp_Wiederstart_Anz_09 0;
BA_ "GenSigSendType" SG_ 1649 KL_Stopp_Wiederstart_Anz_Std1 3;
BA_ "GenSigSwitchedByIgnition" SG_ 1649 KL_Stopp_Wiederstart_Anz_Std1 0;
BA_ "GenSigSendType" SG_ 1649 KL_Stopp_Wiederstart_Anz_Std2 3;
BA_ "GenSigSwitchedByIgnition" SG_ 1649 KL_Stopp_Wiederstart_Anz_Std2 0;
BA_ "GenSigSendType" SG_ 1649 KL_ZZ_Betriebsmodus 3;
BA_ "GenSigSwitchedByIgnition" SG_ 1649 KL_ZZ_Betriebsmodus 0;
BA_ "GenSigSendType" SG_ 1649 KL_ZZ_Minute 3;
BA_ "GenSigSwitchedByIgnition" SG_ 1649 KL_ZZ_Minute 0;
BA_ "GenSigSendType" SG_ 1649 KL_ZZ_Monat 3;
BA_ "GenSigSwitchedByIgnition" SG_ 1649 KL_ZZ_Monat 0;
BA_ "GenSigSendType" SG_ 1649 KL_ZZ_Status_Timer 3;
BA_ "GenSigSwitchedByIgnition" SG_ 1649 KL_ZZ_Status_Timer 0;
BA_ "GenSigSendType" SG_ 1649 KL_ZZ_Stunde 3;
BA_ "GenSigSwitchedByIgnition" SG_ 1649 KL_ZZ_Stunde 0;
BA_ "GenSigSendType" SG_ 1649 KL_ZZ_Tag 3;
BA_ "GenSigSwitchedByIgnition" SG_ 1649 KL_ZZ_Tag 0;
BA_ "GenSigActiveRepetitions" SG_ 1640 FSH_Taster 5;
BA_ "GenSigSendType" SG_ 1640 FSH_Taster 4;
BA_ "GenSigSwitchedByIgnition" SG_ 1640 FSH_Taster 0;
BA_ "GenSigActiveRepetitions" SG_ 1640 HSH_Taster 5;
BA_ "GenSigSendType" SG_ 1640 HSH_Taster 4;
BA_ "GenSigSwitchedByIgnition" SG_ 1640 HSH_Taster 0;
BA_ "GenSigSendType" SG_ 1640 KL_Beschlagsgefahr 3;
BA_ "GenSigSwitchedByIgnition" SG_ 1640 KL_Beschlagsgefahr 0;
BA_ "Fehlerwert" SG_ 1640 KL_Geblspng_Fond_Soll 255;
BA_ "GenSigSendType" SG_ 1640 KL_Geblspng_Fond_Soll 0;
BA_ "GenSigSwitchedByIgnition" SG_ 1640 KL_Geblspng_Fond_Soll 0;
BA_ "Fehlerwert" SG_ 1640 KL_Geblspng_Soll 255;
BA_ "GenSigSendType" SG_ 1640 KL_Geblspng_Soll 0;
BA_ "GenSigSwitchedByIgnition" SG_ 1640 KL_Geblspng_Soll 0;
BA_ "Fehlerwert" SG_ 1640 KL_I_Geblaese 255;
BA_ "GenSigSendType" SG_ 1640 KL_I_Geblaese 0;
BA_ "GenSigSwitchedByIgnition" SG_ 1640 KL_I_Geblaese 0;
BA_ "Fehlerwert" SG_ 1640 KL_Kompressorstrom_soll 1023;
BA_ "GenSigSendType" SG_ 1640 KL_Kompressorstrom_soll 0;
BA_ "GenSigStartValue" SG_ 1640 KL_Kompressorstrom_soll 1022;
BA_ "GenSigSwitchedByIgnition" SG_ 1640 KL_Kompressorstrom_soll 0;
BA_ "GenSigSendType" SG_ 1640 KL_LRH_Stufe 3;
BA_ "GenSigStartValue" SG_ 1640 KL_LRH_Stufe 1;
BA_ "GenSigSwitchedByIgnition" SG_ 1640 KL_LRH_Stufe 0;
BA_ "GenSigActiveRepetitions" SG_ 1640 KL_LRH_Taster 5;
BA_ "GenSigSendType" SG_ 1640 KL_LRH_Taster 4;
BA_ "GenSigSwitchedByIgnition" SG_ 1640 KL_LRH_Taster 0;
BA_ "GenSigSendType" SG_ 1640 KL_PTC_Verbauinfo 0;
BA_ "GenSigSwitchedByIgnition" SG_ 1640 KL_PTC_Verbauinfo 0;
BA_ "GenSigSendType" SG_ 1640 KL_SIH_Soll_li 3;
BA_ "GenSigSwitchedByIgnition" SG_ 1640 KL_SIH_Soll_li 0;
BA_ "GenSigSendType" SG_ 1640 KL_SIH_Soll_re 3;
BA_ "GenSigSwitchedByIgnition" SG_ 1640 KL_SIH_Soll_re 0;
BA_ "GenSigSendType" SG_ 1640 KL_SIL_Soll_li 3;
BA_ "GenSigSwitchedByIgnition" SG_ 1640 KL_SIL_Soll_li 0;
BA_ "GenSigSendType" SG_ 1640 KL_SIL_Soll_re 3;
BA_ "GenSigSwitchedByIgnition" SG_ 1640 KL_SIL_Soll_re 0;
BA_ "Fehlerwert" SG_ 1640 KL_Umluftklappe_Status 15;
BA_ "GenSigSendType" SG_ 1640 KL_Umluftklappe_Status 0;
BA_ "GenSigStartValue" SG_ 1640 KL_Umluftklappe_Status 14;
BA_ "GenSigSwitchedByIgnition" SG_ 1640 KL_Umluftklappe_Status 0;
BA_ "GenSigSendType" SG_ 1640 KL_Zuheizer_Freigabe 3;
BA_ "GenSigSwitchedByIgnition" SG_ 1640 KL_Zuheizer_Freigabe 0;
BA_ "GenSigSendType" SG_ 1640 KRH_Soll_li 3;
BA_ "GenSigSwitchedByIgnition" SG_ 1640 KRH_Soll_li 0;
BA_ "GenSigSendType" SG_ 1640 KRH_Soll_re 3;
BA_ "GenSigSwitchedByIgnition" SG_ 1640 KRH_Soll_re 0;
BA_ "Fehlerwert" SG_ 2527679635 FSH_Status 3;
BA_ "GenSigSendType" SG_ 2527679635 FSH_Status 0;
BA_ "GenSigSwitchedByIgnition" SG_ 2527679635 FSH_Status 0;
BA_ "GenSigSendType" SG_ 2527679635 HSH_Relais_Anf 3;
BA_ "GenSigSwitchedByIgnition" SG_ 2527679635 HSH_Relais_Anf 0;
BA_ "GenSigSendType" SG_ 2527679635 KL_AL_HL_Anf 3;
BA_ "GenSigSwitchedByIgnition" SG_ 2527679635 KL_AL_HL_Anf 0;
BA_ "GenSigSendType" SG_ 2527679635 KL_AL_HR_Anf 3;
BA_ "GenSigSwitchedByIgnition" SG_ 2527679635 KL_AL_HR_Anf 0;
BA_ "GenSigSendType" SG_ 2527679635 KL_AL_VL_Anf 3;
BA_ "GenSigSwitchedByIgnition" SG_ 2527679635 KL_AL_VL_Anf 0;
BA_ "GenSigSendType" SG_ 2527679635 KL_AL_VR_Anf 3;
BA_ "GenSigSwitchedByIgnition" SG_ 2527679635 KL_AL_VR_Anf 0;
BA_ "GenSigSendType" SG_ 2527679635 KL_Defrost_LED 3;
BA_ "GenSigSwitchedByIgnition" SG_ 2527679635 KL_Defrost_LED 0;
BA_ "GenSigSendType" SG_ 2527679635 KL_FSH_LED 3;
BA_ "GenSigSwitchedByIgnition" SG_ 2527679635 KL_FSH_LED 0;
BA_ "GenSigSendType" SG_ 2527679635 KL_FSH_Soll 3;
BA_ "GenSigSwitchedByIgnition" SG_ 2527679635 KL_FSH_Soll 0;
BA_ "Fehlerwert" SG_ 2527679635 KL_Heizstufe_LSH 15;
BA_ "GenSigSendType" SG_ 2527679635 KL_Heizstufe_LSH 3;
BA_ "GenSigSwitchedByIgnition" SG_ 2527679635 KL_Heizstufe_LSH 0;
BA_ "GenSigSendType" SG_ 2527679635 KL_HSH_LED 3;
BA_ "GenSigSwitchedByIgnition" SG_ 2527679635 KL_HSH_LED 0;
BA_ "GenSigSendType" SG_ 2527679635 KL_HSH_Soll 3;
BA_ "GenSigSwitchedByIgnition" SG_ 2527679635 KL_HSH_Soll 0;
BA_ "GenSigSendType" SG_ 2527679635 KL_HUP_aktiv 3;
BA_ "GenSigSwitchedByIgnition" SG_ 2527679635 KL_HUP_aktiv 0;
BA_ "GenSigSendType" SG_ 2527679635 KL_Klappe_Status 3;
BA_ "GenSigSwitchedByIgnition" SG_ 2527679635 KL_Klappe_Status 0;
BA_ "GenSigSendType" SG_ 2527679635 KL_LRH_PWM 3;
BA_ "GenSigSwitchedByIgnition" SG_ 2527679635 KL_LRH_PWM 0;
BA_ "GenSigSendType" SG_ 2527679635 KL_LRH_Soll 3;
BA_ "GenSigSwitchedByIgnition" SG_ 2527679635 KL_LRH_Soll 0;
BA_ "GenSigSendType" SG_ 2527679635 KL_LSH_Ansteuerung 3;
BA_ "GenSigSwitchedByIgnition" SG_ 2527679635 KL_LSH_Ansteuerung 0;
BA_ "GenSigSendType" SG_ 2527679635 KL_LSH_Betriebsdauer 3;
BA_ "GenSigSwitchedByIgnition" SG_ 2527679635 KL_LSH_Betriebsdauer 0;
BA_ "GenSigSendType" SG_ 2527679635 KL_LSH_DBetr_Bestaet 3;
BA_ "GenSigSwitchedByIgnition" SG_ 2527679635 KL_LSH_DBetr_Bestaet 0;
BA_ "GenSigSendType" SG_ 2527679635 KL_LSH_DBetr_Ein 3;
BA_ "GenSigSwitchedByIgnition" SG_ 2527679635 KL_LSH_DBetr_Ein 0;
BA_ "Fehlerwert" SG_ 2527679635 KL_Temp_ZH_Soll 255;
BA_ "GenSigSendType" SG_ 2527679635 KL_Temp_ZH_Soll 3;
BA_ "GenSigSwitchedByIgnition" SG_ 2527679635 KL_Temp_ZH_Soll 0;
BA_ "GenSigSendType" SG_ 2527679635 KL_VoKo_LED 3;
BA_ "GenSigSwitchedByIgnition" SG_ 2527679635 KL_VoKo_LED 0;
BA_ "Fehlerwert" SG_ 2527679635 KL_Voko_Status 15;
BA_ "GenSigSendType" SG_ 2527679635 KL_Voko_Status 3;
BA_ "GenSigStartValue" SG_ 2527679635 KL_Voko_Status 14;
BA_ "GenSigSwitchedByIgnition" SG_ 2527679635 KL_Voko_Status 0;
BA_ "GenSigSendType" SG_ 2527679635 KL_ZR_Anforderung 3;
BA_ "GenSigSwitchedByIgnition" SG_ 2527679635 KL_ZR_Anforderung 0;
BA_ "GenSigSendType" SG_ 2527679635 SIH_Stufe_LED_li 3;
BA_ "GenSigSwitchedByIgnition" SG_ 2527679635 SIH_Stufe_LED_li 0;
BA_ "GenSigSendType" SG_ 2527679635 SIH_Stufe_LED_re 3;
BA_ "GenSigSwitchedByIgnition" SG_ 2527679635 SIH_Stufe_LED_re 0;
BA_ "Fehlerwert" SG_ 1505 BCM1_Aussen_Temp_ungef 255;
BA_ "GenSigSendType" SG_ 1505 BCM1_Aussen_Temp_ungef 0;
BA_ "GenSigStartValue" SG_ 1505 BCM1_Aussen_Temp_ungef 254;
BA_ "GenSigSwitchedByIgnition" SG_ 1505 BCM1_Aussen_Temp_ungef 0;
BA_ "GenSigSendType" SG_ 1505 BCM1_FStatus_Aussentemp_ungef 0;
BA_ "GenSigStartValue" SG_ 1505 BCM1_FStatus_Aussentemp_ungef 1;
BA_ "GenSigSwitchedByIgnition" SG_ 1505 BCM1_FStatus_Aussentemp_ungef 0;
BA_ "Fehlerwert" SG_ 1505 BCM1_Kompressorstrom_ist 255;
BA_ "GenSigSendType" SG_ 1505 BCM1_Kompressorstrom_ist 0;
BA_ "GenSigStartValue" SG_ 1505 BCM1_Kompressorstrom_ist 254;
BA_ "GenSigSwitchedByIgnition" SG_ 1505 BCM1_Kompressorstrom_ist 0;
BA_ "GenSigSendType" SG_ 1505 BCM1_OBD_FStatus_ATemp 0;
BA_ "GenSigSwitchedByIgnition" SG_ 1505 BCM1_OBD_FStatus_ATemp 0;
BA_ "Fehlerwert" SG_ 1505 BCM1_PTC_stufig_Status 7;
BA_ "GenSigSendType" SG_ 1505 BCM1_PTC_stufig_Status 0;
BA_ "GenSigStartValue" SG_ 1505 BCM1_PTC_stufig_Status 6;
BA_ "GenSigSwitchedByIgnition" SG_ 1505 BCM1_PTC_stufig_Status 0;
BA_ "Fehlerwert" SG_ 1505 BCM_Heizungsabsperrventil_Status 3;
BA_ "GenSigSendType" SG_ 1505 BCM_Heizungsabsperrventil_Status 0;
BA_ "GenSigStartValue" SG_ 1505 BCM_Heizungsabsperrventil_Status 2;
BA_ "GenSigSwitchedByIgnition" SG_ 1505 BCM_Heizungsabsperrventil_Status 0;
BA_ "Fehlerwert" SG_ 1505 BCM_Heizungspumpe_Status 3;
BA_ "GenSigSendType" SG_ 1505 BCM_Heizungspumpe_Status 0;
BA_ "GenSigStartValue" SG_ 1505 BCM_Heizungspumpe_Status 2;
BA_ "GenSigSwitchedByIgnition" SG_ 1505 BCM_Heizungspumpe_Status 0;
BA_ "Fehlerwert" SG_ 1505 BCM_Kompressorkupplung_Status 3;
BA_ "GenSigSendType" SG_ 1505 BCM_Kompressorkupplung_Status 0;
BA_ "GenSigStartValue" SG_ 1505 BCM_Kompressorkupplung_Status 2;
BA_ "GenSigSwitchedByIgnition" SG_ 1505 BCM_Kompressorkupplung_Status 0;
BA_ "GenSigSendType" SG_ 2549088521 DispKBI_FS_Abschaltstufe 0;
BA_ "GenSigSwitchedByIgnition" SG_ 2549088521 DispKBI_FS_Abschaltstufe 0;
BA_ "GenSigSendType" SG_ 2549088521 DispKBI_FS_KD_Fehler 0;
BA_ "GenSigSwitchedByIgnition" SG_ 2549088521 DispKBI_FS_KD_Fehler 0;
BA_ "GenSigSendType" SG_ 2549088521 DispKBI_FS_KompSchutz 0;
BA_ "GenSigSwitchedByIgnition" SG_ 2549088521 DispKBI_FS_KompSchutz 0;
BA_ "GenSigSendType" SG_ 2549088521 DispKBI_FS_Nachlauftyp 0;
BA_ "GenSigStartValue" SG_ 2549088521 DispKBI_FS_Nachlauftyp 2;
BA_ "GenSigSwitchedByIgnition" SG_ 2549088521 DispKBI_FS_Nachlauftyp 0;
BA_ "GenSigSendType" SG_ 2549088521 DispKBI_FS_Transport_Mode 0;
BA_ "GenSigSwitchedByIgnition" SG_ 2549088521 DispKBI_FS_Transport_Mode 0;
BA_ "GenSigSendType" SG_ 2549088521 KN_DispKBI_FS_BusKnockOut 0;
BA_ "GenSigSwitchedByIgnition" SG_ 2549088521 KN_DispKBI_FS_BusKnockOut 0;
BA_ "GenSigSendType" SG_ 2549088521 KN_DispKBI_FS_BusKnockOutTimer 0;
BA_ "GenSigSwitchedByIgnition" SG_ 2549088521 KN_DispKBI_FS_BusKnockOutTimer 0;
BA_ "GenSigSendType" SG_ 2549088521 KN_DispKBI_FS_DiagPfad 0;
BA_ "GenSigSwitchedByIgnition" SG_ 2549088521 KN_DispKBI_FS_DiagPfad 0;
BA_ "GenSigSendType" SG_ 2549088521 KN_DispKBI_FS_ECUKnockOut 0;
BA_ "GenSigSwitchedByIgnition" SG_ 2549088521 KN_DispKBI_FS_ECUKnockOut 0;
BA_ "GenSigSendType" SG_ 2549088521 KN_DispKBI_FS_ECUKnockOutTimer 0;
BA_ "GenSigSwitchedByIgnition" SG_ 2549088521 KN_DispKBI_FS_ECUKnockOutTimer 0;
BA_ "GenSigSendType" SG_ 2549088521 NM_DispKBI_FS_Wakeup 0;
BA_ "GenSigSwitchedByIgnition" SG_ 2549088521 NM_DispKBI_FS_Wakeup 0;
BA_ "GenSigSendType" SG_ 2549088272 Gateway_Abschaltstufe 0;
BA_ "GenSigSwitchedByIgnition" SG_ 2549088272 Gateway_Abschaltstufe 0;
BA_ "GenSigSendType" SG_ 2549088272 Gateway_KompSchutz 0;
BA_ "GenSigSwitchedByIgnition" SG_ 2549088272 Gateway_KompSchutz 0;
BA_ "GenSigSendType" SG_ 2549088272 Gateway_Nachlauftyp 0;
BA_ "GenSigStartValue" SG_ 2549088272 Gateway_Nachlauftyp 2;
BA_ "GenSigSwitchedByIgnition" SG_ 2549088272 Gateway_Nachlauftyp 0;
BA_ "GenSigSendType" SG_ 2549088272 Gateway_Transport_Mode 0;
BA_ "GenSigSwitchedByIgnition" SG_ 2549088272 Gateway_Transport_Mode 0;
BA_ "GenSigSendType" SG_ 2549088272 GW_KD_Fehler 0;
BA_ "GenSigSendType" SG_ 2549088272 KN_GW_DiagPfad 0;
BA_ "GenSigSwitchedByIgnition" SG_ 2549088272 KN_GW_DiagPfad 0;
BA_ "GenSigSendType" SG_ 2549088272 NM_Gateway_Wakeup 0;
BA_ "GenSigSwitchedByIgnition" SG_ 2549088272 NM_Gateway_Wakeup 0;
BA_ "NWM-WakeupAllowed" SG_ 2549088272 NM_Gateway_Wakeup 1;
BA_ "GenSigSendType" SG_ 2549088283 HUD_Abschaltstufe 0;
BA_ "GenSigSendType" SG_ 2549088283 HUD_KD_Fehler 0;
BA_ "GenSigSwitchedByIgnition" SG_ 2549088283 HUD_KD_Fehler 0;
BA_ "GenSigSendType" SG_ 2549088283 HUD_KompSchutz 0;
BA_ "GenSigSwitchedByIgnition" SG_ 2549088283 HUD_KompSchutz 0;
BA_ "GenSigSendType" SG_ 2549088283 HUD_Nachlauftyp 0;
BA_ "GenSigStartValue" SG_ 2549088283 HUD_Nachlauftyp 2;
BA_ "GenSigSwitchedByIgnition" SG_ 2549088283 HUD_Nachlauftyp 0;
BA_ "GenSigSendType" SG_ 2549088283 HUD_Transport_Mode 0;
BA_ "GenSigSwitchedByIgnition" SG_ 2549088283 HUD_Transport_Mode 0;
BA_ "GenSigSendType" SG_ 2549088283 KN_HUD_BusKnockOut 0;
BA_ "GenSigSwitchedByIgnition" SG_ 2549088283 KN_HUD_BusKnockOut 0;
BA_ "GenSigSendType" SG_ 2549088283 KN_HUD_BusKnockOutTimer 0;
BA_ "GenSigSwitchedByIgnition" SG_ 2549088283 KN_HUD_BusKnockOutTimer 0;
BA_ "GenSigSendType" SG_ 2549088283 KN_HUD_DiagPfad 0;
BA_ "GenSigSwitchedByIgnition" SG_ 2549088283 KN_HUD_DiagPfad 0;
BA_ "GenSigSendType" SG_ 2549088283 KN_HUD_ECUKnockOut 0;
BA_ "GenSigSwitchedByIgnition" SG_ 2549088283 KN_HUD_ECUKnockOut 0;
BA_ "GenSigSendType" SG_ 2549088283 KN_HUD_ECUKnockOutTimer 0;
BA_ "GenSigSwitchedByIgnition" SG_ 2549088283 KN_HUD_ECUKnockOutTimer 0;
BA_ "GenSigSendType" SG_ 2549088283 NM_HUD_Wakeup 0;
BA_ "GenSigSwitchedByIgnition" SG_ 2549088283 NM_HUD_Wakeup 0;
BA_ "NWM-WakeupAllowed" SG_ 2549088283 NM_HUD_Wakeup 1;
BA_ "GenSigSendType" SG_ 2549088371 Info_El_Abschaltstufe 0;
BA_ "GenSigSwitchedByIgnition" SG_ 2549088371 Info_El_Abschaltstufe 0;
BA_ "GenSigSendType" SG_ 2549088371 Info_El_KD_Fehler 0;
BA_ "GenSigSwitchedByIgnition" SG_ 2549088371 Info_El_KD_Fehler 0;
BA_ "GenSigSendType" SG_ 2549088371 Info_El_KompSchutz 0;
BA_ "GenSigSwitchedByIgnition" SG_ 2549088371 Info_El_KompSchutz 0;
BA_ "GenSigSendType" SG_ 2549088371 Info_El_Nachlauftyp 0;
BA_ "GenSigStartValue" SG_ 2549088371 Info_El_Nachlauftyp 2;
BA_ "GenSigSwitchedByIgnition" SG_ 2549088371 Info_El_Nachlauftyp 0;
BA_ "GenSigSendType" SG_ 2549088371 Info_El_Transport_Mode 0;
BA_ "GenSigSwitchedByIgnition" SG_ 2549088371 Info_El_Transport_Mode 0;
BA_ "GenSigSendType" SG_ 2549088371 KN_Info_El_BusKnockOutTimer 0;
BA_ "GenSigStartValue" SG_ 2549088371 KN_Info_El_BusKnockOutTimer 255;
BA_ "GenSigSwitchedByIgnition" SG_ 2549088371 KN_Info_El_BusKnockOutTimer 0;
BA_ "GenSigSendType" SG_ 2549088371 KN_Info_El_DiagPfad 0;
BA_ "GenSigSwitchedByIgnition" SG_ 2549088371 KN_Info_El_DiagPfad 0;
BA_ "GenSigSendType" SG_ 2549088371 NM_Info_El_Wakeup 0;
BA_ "GenSigSwitchedByIgnition" SG_ 2549088371 NM_Info_El_Wakeup 0;
BA_ "NWM-WakeupAllowed" SG_ 2549088371 NM_Info_El_Wakeup 1;
BA_ "GenSigSendType" SG_ 2549088276 KBI_KD_Fehler 0;
BA_ "GenSigSwitchedByIgnition" SG_ 2549088276 KBI_KD_Fehler 0;
BA_ "GenSigSendType" SG_ 2549088276 KN_KBI_DiagPfad 0;
BA_ "GenSigSwitchedByIgnition" SG_ 2549088276 KN_KBI_DiagPfad 0;
BA_ "GenSigSendType" SG_ 2549088276 KN_Kombi_BusKnockOut 0;
BA_ "GenSigSwitchedByIgnition" SG_ 2549088276 KN_Kombi_BusKnockOut 0;
BA_ "GenSigSendType" SG_ 2549088276 KN_Kombi_BusKnockOutTimer 0;
BA_ "GenSigSwitchedByIgnition" SG_ 2549088276 KN_Kombi_BusKnockOutTimer 0;
BA_ "GenSigSendType" SG_ 2549088276 KN_Kombi_ECUKnockOut 0;
BA_ "GenSigSwitchedByIgnition" SG_ 2549088276 KN_Kombi_ECUKnockOut 0;
BA_ "GenSigSendType" SG_ 2549088276 KN_Kombi_ECUKnockOutTimer 0;
BA_ "GenSigSwitchedByIgnition" SG_ 2549088276 KN_Kombi_ECUKnockOutTimer 0;
BA_ "GenSigSendType" SG_ 2549088276 Kombi_Abschaltstufe 0;
BA_ "GenSigSwitchedByIgnition" SG_ 2549088276 Kombi_Abschaltstufe 0;
BA_ "GenSigSendType" SG_ 2549088276 Kombi_KompSchutz 0;
BA_ "GenSigSwitchedByIgnition" SG_ 2549088276 Kombi_KompSchutz 0;
BA_ "GenSigSendType" SG_ 2549088276 Kombi_Nachlauftyp 0;
BA_ "GenSigStartValue" SG_ 2549088276 Kombi_Nachlauftyp 2;
BA_ "GenSigSwitchedByIgnition" SG_ 2549088276 Kombi_Nachlauftyp 0;
BA_ "GenSigSendType" SG_ 2549088276 Kombi_Transport_Mode 0;
BA_ "GenSigSwitchedByIgnition" SG_ 2549088276 Kombi_Transport_Mode 0;
BA_ "GenSigSendType" SG_ 2549088276 NM_Kombi_Lokalaktiv 0;
BA_ "GenSigSwitchedByIgnition" SG_ 2549088276 NM_Kombi_Lokalaktiv 0;
BA_ "GenSigSendType" SG_ 2549088276 NM_Kombi_Subsystemaktiv 0;
BA_ "GenSigSwitchedByIgnition" SG_ 2549088276 NM_Kombi_Subsystemaktiv 0;
BA_ "GenSigSendType" SG_ 2549088276 NM_Kombi_Wakeup 0;
BA_ "GenSigSwitchedByIgnition" SG_ 2549088276 NM_Kombi_Wakeup 0;
BA_ "NWM-WakeupAllowed" SG_ 2549088276 NM_Kombi_Wakeup 1;
BA_ "GenSigSendType" SG_ 2549088524 KN_SmLi_01_DiagPfad 0;
BA_ "GenSigSwitchedByIgnition" SG_ 2549088524 KN_SmLi_01_DiagPfad 0;
BA_ "GenSigSendType" SG_ 2549088524 KN_SmLi_BusKnockOut 0;
BA_ "GenSigSwitchedByIgnition" SG_ 2549088524 KN_SmLi_BusKnockOut 0;
BA_ "GenSigSendType" SG_ 2549088524 KN_SmLi_BusKnockOutTimer 0;
BA_ "GenSigSwitchedByIgnition" SG_ 2549088524 KN_SmLi_BusKnockOutTimer 0;
BA_ "GenSigSendType" SG_ 2549088524 KN_SmLi_ECUKnockOut 0;
BA_ "GenSigSwitchedByIgnition" SG_ 2549088524 KN_SmLi_ECUKnockOut 0;
BA_ "GenSigSendType" SG_ 2549088524 KN_SmLi_ECUKnockOutTimer 0;
BA_ "GenSigSwitchedByIgnition" SG_ 2549088524 KN_SmLi_ECUKnockOutTimer 0;
BA_ "GenSigSendType" SG_ 2549088524 NM_SmLi_01_Wakeup 0;
BA_ "GenSigSwitchedByIgnition" SG_ 2549088524 NM_SmLi_01_Wakeup 0;
BA_ "GenSigSendType" SG_ 2549088524 SmLi_01_Abschaltstufe 0;
BA_ "GenSigSwitchedByIgnition" SG_ 2549088524 SmLi_01_Abschaltstufe 0;
BA_ "GenSigSendType" SG_ 2549088524 SmLi_01_KD_Fehler 0;
BA_ "GenSigSwitchedByIgnition" SG_ 2549088524 SmLi_01_KD_Fehler 0;
BA_ "GenSigSendType" SG_ 2549088524 SmLi_01_KompSchutz 0;
BA_ "GenSigSwitchedByIgnition" SG_ 2549088524 SmLi_01_KompSchutz 0;
BA_ "GenSigSendType" SG_ 2549088524 SmLi_01_Nachlauftyp 0;
BA_ "GenSigStartValue" SG_ 2549088524 SmLi_01_Nachlauftyp 2;
BA_ "GenSigSwitchedByIgnition" SG_ 2549088524 SmLi_01_Nachlauftyp 0;
BA_ "GenSigSendType" SG_ 2549088524 SmLi_01_Transport_Mode 0;
BA_ "GenSigSwitchedByIgnition" SG_ 2549088524 SmLi_01_Transport_Mode 0;
BA_ "GenSigSendType" SG_ 779 KBI_Anzeigefehler_LDW 0;
BA_ "GenSigSwitchedByIgnition" SG_ 779 KBI_Anzeigefehler_LDW 0;
BA_ "GenSigSendType" SG_ 779 KBI_Anzeigefehler_SWA 0;
BA_ "GenSigSwitchedByIgnition" SG_ 779 KBI_Anzeigefehler_SWA 0;
BA_ "GenSigSendType" SG_ 779 KBI_ARA_in_Anzeige 0;
BA_ "GenSigSwitchedByIgnition" SG_ 779 KBI_ARA_in_Anzeige 0;
BA_ "GenSigSendType" SG_ 779 KBI_Einheit_Tacho 0;
BA_ "GenSigSwitchedByIgnition" SG_ 779 KBI_Einheit_Tacho 0;
BA_ "GenSigSendType" SG_ 779 KBI_Handbremse 0;
BA_ "GenSigSwitchedByIgnition" SG_ 779 KBI_Handbremse 0;
BA_ "GenSigSendType" SG_ 779 KBI_MFA_v_Einheit_01 0;
BA_ "GenSigSwitchedByIgnition" SG_ 779 KBI_MFA_v_Einheit_01 0;
BA_ "GenSigSendType" SG_ 779 KBI_PLA_in_Anzeige 0;
BA_ "GenSigSwitchedByIgnition" SG_ 779 KBI_PLA_in_Anzeige 0;
BA_ "GenSigSendType" SG_ 779 KBI_Systemstatus 0;
BA_ "GenSigSwitchedByIgnition" SG_ 779 KBI_Systemstatus 0;
BA_ "GenSigSendType" SG_ 779 KBI_Tankwarnung 0;
BA_ "GenSigSwitchedByIgnition" SG_ 779 KBI_Tankwarnung 0;
BA_ "GenSigSendType" SG_ 779 KBI_Tankwarnung_ungueltig 0;
BA_ "GenSigStartValue" SG_ 779 KBI_Tankwarnung_ungueltig 1;
BA_ "GenSigSwitchedByIgnition" SG_ 779 KBI_Tankwarnung_ungueltig 0;
BA_ "GenSigSendType" SG_ 779 KBI_Taster_Fahrwerk 0;
BA_ "GenSigSwitchedByIgnition" SG_ 779 KBI_Taster_Fahrwerk 0;
BA_ "GenSigSendType" SG_ 779 KBI_Taster_Lift 0;
BA_ "GenSigSwitchedByIgnition" SG_ 779 KBI_Taster_Lift 0;
BA_ "GenSigSendType" SG_ 779 KBI_V_Digital 0;
BA_ "GenSigSwitchedByIgnition" SG_ 779 KBI_V_Digital 0;
BA_ "GenSigSendType" SG_ 779 KBI_Vorglueh_System_Lampe 0;
BA_ "GenSigSwitchedByIgnition" SG_ 779 KBI_Vorglueh_System_Lampe 0;
BA_ "GenSigSendType" SG_ 1719 KBI_FoD_PopUP_Quittiert 3;
BA_ "GenSigSendType" SG_ 1719 KBI_FStatus_Tank 0;
BA_ "GenSigSwitchedByIgnition" SG_ 1719 KBI_FStatus_Tank 0;
BA_ "GenSigSendType" SG_ 1720 KBI_GAP_Warn_Zeit_abgelaufen 0;
BA_ "GenSigSwitchedByIgnition" SG_ 1720 KBI_GAP_Warn_Zeit_abgelaufen 0;
BA_ "Fehlerwert" SG_ 1720 KBI_Max_Tankinhalt 255;
BA_ "GenSigSendType" SG_ 1720 KBI_Max_Tankinhalt 0;
BA_ "GenSigStartValue" SG_ 1720 KBI_Max_Tankinhalt 254;
BA_ "GenSigSwitchedByIgnition" SG_ 1720 KBI_Max_Tankinhalt 0;
BA_ "GenSigSendType" SG_ 1720 KBI_Nachtanken_erkannt 0;
BA_ "GenSigSwitchedByIgnition" SG_ 1720 KBI_Nachtanken_erkannt 0;
BA_ "Fehlerwert" SG_ 1720 KBI_Tankfuellstand_Prozent 127;
BA_ "GenSigSendType" SG_ 1720 KBI_Tankfuellstand_Prozent 0;
BA_ "GenSigStartValue" SG_ 1720 KBI_Tankfuellstand_Prozent 126;
BA_ "GenSigSwitchedByIgnition" SG_ 1720 KBI_Tankfuellstand_Prozent 0;
BA_ "Fehlerwert" SG_ 1720 KBI_Tankinhalt_hochaufl 16383;
BA_ "GenSigSendType" SG_ 1720 KBI_Tankinhalt_hochaufl 0;
BA_ "GenSigStartValue" SG_ 1720 KBI_Tankinhalt_hochaufl 16382;
BA_ "GenSigSwitchedByIgnition" SG_ 1720 KBI_Tankinhalt_hochaufl 0;
BA_ "GenSigSendType" SG_ 2527679639 AuthTime_Trigger_Distribution 4;
BA_ "GenSigSwitchedByIgnition" SG_ 2527679639 AuthTime_Trigger_Distribution 0;
BA_ "GenSigSendType" SG_ 2527679639 KBI_FoD_VirtualCockpitPlus_State 3;
BA_ "GenSigSwitchedByIgnition" SG_ 2527679639 KBI_FoD_VirtualCockpitPlus_State 0;
BA_ "Fehlerwert" SG_ 2527679639 KBI_Min_Tankinhalt 127;
BA_ "GenSigSendType" SG_ 2527679639 KBI_Min_Tankinhalt 0;
BA_ "GenSigStartValue" SG_ 2527679639 KBI_Min_Tankinhalt 126;
BA_ "GenSigSwitchedByIgnition" SG_ 2527679639 KBI_Min_Tankinhalt 0;
BA_ "GenSigSendType" SG_ 2527679639 KBI_Weg_Zaehler 3;
BA_ "GenSigSwitchedByIgnition" SG_ 2527679639 KBI_Weg_Zaehler 0;
BA_ "GenSigSendType" SG_ 2589283631 KBI_BC_Reset_E1 0;
BA_ "GenSigStartValue" SG_ 2589283631 KBI_BC_Reset_E1 7;
BA_ "GenSigSwitchedByIgnition" SG_ 2589283631 KBI_BC_Reset_E1 0;
BA_ "Fehlerwert" SG_ 2589283631 KBI_Tankinhalt_roh 2047;
BA_ "GenSigSendType" SG_ 2589283631 KBI_Tankinhalt_roh 0;
BA_ "GenSigStartValue" SG_ 2589283631 KBI_Tankinhalt_roh 2046;
BA_ "GenSigSwitchedByIgnition" SG_ 2589283631 KBI_Tankinhalt_roh 0;
BA_ "GenSigSendType" SG_ 1614 KBI_HUD_Data_01 3;
BA_ "GenSigSwitchedByIgnition" SG_ 1614 KBI_HUD_Data_01 0;
BA_ "GenSigSendType" SG_ 1614 KBI_HUD_Data_02 3;
BA_ "GenSigSwitchedByIgnition" SG_ 1614 KBI_HUD_Data_02 0;
BA_ "GenSigSendType" SG_ 1614 KBI_HUD_Data_03 3;
BA_ "GenSigSwitchedByIgnition" SG_ 1614 KBI_HUD_Data_03 0;
BA_ "GenSigSendType" SG_ 1614 KBI_HUD_Data_04 3;
BA_ "GenSigSwitchedByIgnition" SG_ 1614 KBI_HUD_Data_04 0;
BA_ "GenSigSendType" SG_ 1614 KBI_HUD_Data_05 3;
BA_ "GenSigSwitchedByIgnition" SG_ 1614 KBI_HUD_Data_05 0;
BA_ "GenSigSendType" SG_ 1614 KBI_HUD_Data_06 3;
BA_ "GenSigSwitchedByIgnition" SG_ 1614 KBI_HUD_Data_06 0;
BA_ "GenSigSendType" SG_ 1614 KBI_HUD_Data_07 3;
BA_ "GenSigSwitchedByIgnition" SG_ 1614 KBI_HUD_Data_07 0;
BA_ "GenSigSendType" SG_ 1614 KBI_HUD_Data_08 3;
BA_ "GenSigSwitchedByIgnition" SG_ 1614 KBI_HUD_Data_08 0;
BA_ "GenSigFuncType" SG_ 2621702408 KS_ICAS3Sys01_Req_FD_Data 9;
BA_ "GenSigSendType" SG_ 2621702408 KS_ICAS3Sys01_Req_FD_Data 3;
BA_ "GenSigSwitchedByIgnition" SG_ 2621702408 KS_ICAS3Sys01_Req_FD_Data 0;
BA_ "GenSigFuncType" SG_ 2621833480 KS_ICAS3Sys01_Resp_FD_Data 9;
BA_ "GenSigSendType" SG_ 2621833480 KS_ICAS3Sys01_Resp_FD_Data 3;
BA_ "GenSigSwitchedByIgnition" SG_ 2621833480 KS_ICAS3Sys01_Resp_FD_Data 0;
BA_ "GenSigFuncType" SG_ 2621440371 KS_Info_El_Req_FD_Data 9;
BA_ "GenSigSendType" SG_ 2621440371 KS_Info_El_Req_FD_Data 3;
BA_ "GenSigSwitchedByIgnition" SG_ 2621440371 KS_Info_El_Req_FD_Data 0;
BA_ "GenSigFuncType" SG_ 2621571443 KS_Info_El_Resp_FD_Data 9;
BA_ "GenSigSendType" SG_ 2621571443 KS_Info_El_Resp_FD_Data 3;
BA_ "GenSigSwitchedByIgnition" SG_ 2621571443 KS_Info_El_Resp_FD_Data 0;
BA_ "GenSigFuncType" SG_ 2621440276 KS_Kombi_Req_FD_Data 9;
BA_ "GenSigSendType" SG_ 2621440276 KS_Kombi_Req_FD_Data 3;
BA_ "GenSigSwitchedByIgnition" SG_ 2621440276 KS_Kombi_Req_FD_Data 0;
BA_ "GenSigFuncType" SG_ 2621571348 KS_Kombi_Resp_FD_Data 9;
BA_ "GenSigSendType" SG_ 2621571348 KS_Kombi_Resp_FD_Data 3;
BA_ "GenSigSwitchedByIgnition" SG_ 2621571348 KS_Kombi_Resp_FD_Data 0;
BA_ "GenSigFuncType" SG_ 2549899278 KS_SSN_ABT_1_Req_Data 9;
BA_ "GenSigSendType" SG_ 2549899278 KS_SSN_ABT_1_Req_Data 3;
BA_ "GenSigSwitchedByIgnition" SG_ 2549899278 KS_SSN_ABT_1_Req_Data 0;
BA_ "GenSigFuncType" SG_ 2550030350 KS_SSN_ABT_1_Resp_Data 9;
BA_ "GenSigSendType" SG_ 2550030350 KS_SSN_ABT_1_Resp_Data 3;
BA_ "GenSigSwitchedByIgnition" SG_ 2550030350 KS_SSN_ABT_1_Resp_Data 0;
BA_ "GenSigFuncType" SG_ 2549875053 KS_TV_Tuner_Req_Data 9;
BA_ "GenSigSendType" SG_ 2549875053 KS_TV_Tuner_Req_Data 3;
BA_ "GenSigSwitchedByIgnition" SG_ 2549875053 KS_TV_Tuner_Req_Data 0;
BA_ "GenSigFuncType" SG_ 2550006125 KS_TV_Tuner_Resp_Data 9;
BA_ "GenSigSendType" SG_ 2550006125 KS_TV_Tuner_Resp_Data 3;
BA_ "GenSigSwitchedByIgnition" SG_ 2550006125 KS_TV_Tuner_Resp_Data 0;
BA_ "GenSigSendType" SG_ 919 aLDW_FoD_Status 0;
BA_ "GenSigSwitchedByIgnition" SG_ 919 aLDW_FoD_Status 0;
BA_ "GenSigSendType" SG_ 919 HC_Uss_Anforderung 3;
BA_ "GenSigSwitchedByIgnition" SG_ 919 HC_Uss_Anforderung 0;
BA_ "GenSigSendType" SG_ 919 LDW_DLC 0;
BA_ "GenSigStartValue" SG_ 919 LDW_DLC 250;
BA_ "Fehlerwert" SG_ 919 LDW_Frueh_Spaet 3;
BA_ "GenSigSendType" SG_ 919 LDW_Frueh_Spaet 0;
BA_ "GenSigStartValue" SG_ 919 LDW_Frueh_Spaet 2;
BA_ "GenSigSendType" SG_ 919 LDW_Gong 0;
BA_ "GenSigSendType" SG_ 919 LDW_Lernmodus_seitenabhaengig 3;
BA_ "GenSigSendType" SG_ 919 LDW_Seite_DLCTLC 0;
BA_ "GenSigSendType" SG_ 919 LDW_Status_Anzeige 0;
BA_ "GenSigSwitchedByIgnition" SG_ 919 LDW_Status_Anzeige 0;
BA_ "GenSigSendType" SG_ 919 LDW_Status_Grid 0;
BA_ "GenSigSendType" SG_ 919 LDW_Status_LED_gelb 0;
BA_ "GenSigSendType" SG_ 919 LDW_Status_LED_gruen 0;
BA_ "GenSigSendType" SG_ 919 LDW_Texte 0;
BA_ "GenSigSendType" SG_ 919 LDW_TLC 0;
BA_ "GenSigStartValue" SG_ 919 LDW_TLC 31;
BA_ "GenSigFuncType" SG_ 810 EPS_01_BZ 1;
BA_ "GenSigSendType" SG_ 810 EPS_01_BZ 0;
BA_ "GenSigSwitchedByIgnition" SG_ 810 EPS_01_BZ 0;
BA_ "GenSigFuncType" SG_ 810 EPS_01_CRC 2;
BA_ "GenSigSendType" SG_ 810 EPS_01_CRC 0;
BA_ "GenSigSwitchedByIgnition" SG_ 810 EPS_01_CRC 0;
BA_ "GenSigSendType" SG_ 810 EPS_Akustiksignal 0;
BA_ "GenSigSwitchedByIgnition" SG_ 810 EPS_Akustiksignal 0;
BA_ "GenSigSendType" SG_ 810 EPS_Anf_KL 0;
BA_ "GenSigSwitchedByIgnition" SG_ 810 EPS_Anf_KL 0;
BA_ "GenSigSendType" SG_ 810 EPS_ARA_Status 0;
BA_ "GenSigSwitchedByIgnition" SG_ 810 EPS_ARA_Status 0;
BA_ "GenSigSendType" SG_ 810 EPS_Charisma_FahrPr 0;
BA_ "GenSigSwitchedByIgnition" SG_ 810 EPS_Charisma_FahrPr 0;
BA_ "GenSigSendType" SG_ 810 EPS_Charisma_Status 0;
BA_ "GenSigSwitchedByIgnition" SG_ 810 EPS_Charisma_Status 0;
BA_ "Fehlerwert" SG_ 810 EPS_Endanschlag 3;
BA_ "GenSigSendType" SG_ 810 EPS_Endanschlag 0;
BA_ "GenSigSendType" SG_ 810 EPS_Fehlerlampe 0;
BA_ "GenSigSwitchedByIgnition" SG_ 810 EPS_Fehlerlampe 0;
BA_ "GenSigFuncType" SG_ 810 EPS_Lenkerposition 8;
BA_ "GenSigSendType" SG_ 810 EPS_Lenkerposition 0;
BA_ "GenSigSwitchedByIgnition" SG_ 810 EPS_Lenkerposition 0;
BA_ "GenSigSendType" SG_ 810 EPS_PLA_Abbruch 0;
BA_ "GenSigSwitchedByIgnition" SG_ 810 EPS_PLA_Abbruch 0;
BA_ "GenSigSendType" SG_ 810 EPS_PLA_Fehler 0;
BA_ "GenSigSwitchedByIgnition" SG_ 810 EPS_PLA_Fehler 0;
BA_ "GenSigSendType" SG_ 810 EPS_PLA_Status 0;
BA_ "GenSigSwitchedByIgnition" SG_ 810 EPS_PLA_Status 0;
BA_ "GenSigSendType" SG_ 810 EPS_SpannungsAnf 0;
BA_ "GenSigSwitchedByIgnition" SG_ 810 EPS_SpannungsAnf 0;
BA_ "GenSigSendType" SG_ 810 EPS_VZ_Zst_Offset_Geradeaus 0;
BA_ "GenSigSwitchedByIgnition" SG_ 810 EPS_VZ_Zst_Offset_Geradeaus 0;
BA_ "GenSigSendType" SG_ 810 EPS_Warnungen 0;
BA_ "GenSigSwitchedByIgnition" SG_ 810 EPS_Warnungen 0;
BA_ "Fehlerwert" SG_ 810 EPS_Zst_Offset_Geradeaus 511;
BA_ "GenSigSendType" SG_ 810 EPS_Zst_Offset_Geradeaus 0;
BA_ "GenSigStartValue" SG_ 810 EPS_Zst_Offset_Geradeaus 510;
BA_ "GenSigSwitchedByIgnition" SG_ 810 EPS_Zst_Offset_Geradeaus 0;
BA_ "GenSigSendType" SG_ 981 BCM1_Abblendlicht_Anf 0;
BA_ "GenSigSwitchedByIgnition" SG_ 981 BCM1_Abblendlicht_Anf 0;
BA_ "GenSigSendType" SG_ 981 BCM1_Adaptive_Lichtvert_Anf 0;
BA_ "GenSigSwitchedByIgnition" SG_ 981 BCM1_Adaptive_Lichtvert_Anf 0;
BA_ "GenSigSendType" SG_ 981 BCM1_Allwetterlicht_Anf 0;
BA_ "GenSigSwitchedByIgnition" SG_ 981 BCM1_Allwetterlicht_Anf 0;
BA_ "GenSigSendType" SG_ 981 BCM1_Autobahnlicht_Anf 0;
BA_ "GenSigSwitchedByIgnition" SG_ 981 BCM1_Autobahnlicht_Anf 0;
BA_ "GenSigSendType" SG_ 981 BCM1_CH_aktiv 0;
BA_ "GenSigSwitchedByIgnition" SG_ 981 BCM1_CH_aktiv 0;
BA_ "NWM-WakeupAllowed" SG_ 981 BCM1_CH_aktiv 1;
BA_ "GenSigSendType" SG_ 981 BCM1_CH_LH_aktiv 0;
BA_ "GenSigSwitchedByIgnition" SG_ 981 BCM1_CH_LH_aktiv 0;
BA_ "GenSigSendType" SG_ 981 BCM1_Fahrlicht_Hinweis 3;
BA_ "GenSigSwitchedByIgnition" SG_ 981 BCM1_Fahrlicht_Hinweis 0;
BA_ "GenSigSendType" SG_ 981 BCM1_Fernlicht_Anf 0;
BA_ "GenSigSwitchedByIgnition" SG_ 981 BCM1_Fernlicht_Anf 0;
BA_ "GenSigSendType" SG_ 981 BCM1_Gleitende_Leuchtw_Anf 0;
BA_ "GenSigSwitchedByIgnition" SG_ 981 BCM1_Gleitende_Leuchtw_Anf 0;
BA_ "GenSigSendType" SG_ 981 BCM1_GLW_Fernlicht_Anf 3;
BA_ "GenSigSwitchedByIgnition" SG_ 981 BCM1_GLW_Fernlicht_Anf 0;
BA_ "GenSigSendType" SG_ 981 BCM1_Hinweis_Lichtnachlauf 3;
BA_ "GenSigSwitchedByIgnition" SG_ 981 BCM1_Hinweis_Lichtnachlauf 0;
BA_ "GenSigSendType" SG_ 981 BCM1_Kurvenlicht_links_Anf 0;
BA_ "GenSigSwitchedByIgnition" SG_ 981 BCM1_Kurvenlicht_links_Anf 0;
BA_ "GenSigSendType" SG_ 981 BCM1_Kurvenlicht_rechts_Anf 0;
BA_ "GenSigSwitchedByIgnition" SG_ 981 BCM1_Kurvenlicht_rechts_Anf 0;
BA_ "GenSigSendType" SG_ 981 BCM1_LH_aktiv 0;
BA_ "GenSigSwitchedByIgnition" SG_ 981 BCM1_LH_aktiv 0;
BA_ "NWM-WakeupAllowed" SG_ 981 BCM1_LH_aktiv 1;
BA_ "GenSigSendType" SG_ 981 BCM1_Lichtwarn_Texte 3;
BA_ "GenSigSwitchedByIgnition" SG_ 981 BCM1_Lichtwarn_Texte 0;
BA_ "GenSigSendType" SG_ 981 BCM1_Nebellicht_Anf 0;
BA_ "GenSigSwitchedByIgnition" SG_ 981 BCM1_Nebellicht_Anf 0;
BA_ "GenSigSendType" SG_ 981 BCM1_Nebelschluss_Ahg_Anf 0;
BA_ "GenSigSwitchedByIgnition" SG_ 981 BCM1_Nebelschluss_Ahg_Anf 0;
BA_ "GenSigSendType" SG_ 981 BCM1_Nebelschluss_Fzg_Anf 0;
BA_ "GenSigSwitchedByIgnition" SG_ 981 BCM1_Nebelschluss_Fzg_Anf 0;
BA_ "GenSigSendType" SG_ 981 BCM1_Parklicht_li_Anf 0;
BA_ "GenSigSwitchedByIgnition" SG_ 981 BCM1_Parklicht_li_Anf 0;
BA_ "GenSigSendType" SG_ 981 BCM1_Parklicht_re_Anf 0;
BA_ "GenSigSwitchedByIgnition" SG_ 981 BCM1_Parklicht_re_Anf 0;
BA_ "GenSigSendType" SG_ 981 BCM1_Regenlicht_Anf 0;
BA_ "GenSigSwitchedByIgnition" SG_ 981 BCM1_Regenlicht_Anf 0;
BA_ "GenSigSendType" SG_ 981 BCM1_Schlusslicht_Anf 0;
BA_ "GenSigSwitchedByIgnition" SG_ 981 BCM1_Schlusslicht_Anf 0;
BA_ "GenSigSendType" SG_ 981 BCM1_Signaturlicht_Anf 0;
BA_ "GenSigSwitchedByIgnition" SG_ 981 BCM1_Signaturlicht_Anf 0;
BA_ "GenSigSendType" SG_ 981 BCM1_Standlicht_Anf 0;
BA_ "GenSigSwitchedByIgnition" SG_ 981 BCM1_Standlicht_Anf 0;
BA_ "GenSigSendType" SG_ 981 BCM1_Tagfahrlicht_Anf 0;
BA_ "GenSigSwitchedByIgnition" SG_ 981 BCM1_Tagfahrlicht_Anf 0;
BA_ "GenSigSendType" SG_ 981 BCM1_Touristen_Licht_Anf 0;
BA_ "GenSigSwitchedByIgnition" SG_ 981 BCM1_Touristen_Licht_Anf 0;
BA_ "GenSigSendType" SG_ 981 BCM1_Umfeldleuchten_Anf 0;
BA_ "GenSigSwitchedByIgnition" SG_ 981 BCM1_Umfeldleuchten_Anf 0;
BA_ "GenSigSendType" SG_ 981 BCM_Rueckfahrlicht_Anf 0;
BA_ "GenSigSwitchedByIgnition" SG_ 981 BCM_Rueckfahrlicht_Anf 0;
BA_ "GenSigFuncType" SG_ 981 Licht_Anf_01_BZ 1;
BA_ "GenSigSendType" SG_ 981 Licht_Anf_01_BZ 0;
BA_ "GenSigSwitchedByIgnition" SG_ 981 Licht_Anf_01_BZ 0;
BA_ "GenSigFuncType" SG_ 981 Licht_Anf_01_CRC 2;
BA_ "GenSigSendType" SG_ 981 Licht_Anf_01_CRC 0;
BA_ "GenSigSwitchedByIgnition" SG_ 981 Licht_Anf_01_CRC 0;
BA_ "GenSigSendType" SG_ 981 TFL_Matrix_Variante01_Anf 3;
BA_ "GenSigSendType" SG_ 981 TFL_Matrix_Variante02_Anf 3;
BA_ "GenSigSendType" SG_ 981 TFL_Matrix_Variante03_Anf 3;
BA_ "GenSigSendType" SG_ 981 TFL_Matrix_Variante04_Anf 3;
BA_ "GenSigSendType" SG_ 982 BRL_als_SHL 3;
BA_ "GenSigSwitchedByIgnition" SG_ 982 BRL_als_SHL 0;
BA_ "GenSigSendType" SG_ 982 LH_3_Bremsl_def 0;
BA_ "GenSigSwitchedByIgnition" SG_ 982 LH_3_Bremsl_def 0;
BA_ "GenSigSendType" SG_ 982 LH_Aussenlicht_def 0;
BA_ "GenSigSwitchedByIgnition" SG_ 982 LH_Aussenlicht_def 0;
BA_ "GenSigSendType" SG_ 982 LH_Blinker_HL_akt 0;
BA_ "GenSigSwitchedByIgnition" SG_ 982 LH_Blinker_HL_akt 0;
BA_ "GenSigSendType" SG_ 982 LH_Blinker_HR_akt 0;
BA_ "GenSigSwitchedByIgnition" SG_ 982 LH_Blinker_HR_akt 0;
BA_ "GenSigSendType" SG_ 982 LH_Blinker_li_def 0;
BA_ "GenSigSwitchedByIgnition" SG_ 982 LH_Blinker_li_def 0;
BA_ "GenSigSendType" SG_ 982 LH_Blinker_re_def 0;
BA_ "GenSigSwitchedByIgnition" SG_ 982 LH_Blinker_re_def 0;
BA_ "GenSigSendType" SG_ 982 LH_Brems_Blk_li_def 0;
BA_ "GenSigSwitchedByIgnition" SG_ 982 LH_Brems_Blk_li_def 0;
BA_ "GenSigSendType" SG_ 982 LH_Brems_Blk_re_def 0;
BA_ "GenSigSwitchedByIgnition" SG_ 982 LH_Brems_Blk_re_def 0;
BA_ "GenSigSendType" SG_ 982 LH_Bremsl_li_def 0;
BA_ "GenSigSwitchedByIgnition" SG_ 982 LH_Bremsl_li_def 0;
BA_ "GenSigSendType" SG_ 982 LH_Bremsl_li_ges_def 0;
BA_ "GenSigSwitchedByIgnition" SG_ 982 LH_Bremsl_li_ges_def 0;
BA_ "GenSigSendType" SG_ 982 LH_Bremsl_mi_def 0;
BA_ "GenSigSwitchedByIgnition" SG_ 982 LH_Bremsl_mi_def 0;
BA_ "GenSigSendType" SG_ 982 LH_Bremsl_re_def 0;
BA_ "GenSigSwitchedByIgnition" SG_ 982 LH_Bremsl_re_def 0;
BA_ "GenSigSendType" SG_ 982 LH_Bremsl_re_ges_def 0;
BA_ "GenSigSwitchedByIgnition" SG_ 982 LH_Bremsl_re_ges_def 0;
BA_ "GenSigSendType" SG_ 982 LH_Bremslicht_H_aktiv 0;
BA_ "GenSigSwitchedByIgnition" SG_ 982 LH_Bremslicht_H_aktiv 0;
BA_ "GenSigSendType" SG_ 982 LH_Diag_LED_li_def 0;
BA_ "GenSigSwitchedByIgnition" SG_ 982 LH_Diag_LED_li_def 0;
BA_ "GenSigSendType" SG_ 982 LH_Diag_LED_re_def 0;
BA_ "GenSigSwitchedByIgnition" SG_ 982 LH_Diag_LED_re_def 0;
BA_ "GenSigSendType" SG_ 982 LH_Diag_Status_li_def 0;
BA_ "GenSigSwitchedByIgnition" SG_ 982 LH_Diag_Status_li_def 0;
BA_ "GenSigSendType" SG_ 982 LH_Diag_Status_re_def 0;
BA_ "GenSigSwitchedByIgnition" SG_ 982 LH_Diag_Status_re_def 0;
BA_ "GenSigSendType" SG_ 982 LH_Kennzl_def 0;
BA_ "GenSigSwitchedByIgnition" SG_ 982 LH_Kennzl_def 0;
BA_ "GenSigSendType" SG_ 982 LH_Nebel_li_def 0;
BA_ "GenSigSwitchedByIgnition" SG_ 982 LH_Nebel_li_def 0;
BA_ "GenSigSendType" SG_ 982 LH_Nebel_mi_def 0;
BA_ "GenSigSwitchedByIgnition" SG_ 982 LH_Nebel_mi_def 0;
BA_ "GenSigSendType" SG_ 982 LH_Nebel_re_def 0;
BA_ "GenSigSwitchedByIgnition" SG_ 982 LH_Nebel_re_def 0;
BA_ "GenSigSendType" SG_ 982 LH_Nebelschluss_aktiv 0;
BA_ "GenSigSwitchedByIgnition" SG_ 982 LH_Nebelschluss_aktiv 0;
BA_ "GenSigSendType" SG_ 982 LH_Parklicht_HL_aktiv 0;
BA_ "GenSigSwitchedByIgnition" SG_ 982 LH_Parklicht_HL_aktiv 0;
BA_ "GenSigSendType" SG_ 982 LH_Parklicht_HR_aktiv 0;
BA_ "GenSigSwitchedByIgnition" SG_ 982 LH_Parklicht_HR_aktiv 0;
BA_ "GenSigSendType" SG_ 982 LH_Rueckf_li_def 0;
BA_ "GenSigSwitchedByIgnition" SG_ 982 LH_Rueckf_li_def 0;
BA_ "GenSigSendType" SG_ 982 LH_Rueckf_mi_def 0;
BA_ "GenSigSwitchedByIgnition" SG_ 982 LH_Rueckf_mi_def 0;
BA_ "GenSigSendType" SG_ 982 LH_Rueckf_re_def 0;
BA_ "GenSigSwitchedByIgnition" SG_ 982 LH_Rueckf_re_def 0;
BA_ "GenSigSendType" SG_ 982 LH_Rueckfahrlicht_aktiv 0;
BA_ "GenSigSwitchedByIgnition" SG_ 982 LH_Rueckfahrlicht_aktiv 0;
BA_ "GenSigSendType" SG_ 982 LH_Schluss_Brems_li_def 0;
BA_ "GenSigSwitchedByIgnition" SG_ 982 LH_Schluss_Brems_li_def 0;
BA_ "GenSigSendType" SG_ 982 LH_Schluss_Brems_mi_def 0;
BA_ "GenSigSwitchedByIgnition" SG_ 982 LH_Schluss_Brems_mi_def 0;
BA_ "GenSigSendType" SG_ 982 LH_Schluss_Brems_Nebel_li_def 0;
BA_ "GenSigSwitchedByIgnition" SG_ 982 LH_Schluss_Brems_Nebel_li_def 0;
BA_ "GenSigSendType" SG_ 982 LH_Schluss_Brems_Nebel_re_def 0;
BA_ "GenSigSwitchedByIgnition" SG_ 982 LH_Schluss_Brems_Nebel_re_def 0;
BA_ "GenSigSendType" SG_ 982 LH_Schluss_Brems_re_def 0;
BA_ "GenSigSwitchedByIgnition" SG_ 982 LH_Schluss_Brems_re_def 0;
BA_ "GenSigSendType" SG_ 982 LH_Schluss_Nebel_li_def 0;
BA_ "GenSigSwitchedByIgnition" SG_ 982 LH_Schluss_Nebel_li_def 0;
BA_ "GenSigSendType" SG_ 982 LH_Schluss_Nebel_re_def 0;
BA_ "GenSigSwitchedByIgnition" SG_ 982 LH_Schluss_Nebel_re_def 0;
BA_ "GenSigSendType" SG_ 982 LH_Schlusslicht_li_def 0;
BA_ "GenSigSwitchedByIgnition" SG_ 982 LH_Schlusslicht_li_def 0;
BA_ "GenSigSendType" SG_ 982 LH_Schlusslicht_mi_def 0;
BA_ "GenSigSwitchedByIgnition" SG_ 982 LH_Schlusslicht_mi_def 0;
BA_ "GenSigSendType" SG_ 982 LH_Schlusslicht_re_def 0;
BA_ "GenSigSwitchedByIgnition" SG_ 982 LH_Schlusslicht_re_def 0;
BA_ "GenSigSendType" SG_ 982 LH_SL_BRL_BLK_li_def 0;
BA_ "GenSigSwitchedByIgnition" SG_ 982 LH_SL_BRL_BLK_li_def 0;
BA_ "GenSigSendType" SG_ 982 LH_SL_BRL_BLK_re_def 0;
BA_ "GenSigSwitchedByIgnition" SG_ 982 LH_SL_BRL_BLK_re_def 0;
BA_ "GenSigSendType" SG_ 982 LH_Standlicht_H_aktiv 0;
BA_ "GenSigSwitchedByIgnition" SG_ 982 LH_Standlicht_H_aktiv 0;
BA_ "GenSigSendType" SG_ 982 LH_Zusatzschlussl_def 0;
BA_ "GenSigSwitchedByIgnition" SG_ 982 LH_Zusatzschlussl_def 0;
BA_ "GenSigFuncType" SG_ 982 Licht_hinten_01_BZ 1;
BA_ "GenSigSendType" SG_ 982 Licht_hinten_01_BZ 0;
BA_ "GenSigSwitchedByIgnition" SG_ 982 Licht_hinten_01_BZ 0;
BA_ "GenSigSendType" SG_ 1624 BCM1_Licht_Dunkelheit_aktiv 3;
BA_ "GenSigSwitchedByIgnition" SG_ 1624 BCM1_Licht_Dunkelheit_aktiv 0;
BA_ "GenSigSendType" SG_ 1624 LV_Abbiegelicht_li_def 0;
BA_ "GenSigSwitchedByIgnition" SG_ 1624 LV_Abbiegelicht_li_def 0;
BA_ "GenSigSendType" SG_ 1624 LV_Abbiegelicht_re_def 0;
BA_ "GenSigSwitchedByIgnition" SG_ 1624 LV_Abbiegelicht_re_def 0;
BA_ "GenSigSendType" SG_ 1624 LV_Abblend_Fernlicht_li_def 0;
BA_ "GenSigSwitchedByIgnition" SG_ 1624 LV_Abblend_Fernlicht_li_def 0;
BA_ "GenSigSendType" SG_ 1624 LV_Abblend_Fernlicht_re_def 0;
BA_ "GenSigSwitchedByIgnition" SG_ 1624 LV_Abblend_Fernlicht_re_def 0;
BA_ "GenSigSendType" SG_ 1624 LV_Abblendlicht_Anzeige 3;
BA_ "GenSigSwitchedByIgnition" SG_ 1624 LV_Abblendlicht_Anzeige 0;
BA_ "GenSigSendType" SG_ 1624 LV_Abblendlicht_li_def 0;
BA_ "GenSigSwitchedByIgnition" SG_ 1624 LV_Abblendlicht_li_def 0;
BA_ "GenSigSendType" SG_ 1624 LV_Abblendlicht_re_def 0;
BA_ "GenSigSwitchedByIgnition" SG_ 1624 LV_Abblendlicht_re_def 0;
BA_ "GenSigSendType" SG_ 1624 LV_Abblendlicht_TFL_li_def 0;
BA_ "GenSigSwitchedByIgnition" SG_ 1624 LV_Abblendlicht_TFL_li_def 0;
BA_ "GenSigSendType" SG_ 1624 LV_Abblendlicht_TFL_re_def 0;
BA_ "GenSigSwitchedByIgnition" SG_ 1624 LV_Abblendlicht_TFL_re_def 0;
BA_ "GenSigSendType" SG_ 1624 LV_AFL_aktiv_Anzeige 3;
BA_ "GenSigSwitchedByIgnition" SG_ 1624 LV_AFL_aktiv_Anzeige 0;
BA_ "GenSigSendType" SG_ 1624 LV_AFL_defekt 3;
BA_ "GenSigSwitchedByIgnition" SG_ 1624 LV_AFL_defekt 0;
BA_ "GenSigSendType" SG_ 1624 LV_Aussenlicht_def 3;
BA_ "GenSigSwitchedByIgnition" SG_ 1624 LV_Aussenlicht_def 0;
BA_ "GenSigSendType" SG_ 1624 LV_Blinker_li_def 0;
BA_ "GenSigSwitchedByIgnition" SG_ 1624 LV_Blinker_li_def 0;
BA_ "GenSigSendType" SG_ 1624 LV_Blinker_re_def 0;
BA_ "GenSigSwitchedByIgnition" SG_ 1624 LV_Blinker_re_def 0;
BA_ "GenSigSendType" SG_ 1624 LV_Blinker_VL_aktiv 3;
BA_ "GenSigSwitchedByIgnition" SG_ 1624 LV_Blinker_VL_aktiv 0;
BA_ "GenSigSendType" SG_ 1624 LV_Blinker_VR_aktiv 3;
BA_ "GenSigSwitchedByIgnition" SG_ 1624 LV_Blinker_VR_aktiv 0;
BA_ "GenSigSendType" SG_ 1624 LV_Blk_li_Seite_def 0;
BA_ "GenSigSwitchedByIgnition" SG_ 1624 LV_Blk_li_Seite_def 0;
BA_ "GenSigSendType" SG_ 1624 LV_Blk_re_Seite_def 0;
BA_ "GenSigSwitchedByIgnition" SG_ 1624 LV_Blk_re_Seite_def 0;
BA_ "GenSigSendType" SG_ 1624 LV_Fernlicht_Anzeige 3;
BA_ "GenSigSwitchedByIgnition" SG_ 1624 LV_Fernlicht_Anzeige 0;
BA_ "GenSigSendType" SG_ 1624 LV_Fernlicht_li_def 0;
BA_ "GenSigSwitchedByIgnition" SG_ 1624 LV_Fernlicht_li_def 0;
BA_ "GenSigSendType" SG_ 1624 LV_Fernlicht_re_def 0;
BA_ "GenSigSwitchedByIgnition" SG_ 1624 LV_Fernlicht_re_def 0;
BA_ "GenSigSendType" SG_ 1624 LV_FLA_aktiv_Anzeige 3;
BA_ "GenSigSwitchedByIgnition" SG_ 1624 LV_FLA_aktiv_Anzeige 0;
BA_ "GenSigSendType" SG_ 1624 LV_FLA_defekt 0;
BA_ "GenSigSwitchedByIgnition" SG_ 1624 LV_FLA_defekt 0;
BA_ "GenSigSendType" SG_ 1624 LV_FLA_Sensor_blockiert 0;
BA_ "GenSigSwitchedByIgnition" SG_ 1624 LV_FLA_Sensor_blockiert 0;
BA_ "GenSigSendType" SG_ 1624 LV_LED_Scheinwerfer_li_def 0;
BA_ "GenSigSwitchedByIgnition" SG_ 1624 LV_LED_Scheinwerfer_li_def 0;
BA_ "GenSigSendType" SG_ 1624 LV_LED_Scheinwerfer_re_def 0;
BA_ "GenSigSwitchedByIgnition" SG_ 1624 LV_LED_Scheinwerfer_re_def 0;
BA_ "GenSigSendType" SG_ 1624 LV_MXB_Status_Anzeige 3;
BA_ "GenSigSwitchedByIgnition" SG_ 1624 LV_MXB_Status_Anzeige 0;
BA_ "GenSigSendType" SG_ 1624 LV_Nebellicht_Anzeige 3;
BA_ "GenSigSwitchedByIgnition" SG_ 1624 LV_Nebellicht_Anzeige 0;
BA_ "GenSigSendType" SG_ 1624 LV_Nebellicht_li_def 0;
BA_ "GenSigSwitchedByIgnition" SG_ 1624 LV_Nebellicht_li_def 0;
BA_ "GenSigSendType" SG_ 1624 LV_Nebellicht_re_def 0;
BA_ "GenSigSwitchedByIgnition" SG_ 1624 LV_Nebellicht_re_def 0;
BA_ "GenSigSendType" SG_ 1624 LV_Nebellicht_TFL_li_def 0;
BA_ "GenSigSwitchedByIgnition" SG_ 1624 LV_Nebellicht_TFL_li_def 0;
BA_ "GenSigSendType" SG_ 1624 LV_Nebellicht_TFL_re_def 0;
BA_ "GenSigSwitchedByIgnition" SG_ 1624 LV_Nebellicht_TFL_re_def 0;
BA_ "GenSigSendType" SG_ 1624 LV_Nebelschlusslicht_Anzeige 3;
BA_ "GenSigSwitchedByIgnition" SG_ 1624 LV_Nebelschlusslicht_Anzeige 0;
BA_ "GenSigSendType" SG_ 1624 LV_Standlicht_Anzeige 3;
BA_ "GenSigSwitchedByIgnition" SG_ 1624 LV_Standlicht_Anzeige 0;
BA_ "GenSigSendType" SG_ 1624 LV_Standlicht_li_def 0;
BA_ "GenSigSwitchedByIgnition" SG_ 1624 LV_Standlicht_li_def 0;
BA_ "GenSigSendType" SG_ 1624 LV_Standlicht_re_def 0;
BA_ "GenSigSwitchedByIgnition" SG_ 1624 LV_Standlicht_re_def 0;
BA_ "GenSigSendType" SG_ 1624 LV_Standlicht_TFL_li_def 0;
BA_ "GenSigSwitchedByIgnition" SG_ 1624 LV_Standlicht_TFL_li_def 0;
BA_ "GenSigSendType" SG_ 1624 LV_Standlicht_TFL_re_def 0;
BA_ "GenSigSwitchedByIgnition" SG_ 1624 LV_Standlicht_TFL_re_def 0;
BA_ "GenSigSendType" SG_ 1624 LV_Tagfahrlicht_Anzeige 3;
BA_ "GenSigSwitchedByIgnition" SG_ 1624 LV_Tagfahrlicht_Anzeige 0;
BA_ "GenSigSendType" SG_ 1624 LV_Tagfahrlicht_li_def 0;
BA_ "GenSigSwitchedByIgnition" SG_ 1624 LV_Tagfahrlicht_li_def 0;
BA_ "GenSigSendType" SG_ 1624 LV_Tagfahrlicht_re_def 0;
BA_ "GenSigSwitchedByIgnition" SG_ 1624 LV_Tagfahrlicht_re_def 0;
BA_ "Fehlerwert" SG_ 2527679675 LiSi_Defrost_Taste 2;
BA_ "GenSigSendType" SG_ 2527679675 LiSi_Defrost_Taste 0;
BA_ "GenSigStartValue" SG_ 2527679675 LiSi_Defrost_Taste 3;
BA_ "GenSigSwitchedByIgnition" SG_ 2527679675 LiSi_Defrost_Taste 0;
BA_ "Fehlerwert" SG_ 2527679675 LiSi_FSH_Taste 2;
BA_ "GenSigSendType" SG_ 2527679675 LiSi_FSH_Taste 0;
BA_ "GenSigStartValue" SG_ 2527679675 LiSi_FSH_Taste 3;
BA_ "GenSigSwitchedByIgnition" SG_ 2527679675 LiSi_FSH_Taste 0;
BA_ "Fehlerwert" SG_ 2527679675 LiSi_HSH_Taste 2;
BA_ "GenSigSendType" SG_ 2527679675 LiSi_HSH_Taste 0;
BA_ "GenSigStartValue" SG_ 2527679675 LiSi_HSH_Taste 3;
BA_ "GenSigSwitchedByIgnition" SG_ 2527679675 LiSi_HSH_Taste 0;
BA_ "Fehlerwert" SG_ 2527679675 LiSi_Touch_Event 15;
BA_ "GenSigSendType" SG_ 2527679675 LiSi_Touch_Event 0;
BA_ "GenSigSwitchedByIgnition" SG_ 2527679675 LiSi_Touch_Event 0;
BA_ "GenSigFuncType" SG_ 2527679675 LTM_01_BZ 1;
BA_ "GenSigSendType" SG_ 2527679675 LTM_01_BZ 0;
BA_ "GenSigFuncType" SG_ 2527679675 LTM_01_CRC 2;
BA_ "GenSigSendType" SG_ 2527679675 LTM_01_CRC 0;
BA_ "GenSigSwitchedByIgnition" SG_ 2527679675 LTM_01_CRC 0;
BA_ "GenSigSendType" SG_ 2527679675 LTM_Autolicht 0;
BA_ "GenSigSwitchedByIgnition" SG_ 2527679675 LTM_Autolicht 0;
BA_ "GenSigSendType" SG_ 2527679675 LTM_Beruehrung 0;
BA_ "GenSigSwitchedByIgnition" SG_ 2527679675 LTM_Beruehrung 0;
BA_ "GenSigSendType" SG_ 2527679675 LTM_Lokalaktiv 0;
BA_ "GenSigSwitchedByIgnition" SG_ 2527679675 LTM_Lokalaktiv 0;
BA_ "GenSigSendType" SG_ 2527679675 LTM_Nebellicht 0;
BA_ "GenSigSwitchedByIgnition" SG_ 2527679675 LTM_Nebellicht 0;
BA_ "GenSigSendType" SG_ 2527679675 LTM_Nebelschlusslicht 0;
BA_ "GenSigSwitchedByIgnition" SG_ 2527679675 LTM_Nebelschlusslicht 0;
BA_ "Fehlerwert" SG_ 2527679675 LTM_ResponseError 1;
BA_ "GenSigSendType" SG_ 2527679675 LTM_ResponseError 0;
BA_ "GenSigSwitchedByIgnition" SG_ 2527679675 LTM_ResponseError 0;
BA_ "GenSigSendType" SG_ 2527679675 LTM_StatusLichttastenmodul 0;
BA_ "GenSigStartValue" SG_ 2527679675 LTM_StatusLichttastenmodul 2;
BA_ "GenSigSwitchedByIgnition" SG_ 2527679675 LTM_StatusLichttastenmodul 0;
BA_ "GenSigSendType" SG_ 2527679675 LTM_Variante 0;
BA_ "GenSigSwitchedByIgnition" SG_ 2527679675 LTM_Variante 0;
BA_ "GenSigFuncType" SG_ 134 LWI_01_BZ 1;
BA_ "GenSigSendType" SG_ 134 LWI_01_BZ 0;
BA_ "GenSigFuncType" SG_ 134 LWI_01_CRC 2;
BA_ "GenSigSendType" SG_ 134 LWI_01_CRC 0;
BA_ "GenSigSwitchedByIgnition" SG_ 134 LWI_01_CRC 0;
BA_ "Fehlerwert" SG_ 134 LWI_Lenkradw_Geschw 511;
BA_ "GenSigSendType" SG_ 134 LWI_Lenkradw_Geschw 0;
BA_ "GenSigStartValue" SG_ 134 LWI_Lenkradw_Geschw 510;
BA_ "Fehlerwert" SG_ 134 LWI_Lenkradwinkel 8191;
BA_ "GenSigSendType" SG_ 134 LWI_Lenkradwinkel 0;
BA_ "GenSigStartValue" SG_ 134 LWI_Lenkradwinkel 8190;
BA_ "GenSigSendType" SG_ 134 LWI_QBit_Lenkradwinkel 0;
BA_ "GenSigStartValue" SG_ 134 LWI_QBit_Lenkradwinkel 1;
BA_ "GenSigSendType" SG_ 134 LWI_QBit_Sub_Daten 0;
BA_ "GenSigSendType" SG_ 134 LWI_Sensorstatus 0;
BA_ "GenSigSendType" SG_ 134 LWI_Sub_Daten 0;
BA_ "GenSigSendType" SG_ 134 LWI_VZ_Lenkradw_Geschw 0;
BA_ "GenSigSendType" SG_ 134 LWI_VZ_Lenkradwinkel 0;
BA_REL_ "GenSigTimeoutTime" BU_SG_REL_ Fahrerdisplay_Kombi SG_ 810 EPS_01_BZ 500;
BA_REL_ "GenSigTimeoutTime" BU_SG_REL_ Fahrerdisplay_Kombi SG_ 810 EPS_01_CRC 500;
BA_REL_ "GenSigTimeoutTime" BU_SG_REL_ Fahrerdisplay_Kombi SG_ 810 EPS_Warnungen 500;
BA_REL_ "GenSigTimeoutTime" BU_SG_REL_ Fahrerdisplay_Kombi SG_ 1624 LV_FLA_aktiv_Anzeige 5000;
BA_REL_ "GenSigTimeoutTime" BU_SG_REL_ Fahrerdisplay_Kombi SG_ 1624 LV_Fernlicht_Anzeige 5000;
BA_REL_ "GenSigTimeoutTime" BU_SG_REL_ ICAS1_X_Gateway SG_ 779 KBI_Systemstatus 500;
BA_REL_ "GenSigTimeoutTime" BU_SG_REL_ ICAS1_X_Gateway SG_ 1719 KBI_FoD_PopUP_Quittiert 5000;
BA_REL_ "GenSigTimeoutTime" BU_SG_REL_ ICAS1_X_Gateway SG_ 2527679639 KBI_FoD_VirtualCockpitPlus_State 5000;
BA_REL_ "GenSigTimeoutTime" BU_SG_REL_ ICAS1_X_Gateway SG_ 2549088276 KBI_KD_Fehler 2500;
BA_REL_ "GenSigTimeoutTime" BU_SG_REL_ ICAS1_X_Gateway SG_ 2549088276 KN_KBI_DiagPfad 5000;
BA_REL_ "GenSigTimeoutTime" BU_SG_REL_ ICAS1_X_Gateway SG_ 2549088276 Kombi_Nachlauftyp 5000;
BA_REL_ "GenSigTimeoutTime" BU_SG_REL_ ICAS1_X_Gateway SG_ 2549088283 HUD_KD_Fehler 2500;
BA_REL_ "GenSigTimeoutTime" BU_SG_REL_ ICAS1_X_Gateway SG_ 2549088283 HUD_Nachlauftyp 5000;
BA_REL_ "GenSigTimeoutTime" BU_SG_REL_ ICAS1_X_Gateway SG_ 2549088283 KN_HUD_DiagPfad 5000;
BA_REL_ "GenSigTimeoutTime" BU_SG_REL_ ICAS1_X_Gateway SG_ 2549088371 Info_El_KD_Fehler 2500;
BA_REL_ "GenSigTimeoutTime" BU_SG_REL_ ICAS1_X_Gateway SG_ 2549088371 Info_El_Nachlauftyp 5000;
BA_REL_ "GenSigTimeoutTime" BU_SG_REL_ ICAS1_X_Gateway SG_ 2549088371 KN_Info_El_DiagPfad 5000;
BA_REL_ "GenSigTimeoutTime" BU_SG_REL_ ICAS1_X_Gateway SG_ 2549088521 DispKBI_FS_KD_Fehler 2500;
BA_REL_ "GenSigTimeoutTime" BU_SG_REL_ ICAS1_X_Gateway SG_ 2549088521 DispKBI_FS_Nachlauftyp 5000;
BA_REL_ "GenSigTimeoutTime" BU_SG_REL_ ICAS1_X_Gateway SG_ 2549088521 KN_DispKBI_FS_DiagPfad 5000;
BA_REL_ "GenSigTimeoutTime" BU_SG_REL_ ICAS1_X_Gateway SG_ 2549088524 KN_SmLi_01_DiagPfad 5000;
BA_REL_ "GenSigTimeoutTime" BU_SG_REL_ ICAS1_X_Gateway SG_ 2549088524 SmLi_01_KD_Fehler 2500;
BA_REL_ "GenSigTimeoutTime" BU_SG_REL_ ICAS1_X_Gateway SG_ 2549088524 SmLi_01_Nachlauftyp 5000;
BA_REL_ "GenSigTimeoutTime" BU_SG_REL_ ICAS3_Gateway SG_ 134 LWI_Lenkradwinkel 500;
BA_REL_ "GenSigTimeoutTime" BU_SG_REL_ ICAS3_Gateway SG_ 134 LWI_QBit_Lenkradwinkel 500;
BA_REL_ "GenSigTimeoutTime" BU_SG_REL_ ICAS3_Gateway SG_ 134 LWI_Sensorstatus 500;
BA_REL_ "GenSigTimeoutTime" BU_SG_REL_ ICAS3_Gateway SG_ 134 LWI_VZ_Lenkradwinkel 500;
BA_REL_ "GenSigTimeoutTime" BU_SG_REL_ ICAS3_Gateway SG_ 981 BCM_Rueckfahrlicht_Anf 1000;
BA_REL_ "GenSigTimeoutTime" BU_SG_REL_ ICAS3_Gateway SG_ 1505 BCM1_Aussen_Temp_ungef 2000;
BA_REL_ "GenSigTimeoutTime" BU_SG_REL_ ICAS3_Gateway SG_ 1649 KL_Hinweis_Kuehlmodus 5000;
BA_REL_ "GenSigTimeoutTime" BU_SG_REL_ ICAS3_Gateway SG_ 1720 KBI_Tankinhalt_hochaufl 5000;
BA_REL_ "GenSigTimeoutTime" BU_SG_REL_ ICAS3_Gateway SG_ 2527679635 KL_ZR_Anforderung 5000;
BA_REL_ "GenSigTimeoutTime" BU_SG_REL_ ICAS3_Gateway SG_ 2527679675 LiSi_Touch_Event 500;
BA_REL_ "GenSigTimeoutTime" BU_SG_REL_ ICC_IO_Node SG_ 2527679675 LiSi_Touch_Event 500;
BA_REL_ "GenSigTimeoutTime" BU_SG_REL_ Kombi SG_ 810 EPS_01_BZ 500;
BA_REL_ "GenSigTimeoutTime" BU_SG_REL_ Kombi SG_ 810 EPS_01_CRC 500;
BA_REL_ "GenSigTimeoutTime" BU_SG_REL_ Kombi SG_ 810 EPS_Warnungen 500;
BA_REL_ "GenSigTimeoutTime" BU_SG_REL_ Kombi SG_ 919 LDW_Gong 1000;
BA_REL_ "GenSigTimeoutTime" BU_SG_REL_ Kombi SG_ 919 LDW_Lernmodus_seitenabhaengig 1000;
BA_REL_ "GenSigTimeoutTime" BU_SG_REL_ Kombi SG_ 919 LDW_Status_Anzeige 1000;
BA_REL_ "GenSigTimeoutTime" BU_SG_REL_ Kombi SG_ 919 LDW_Texte 1000;
BA_REL_ "GenSigTimeoutTime" BU_SG_REL_ Kombi SG_ 919 aLDW_FoD_Status 1000;
BA_REL_ "GenSigTimeoutTime" BU_SG_REL_ Kombi SG_ 981 BCM1_Abblendlicht_Anf 1000;
BA_REL_ "GenSigTimeoutTime" BU_SG_REL_ Kombi SG_ 981 BCM1_Fahrlicht_Hinweis 1000;
BA_REL_ "GenSigTimeoutTime" BU_SG_REL_ Kombi SG_ 981 BCM1_Hinweis_Lichtnachlauf 1000;
BA_REL_ "GenSigTimeoutTime" BU_SG_REL_ Kombi SG_ 981 BCM1_Lichtwarn_Texte 1000;
BA_REL_ "GenSigTimeoutTime" BU_SG_REL_ Kombi SG_ 981 BCM1_Standlicht_Anf 1000;
BA_REL_ "GenSigTimeoutTime" BU_SG_REL_ Kombi SG_ 981 BCM_Rueckfahrlicht_Anf 1000;
BA_REL_ "GenSigTimeoutTime" BU_SG_REL_ Kombi SG_ 982 LH_3_Bremsl_def 1000;
BA_REL_ "GenSigTimeoutTime" BU_SG_REL_ Kombi SG_ 982 LH_Aussenlicht_def 1000;
BA_REL_ "GenSigTimeoutTime" BU_SG_REL_ Kombi SG_ 982 LH_Blinker_li_def 1000;
BA_REL_ "GenSigTimeoutTime" BU_SG_REL_ Kombi SG_ 982 LH_Blinker_re_def 1000;
BA_REL_ "GenSigTimeoutTime" BU_SG_REL_ Kombi SG_ 982 LH_Brems_Blk_li_def 1000;
BA_REL_ "GenSigTimeoutTime" BU_SG_REL_ Kombi SG_ 982 LH_Brems_Blk_re_def 1000;
BA_REL_ "GenSigTimeoutTime" BU_SG_REL_ Kombi SG_ 982 LH_Bremsl_li_def 1000;
BA_REL_ "GenSigTimeoutTime" BU_SG_REL_ Kombi SG_ 982 LH_Bremsl_li_ges_def 1000;
BA_REL_ "GenSigTimeoutTime" BU_SG_REL_ Kombi SG_ 982 LH_Bremsl_re_def 1000;
BA_REL_ "GenSigTimeoutTime" BU_SG_REL_ Kombi SG_ 982 LH_Bremsl_re_ges_def 1000;
BA_REL_ "GenSigTimeoutTime" BU_SG_REL_ Kombi SG_ 982 LH_Bremslicht_H_aktiv 1000;
BA_REL_ "GenSigTimeoutTime" BU_SG_REL_ Kombi SG_ 982 LH_Kennzl_def 1000;
BA_REL_ "GenSigTimeoutTime" BU_SG_REL_ Kombi SG_ 982 LH_Nebel_li_def 1000;
BA_REL_ "GenSigTimeoutTime" BU_SG_REL_ Kombi SG_ 982 LH_Nebel_mi_def 1000;
BA_REL_ "GenSigTimeoutTime" BU_SG_REL_ Kombi SG_ 982 LH_Nebel_re_def 1000;
BA_REL_ "GenSigTimeoutTime" BU_SG_REL_ Kombi SG_ 982 LH_Rueckf_li_def 1000;
BA_REL_ "GenSigTimeoutTime" BU_SG_REL_ Kombi SG_ 982 LH_Rueckf_mi_def 1000;
BA_REL_ "GenSigTimeoutTime" BU_SG_REL_ Kombi SG_ 982 LH_Rueckf_re_def 1000;
BA_REL_ "GenSigTimeoutTime" BU_SG_REL_ Kombi SG_ 982 LH_SL_BRL_BLK_li_def 1000;
BA_REL_ "GenSigTimeoutTime" BU_SG_REL_ Kombi SG_ 982 LH_SL_BRL_BLK_re_def 1000;
BA_REL_ "GenSigTimeoutTime" BU_SG_REL_ Kombi SG_ 982 LH_Schluss_Brems_Nebel_li_def 1000;
BA_REL_ "GenSigTimeoutTime" BU_SG_REL_ Kombi SG_ 982 LH_Schluss_Brems_Nebel_re_def 1000;
BA_REL_ "GenSigTimeoutTime" BU_SG_REL_ Kombi SG_ 982 LH_Schluss_Brems_li_def 1000;
BA_REL_ "GenSigTimeoutTime" BU_SG_REL_ Kombi SG_ 982 LH_Schluss_Brems_mi_def 1000;
BA_REL_ "GenSigTimeoutTime" BU_SG_REL_ Kombi SG_ 982 LH_Schluss_Brems_re_def 1000;
BA_REL_ "GenSigTimeoutTime" BU_SG_REL_ Kombi SG_ 982 LH_Schluss_Nebel_li_def 1000;
BA_REL_ "GenSigTimeoutTime" BU_SG_REL_ Kombi SG_ 982 LH_Schluss_Nebel_re_def 1000;
BA_REL_ "GenSigTimeoutTime" BU_SG_REL_ Kombi SG_ 982 LH_Schlusslicht_li_def 1000;
BA_REL_ "GenSigTimeoutTime" BU_SG_REL_ Kombi SG_ 982 LH_Schlusslicht_mi_def 1000;
BA_REL_ "GenSigTimeoutTime" BU_SG_REL_ Kombi SG_ 982 LH_Schlusslicht_re_def 1000;
BA_REL_ "GenSigTimeoutTime" BU_SG_REL_ Kombi SG_ 1505 BCM1_Aussen_Temp_ungef 2000;
BA_REL_ "GenSigTimeoutTime" BU_SG_REL_ Kombi SG_ 1505 BCM1_FStatus_Aussentemp_ungef 2000;
BA_REL_ "GenSigTimeoutTime" BU_SG_REL_ Kombi SG_ 1624 LV_AFL_aktiv_Anzeige 5000;
BA_REL_ "GenSigTimeoutTime" BU_SG_REL_ Kombi SG_ 1624 LV_AFL_defekt 5000;
BA_REL_ "GenSigTimeoutTime" BU_SG_REL_ Kombi SG_ 1624 LV_Abbiegelicht_li_def 5000;
BA_REL_ "GenSigTimeoutTime" BU_SG_REL_ Kombi SG_ 1624 LV_Abbiegelicht_re_def 5000;
BA_REL_ "GenSigTimeoutTime" BU_SG_REL_ Kombi SG_ 1624 LV_Abblend_Fernlicht_li_def 5000;
BA_REL_ "GenSigTimeoutTime" BU_SG_REL_ Kombi SG_ 1624 LV_Abblend_Fernlicht_re_def 5000;
BA_REL_ "GenSigTimeoutTime" BU_SG_REL_ Kombi SG_ 1624 LV_Abblendlicht_Anzeige 5000;
BA_REL_ "GenSigTimeoutTime" BU_SG_REL_ Kombi SG_ 1624 LV_Abblendlicht_TFL_li_def 5000;
BA_REL_ "GenSigTimeoutTime" BU_SG_REL_ Kombi SG_ 1624 LV_Abblendlicht_TFL_re_def 5000;
BA_REL_ "GenSigTimeoutTime" BU_SG_REL_ Kombi SG_ 1624 LV_Abblendlicht_li_def 5000;
BA_REL_ "GenSigTimeoutTime" BU_SG_REL_ Kombi SG_ 1624 LV_Abblendlicht_re_def 5000;
BA_REL_ "GenSigTimeoutTime" BU_SG_REL_ Kombi SG_ 1624 LV_Aussenlicht_def 5000;
BA_REL_ "GenSigTimeoutTime" BU_SG_REL_ Kombi SG_ 1624 LV_Blinker_li_def 5000;
BA_REL_ "GenSigTimeoutTime" BU_SG_REL_ Kombi SG_ 1624 LV_Blinker_re_def 5000;
BA_REL_ "GenSigTimeoutTime" BU_SG_REL_ Kombi SG_ 1624 LV_Blk_li_Seite_def 5000;
BA_REL_ "GenSigTimeoutTime" BU_SG_REL_ Kombi SG_ 1624 LV_Blk_re_Seite_def 5000;
BA_REL_ "GenSigTimeoutTime" BU_SG_REL_ Kombi SG_ 1624 LV_FLA_Sensor_blockiert 5000;
BA_REL_ "GenSigTimeoutTime" BU_SG_REL_ Kombi SG_ 1624 LV_FLA_aktiv_Anzeige 5000;
BA_REL_ "GenSigTimeoutTime" BU_SG_REL_ Kombi SG_ 1624 LV_FLA_defekt 5000;
BA_REL_ "GenSigTimeoutTime" BU_SG_REL_ Kombi SG_ 1624 LV_Fernlicht_Anzeige 5000;
BA_REL_ "GenSigTimeoutTime" BU_SG_REL_ Kombi SG_ 1624 LV_Fernlicht_li_def 5000;
BA_REL_ "GenSigTimeoutTime" BU_SG_REL_ Kombi SG_ 1624 LV_Fernlicht_re_def 5000;
BA_REL_ "GenSigTimeoutTime" BU_SG_REL_ Kombi SG_ 1624 LV_LED_Scheinwerfer_li_def 5000;
BA_REL_ "GenSigTimeoutTime" BU_SG_REL_ Kombi SG_ 1624 LV_LED_Scheinwerfer_re_def 5000;
BA_REL_ "GenSigTimeoutTime" BU_SG_REL_ Kombi SG_ 1624 LV_MXB_Status_Anzeige 5000;
BA_REL_ "GenSigTimeoutTime" BU_SG_REL_ Kombi SG_ 1624 LV_Nebellicht_Anzeige 5000;
BA_REL_ "GenSigTimeoutTime" BU_SG_REL_ Kombi SG_ 1624 LV_Nebellicht_TFL_li_def 5000;
BA_REL_ "GenSigTimeoutTime" BU_SG_REL_ Kombi SG_ 1624 LV_Nebellicht_TFL_re_def 5000;
BA_REL_ "GenSigTimeoutTime" BU_SG_REL_ Kombi SG_ 1624 LV_Nebellicht_li_def 5000;
BA_REL_ "GenSigTimeoutTime" BU_SG_REL_ Kombi SG_ 1624 LV_Nebellicht_re_def 5000;
BA_REL_ "GenSigTimeoutTime" BU_SG_REL_ Kombi SG_ 1624 LV_Nebelschlusslicht_Anzeige 5000;
BA_REL_ "GenSigTimeoutTime" BU_SG_REL_ Kombi SG_ 1624 LV_Standlicht_Anzeige 5000;
BA_REL_ "GenSigTimeoutTime" BU_SG_REL_ Kombi SG_ 1624 LV_Standlicht_TFL_li_def 5000;
BA_REL_ "GenSigTimeoutTime" BU_SG_REL_ Kombi SG_ 1624 LV_Standlicht_TFL_re_def 5000;
BA_REL_ "GenSigTimeoutTime" BU_SG_REL_ Kombi SG_ 1624 LV_Standlicht_li_def 5000;
BA_REL_ "GenSigTimeoutTime" BU_SG_REL_ Kombi SG_ 1624 LV_Standlicht_re_def 5000;
BA_REL_ "GenSigTimeoutTime" BU_SG_REL_ Kombi SG_ 1624 LV_Tagfahrlicht_Anzeige 5000;
BA_REL_ "GenSigTimeoutTime" BU_SG_REL_ Kombi SG_ 1624 LV_Tagfahrlicht_li_def 5000;
BA_REL_ "GenSigTimeoutTime" BU_SG_REL_ Kombi SG_ 1624 LV_Tagfahrlicht_re_def 5000;
BA_REL_ "GenSigTimeoutTime" BU_SG_REL_ Kombi SG_ 1640 KL_LRH_Stufe 2000;
BA_REL_ "GenSigTimeoutTime" BU_SG_REL_ Kombi SG_ 1646 KL_BCmE_Livetip_Freigabe 5000;
BA_REL_ "GenSigTimeoutTime" BU_SG_REL_ Kombi SG_ 1646 KL_Geblaese_Status 5000;
BA_REL_ "GenSigTimeoutTime" BU_SG_REL_ Kombi SG_ 1649 KL_Hinweis_Kuehlmodus 5000;
BA_REL_ "GenSigTimeoutTime" BU_SG_REL_ Kombi SG_ 1649 KL_Meldung_Status 5000;
BA_REL_ "GenSigTimeoutTime" BU_SG_REL_ SmartLight_01 SG_ 1646 KL_Innen_Temp 5000;
BA_REL_ "GenSigTimeoutTime" BU_SG_REL_ ZR_MIB_TOP_ab_Gen3 SG_ 134 LWI_Lenkradw_Geschw 500;
BA_REL_ "GenSigTimeoutTime" BU_SG_REL_ ZR_MIB_TOP_ab_Gen3 SG_ 134 LWI_Lenkradwinkel 500;
BA_REL_ "GenSigTimeoutTime" BU_SG_REL_ ZR_MIB_TOP_ab_Gen3 SG_ 134 LWI_QBit_Lenkradwinkel 500;
BA_REL_ "GenSigTimeoutTime" BU_SG_REL_ ZR_MIB_TOP_ab_Gen3 SG_ 134 LWI_Sensorstatus 500;
BA_REL_ "GenSigTimeoutTime" BU_SG_REL_ ZR_MIB_TOP_ab_Gen3 SG_ 134 LWI_VZ_Lenkradw_Geschw 500;
BA_REL_ "GenSigTimeoutTime" BU_SG_REL_ ZR_MIB_TOP_ab_Gen3 SG_ 134 LWI_VZ_Lenkradwinkel 500;
BA_REL_ "GenSigTimeoutTime" BU_SG_REL_ ZR_MIB_TOP_ab_Gen3 SG_ 779 KBI_MFA_v_Einheit_01 500;
BA_REL_ "GenSigTimeoutTime" BU_SG_REL_ ZR_MIB_TOP_ab_Gen3 SG_ 779 KBI_V_Digital 500;
BA_REL_ "GenSigTimeoutTime" BU_SG_REL_ ZR_MIB_TOP_ab_Gen3 SG_ 919 aLDW_FoD_Status 1000;
BA_REL_ "GenSigTimeoutTime" BU_SG_REL_ ZR_MIB_TOP_ab_Gen3 SG_ 981 BCM_Rueckfahrlicht_Anf 1000;
BA_REL_ "GenSigTimeoutTime" BU_SG_REL_ ZR_MIB_TOP_ab_Gen3 SG_ 1614 KBI_HUD_Data_01 5000;
BA_REL_ "GenSigTimeoutTime" BU_SG_REL_ ZR_MIB_TOP_ab_Gen3 SG_ 1614 KBI_HUD_Data_02 5000;
BA_REL_ "GenSigTimeoutTime" BU_SG_REL_ ZR_MIB_TOP_ab_Gen3 SG_ 1614 KBI_HUD_Data_03 5000;
BA_REL_ "GenSigTimeoutTime" BU_SG_REL_ ZR_MIB_TOP_ab_Gen3 SG_ 1614 KBI_HUD_Data_04 5000;
BA_REL_ "GenSigTimeoutTime" BU_SG_REL_ ZR_MIB_TOP_ab_Gen3 SG_ 1614 KBI_HUD_Data_05 5000;
BA_REL_ "GenSigTimeoutTime" BU_SG_REL_ ZR_MIB_TOP_ab_Gen3 SG_ 1614 KBI_HUD_Data_06 5000;
BA_REL_ "GenSigTimeoutTime" BU_SG_REL_ ZR_MIB_TOP_ab_Gen3 SG_ 1614 KBI_HUD_Data_07 5000;
BA_REL_ "GenSigTimeoutTime" BU_SG_REL_ ZR_MIB_TOP_ab_Gen3 SG_ 1614 KBI_HUD_Data_08 5000;
BA_REL_ "GenSigTimeoutTime" BU_SG_REL_ ZR_MIB_TOP_ab_Gen3 SG_ 1640 KL_I_Geblaese 2000;
BA_REL_ "GenSigTimeoutTime" BU_SG_REL_ ZR_MIB_TOP_ab_Gen3 SG_ 1649 KL_Meldung_Status 5000;
BA_REL_ "GenSigTimeoutTime" BU_SG_REL_ ZR_MIB_TOP_ab_Gen3 SG_ 1719 KBI_FStatus_Tank 5000;
BA_REL_ "GenSigTimeoutTime" BU_SG_REL_ ZR_MIB_TOP_ab_Gen3 SG_ 2527679635 KL_ZR_Anforderung 5000;
VAL_ 1646 KL_Anf_AussenspiegelHzg 0 "nicht_angefordert" 1 "angefordert" ;
VAL_ 1646 KL_BCmE_Livetip_Freigabe 0 "Anzeige_Livetip_nicht_zulaessig" 1 "Anzeige_Livetip_zulaessig" ;
VAL_ 1646 KL_ErwVK_Anf 0 "nicht_angefordert" 1 "angefordert" ;
VAL_ 1646 KL_FSH_Automatikbetrieb 0 "aus" 1 "angefordert_durch_Regelung" ;
VAL_ 1646 KL_Geblaese_Fond_Status 0 "Geblaese_aus" 1 "Geblaesestufe_10" 2 "Geblaesestufe_20" 3 "Geblaesestufe_30" 4 "Geblaesestufe_40" 5 "Geblaesestufe_50" 6 "Geblaesestufe_60" 7 "Geblaesestufe_70" 8 "Geblaesestufe_80" 9 "Geblaesestufe_90" 10 "Geblaesestufe_100" 14 "Init" 15 "Fehler" ;
VAL_ 1646 KL_Geblaese_Status 0 "Geblaese_aus" 1 "Geblaesestufe_10" 2 "Geblaesestufe_20" 3 "Geblaesestufe_30" 4 "Geblaesestufe_40" 5 "Geblaesestufe_50" 6 "Geblaesestufe_60" 7 "Geblaesestufe_70" 8 "Geblaesestufe_80" 9 "Geblaesestufe_90" 10 "Geblaesestufe_100" 14 "Init" 15 "Fehler" ;
VAL_ 1646 KL_Heizkreisventilstellung 0 "Init" 1 "Ventilstellung_gem_Anforderung" 2 "Ventilstellung_abweichend_Anf" 3 "Fehler" ;
VAL_ 1646 KL_I_Geblaese_Fond 255 "Fehler" ;
VAL_ 1646 KL_Innen_Temp 253 "nicht_verbaut" 254 "nicht_verfuegbar" 255 "Fehler" ;
VAL_ 1646 KL_Kompressorkupplung 0 "oeffnen" 1 "schliessen" ;
VAL_ 1646 KL_Magnetventil 0 "Aus" 1 "Ein" ;
VAL_ 1646 KL_Restwaerme_aktiv 0 "inaktiv" 1 "aktiv" ;
VAL_ 1646 KL_SIH_LEH_Verteilung_VL 0 "gleichmaessige_Verteilung" 1 "Sitz_Prio_Hoch" 2 "Sitz_Prio_Mittel" 3 "Sitz_Prio_Niedrig" 4 "Lehne_Prio_Niedrig" 5 "Lehne_Prio_Mittel" 6 "Lehne_Prio_Hoch" ;
VAL_ 1646 KL_SIH_LEH_Verteilung_VR 0 "gleichmaessige_Verteilung" 1 "Sitz_Prio_Hoch" 2 "Sitz_Prio_Mittel" 3 "Sitz_Prio_Niedrig" 4 "Lehne_Prio_Niedrig" 5 "Lehne_Prio_Mittel" 6 "Lehne_Prio_Hoch" ;
VAL_ 1646 KL_SIH_LEL_Verteilung_VL 0 "gleichmaessige_Verteilung" 1 "Sitz_Prio_Hoch" 2 "Sitz_Prio_Mittel" 3 "Sitz_Prio_Niedrig" 4 "Lehne_Prio_Niedrig" 5 "Lehne_Prio_Mittel" 6 "Lehne_Prio_Hoch" ;
VAL_ 1646 KL_SIH_LEL_Verteilung_VR 0 "gleichmaessige_Verteilung" 1 "Sitz_Prio_Hoch" 2 "Sitz_Prio_Mittel" 3 "Sitz_Prio_Niedrig" 4 "Lehne_Prio_Niedrig" 5 "Lehne_Prio_Mittel" 6 "Lehne_Prio_Hoch" ;
VAL_ 1646 KL_Solarluefter_aktiv 0 "Solarluefter_nicht_aktiv" 1 "Solarluefter_aktiv__auto" ;
VAL_ 1646 KL_STH_aktiv 0 "Standheizung_nicht_aktiv" 1 "Standheizung_aktiv" ;
VAL_ 1646 KL_STH_Ansteuerung 0 "Aus" 1 "Ein" 2 "Ein_mit_Motorvorwaermung" 3 "Heizleistung_reduziert" ;
VAL_ 1646 KL_STL_aktiv 0 "Standlueftung_nicht_aktiv" 1 "Standlueftung_aktiv" ;
VAL_ 1646 KL_Umluft_Taste 0 "Taste_nicht_gedrueckt" 1 "Taste_gedrueckt" ;
VAL_ 1646 KL_WaPu 0 "Wasserpumpe_aus" 1 "Wasserpumpe_aktiv" ;
VAL_ 1649 KL_Betriebsmodus_FH 0 "undefined__init" 1 "Klemme15" 2 "Standheizung" 3 "Restwaerme" 4 "Nachlauf" 5 "Standlueften" 6 "Betriebsart_X" 7 "Betriebsart_Y" ;
VAL_ 1649 KL_ErwVK_Beifahrerzone 0 "nicht_aktiv" 1 "Beifahrerzone_aktiv" ;
VAL_ 1649 KL_ErwVK_Fahrerzone 0 "nicht_aktiv" 1 "Fahrerzone_aktiv" ;
VAL_ 1649 KL_ErwVK_Heckzone_links 0 "nicht_aktiv" 1 "Heckzone_links_aktiv" ;
VAL_ 1649 Kl_ErwVK_Heckzone_rechts 0 "nicht_aktiv" 1 "Heckzone_rechts_aktiv" ;
VAL_ 1649 KL_ErwVK_Scheibenheizung 0 "nicht_aktiv" 1 "Scheibenheizung_aktiv" ;
VAL_ 1649 KL_ErwVK_Status 0 "nicht_angefordert" 1 "Fahrerzone_aktiv" 2 "Beifahrerzone_aktiv" 3 "Heckzone_links_aktiv" 4 "Heckzone_recht_aktiv" 5 "Scheibenheizung_aktiv" ;
VAL_ 1649 KL_Hinweis_Kuehlmodus 0 "aus" 1 "Stufe1" 2 "Stufe2" 3 "Stufe3" ;
VAL_ 1649 KL_Meldung_Status 0 "keine_notification" 1 "Klima_eingeschraenkt" 2 "Klima_Warnung" 3 "Service_Klima" 4 "Fahrzeug_Lueften_Gelb" 5 "Fahrzeug_Lueften_Rot" 6 "Fahrzeug_Lueften_3" 7 "Klima_Abwurf" 8 "reserve_1" 9 "reserve_2" ;
VAL_ 1649 KL_Stopp_Wiederstart_Anz_01 0 "keine_Anzeige" 1 "Geblaese" ;
VAL_ 1649 KL_Stopp_Wiederstart_Anz_02 0 "keine_Anzeige" 1 "Differenz_Soll_Ausblas_zu_Ist_Ausblastemperatur" ;
VAL_ 1649 KL_Stopp_Wiederstart_Anz_03 0 "keine_Anzeige" 1 "Beschlagsgefahr" ;
VAL_ 1649 KL_Stopp_Wiederstart_Anz_04 0 "keine_Anzeige" 1 "Differenz_Soll_Innentemperatur_zu_Ist_Innenraumtemperatur" ;
VAL_ 1649 KL_Stopp_Wiederstart_Anz_05 0 "keine_Anzeige" 1 "Komfortfeuchte" ;
VAL_ 1649 KL_Stopp_Wiederstart_Anz_06 0 "keine_Anzeige" 1 "Aussentemperatur" ;
VAL_ 1649 KL_Stopp_Wiederstart_Anz_07 0 "keine_Anzeige" 1 "Defrost" ;
VAL_ 1649 KL_Stopp_Wiederstart_Anz_08 0 "keine_Anzeige" 1 "High_Low" ;
VAL_ 1649 KL_Stopp_Wiederstart_Anz_09 0 "keine_Anzeige" 1 "Frontscheibenheizung" ;
VAL_ 1649 KL_Stopp_Wiederstart_Anz_Std1 0 "keine_Anzeige" 1 "maxA/C" ;
VAL_ 1649 KL_Stopp_Wiederstart_Anz_Std2 0 "keine_Anzeige" 1 "Sitzlueftung" ;
VAL_ 1649 KL_ZZ_Betriebsmodus 0 "Do_not_Care" 1 "ECO" 2 "Standard" 3 "Standard_plus" 4 "Comfort" ;
VAL_ 1649 KL_ZZ_Monat 0 "Init" ;
VAL_ 1649 KL_ZZ_Status_Timer 0 "Timer_n_aktiv_bzw_loeschen" 1 "Timer_aktiv_bzw_aktivieren" ;
VAL_ 1649 KL_ZZ_Tag 0 "Init" ;
VAL_ 1640 FSH_Taster 0 "nicht_betaetigt" 1 "betaetigt" ;
VAL_ 1640 HSH_Taster 0 "nicht_betaetigt" 1 "short_push" 2 "long_push" 3 "tbd" ;
VAL_ 1640 KL_Beschlagsgefahr 0 "keine_Beschlagsgefahr" 1 "Beschlagsgefahr" ;
VAL_ 1640 KL_Geblspng_Fond_Soll 0 "0V_Motorspannung" 252 "0V_sofort_Abschalten" 253 "0V_senken_mit_Rampe" 254 "reserviert" 255 "Fehler" ;
VAL_ 1640 KL_Geblspng_Soll 0 "0V_Motorspannung" 252 "0V_sofort_Abschalten" 253 "0V_senken_mit_Rampe" 254 "reserviert" 255 "Fehler" ;
VAL_ 1640 KL_I_Geblaese 255 "Fehler" ;
VAL_ 1640 KL_Kompressorstrom_soll 1022 "Init" 1023 "Fehler" ;
VAL_ 1640 KL_LRH_Stufe 0 "Stufe_niedrig" 1 "Stufe_mittel" 2 "Stufe_hoch" 3 "AUS" ;
VAL_ 1640 KL_LRH_Taster 0 "nicht_betaetigt" 1 "betaetigt" ;
VAL_ 1640 KL_PTC_Verbauinfo 0 "kein_PTC" 1 "600W_geschaltet" 2 "1000W_geschaltet" 3 "1400W_LIN" ;
VAL_ 1640 KL_Umluftklappe_Status 0 "Frischluft" 1 "Teilumluft_10" 2 "Teilumluft_20" 3 "Teilumluft_30" 4 "Teilumluft_40" 5 "Teilumluft_50" 6 "Teilumluft_60" 7 "Teilumluft_70" 8 "Teilumluft_80" 9 "Teilumluft_90" 10 "Umluft" 14 "Init" 15 "Fehler" ;
VAL_ 1640 KL_Zuheizer_Freigabe 0 "keine_Freigabe_Zuheizer" 1 "Zuheizerfreigabe" ;
VAL_ 1640 KRH_Soll_li 0 "aus" 1 "Stufe_1" 2 "Stufe_2" 3 "Stufe_3" ;
VAL_ 1640 KRH_Soll_re 0 "aus" 1 "Stufe_1" 2 "Stufe_2" 3 "Stufe_3" ;
VAL_ 2527679635 FSH_Status 0 "aus" 1 "ein" 2 "tbd" 3 "Fehler" ;
VAL_ 2527679635 HSH_Relais_Anf 0 "nicht_angefordert" 1 "angefordert" ;
VAL_ 2527679635 KL_AL_HL_Anf 0 "Init" 1 "waermer" 2 "kaelter" ;
VAL_ 2527679635 KL_AL_HR_Anf 0 "Init" 1 "waermer" 2 "kaelter" ;
VAL_ 2527679635 KL_AL_VL_Anf 0 "Init" 1 "waermer" 2 "kaelter" ;
VAL_ 2527679635 KL_AL_VR_Anf 0 "Init" 1 "waermer" 2 "kaelter" ;
VAL_ 2527679635 KL_Defrost_LED 0 "Aus" 1 "Ein" ;
VAL_ 2527679635 KL_FSH_LED 0 "Aus" 1 "Ein" ;
VAL_ 2527679635 KL_FSH_Soll 0 "nicht_angefordert" 1 "angefordert" ;
VAL_ 2527679635 KL_Heizstufe_LSH 0 "Init" 1 "Stufe_1" 2 "Stufe_2" 3 "Stufe_3" 4 "Stufe_4" 5 "Stufe_5" 6 "Stufe_6" 7 "Stufe_7" 8 "Stufe_8" 9 "Stufe_9" 10 "Stufe_10" 15 "Fehler" ;
VAL_ 2527679635 KL_HSH_LED 0 "Aus" 1 "Ein" ;
VAL_ 2527679635 KL_HSH_Soll 0 "nicht_angefordert" 1 "angefordert" ;
VAL_ 2527679635 KL_HUP_aktiv 0 "Aus" 1 "Ein" ;
VAL_ 2527679635 KL_Klappe_Status 0 "Init" 1 "Front" 2 "Heck" 3 "Front_u_Heck" 4 "misch_Front_u_Heck" ;
VAL_ 2527679635 KL_LRH_Soll 0 "nicht_angefordert" 1 "angefordert" ;
VAL_ 2527679635 KL_LSH_Ansteuerung 0 "Aus" 1 "Ein" 2 "Kombi_Betrieb" 3 "Heizleistung_reduziert" ;
VAL_ 2527679635 KL_LSH_Betriebsdauer 127 "Dauerbetrieb" ;
VAL_ 2527679635 KL_LSH_DBetr_Bestaet 0 "kein_Dauerbetrieb" 1 "Dauerbetrieb_bestaetigt" ;
VAL_ 2527679635 KL_LSH_DBetr_Ein 0 "Dauerbetrieb_nicht_gefordert" 1 "Dauerbetrieb_gefordert" ;
VAL_ 2527679635 KL_Temp_ZH_Soll 0 "Funk_nicht_verbaut_nicht_aktiv" 255 "Fehler" ;
VAL_ 2527679635 KL_VoKo_LED 0 "Aus" 1 "Ein" ;
VAL_ 2527679635 KL_Voko_Status 0 "aus" 1 "ein" 14 "Init" 15 "Fehler" ;
VAL_ 2527679635 KL_ZR_Anforderung 0 "init" 1 "inaktiv" 2 "aktiv" 3 "reserviert" ;
VAL_ 2527679635 SIH_Stufe_LED_li 0 "Aus" 2 "Stufe_2" 4 "Stufe_4" 6 "Stufe_6" ;
VAL_ 2527679635 SIH_Stufe_LED_re 0 "Aus" 2 "Stufe_2" 4 "Stufe_4" 6 "Stufe_6" ;
VAL_ 1505 BCM1_Aussen_Temp_ungef 253 "nicht_verbaut" 254 "Initwert" 255 "Fehler" ;
VAL_ 1505 BCM1_FStatus_Aussentemp_ungef 0 "iO" 1 "niO" ;
VAL_ 1505 BCM1_Kompressorstrom_ist 254 "Init, bzw. nicht verfuegbar" 255 "Fehler" ;
VAL_ 1505 BCM1_OBD_FStatus_ATemp 0 "kein Fehler / Init / nicht verbaut" 1 "KS- (Kurzschluss nach minus)" 2 "KS+ (Kurzschluss nach plus)" 3 "OC (Leitungsunterbrechung)" 4 "OOR+ (Signal zu gross)" 5 "OOR- (Signal zu klein)" 6 "RC+ (Signal unplausibel zu gross)" 7 "RC- (Signal unplausibel zu klein)" 8 "KS+/OC (Kurzschluss nach plus/Unterbrechung)" 9 "KS-/OC (Kurzschluss nach minus/Unterbrechung)" 10 "KS-/KS+ (Kurzschluss nach minus/plus)" 11 "KS-/KS+/OC (Kurzschluss nach minus/plus/Unterbrechung)" 12 "frei" 13 "frei" 14 "frei" 15 "frei" ;
VAL_ 1505 BCM1_PTC_stufig_Status 0 "Aus" 1 "Stufe_1_aktiv" 2 "Stufe_2_aktiv" 3 "Stufe_3_aktiv" 6 "Init_oder_nicht_verbaut" 7 "Fehler" ;
VAL_ 1505 BCM_Heizungsabsperrventil_Status 0 "HAV_offen" 1 "HAV_geschlossen" 2 "Init_oder_nicht_verbaut" 3 "Fehler" ;
VAL_ 1505 BCM_Heizungspumpe_Status 0 "Pumpe_aus" 1 "Pumpe_aktiv_und_Stauts_iO" 2 "Init_oder_nicht_verbaut" 3 "Fehler" ;
VAL_ 1505 BCM_Kompressorkupplung_Status 0 "Kupplung_offen" 1 "Kupplung_geschlossen" 2 "Init_oder_nicht_verbaut" 3 "Fehler" ;
VAL_ 2549088521 DispKBI_FS_Abschaltstufe 0 "keine_Einschraenkung" 1 "Funktionseinschraenkung" ;
VAL_ 2549088521 DispKBI_FS_KD_Fehler 0 "Kein KD_Fehler" 1 "KD_Fehler" ;
VAL_ 2549088521 DispKBI_FS_KompSchutz 0 "inaktiv" 1 "aktiv" ;
VAL_ 2549088521 DispKBI_FS_Nachlauftyp 0 "Komm_bei_KL15_EIN" 1 "Komm_nach_KL15_AUS" 2 "Komm_bei_KL15_AUS" ;
VAL_ 2549088521 DispKBI_FS_Transport_Mode 0 "keine_Einschraenkung" 1 "Funktionseinschraenkung" ;
VAL_ 2549088521 KN_DispKBI_FS_BusKnockOut 0 "Funktion_nicht_ausgeloest" 1 "Veto_aktiv" 2 "Funktion_ausgeloest" 3 "Funktion_deaktiviert" ;
VAL_ 2549088521 KN_DispKBI_FS_BusKnockOutTimer 255 "BusKnockOut_deaktiviert" ;
VAL_ 2549088521 KN_DispKBI_FS_DiagPfad 0 "aktiv" 1 "inaktiv" ;
VAL_ 2549088521 KN_DispKBI_FS_ECUKnockOut 0 "Funktion_nicht_ausgeloest" 1 "Veto_war_aktiv" 2 "Funktion_ausgeloest" 3 "Funktion_deaktiviert" ;
VAL_ 2549088521 KN_DispKBI_FS_ECUKnockOutTimer 63 "ECUKnockOut_deaktiviert" ;
VAL_ 2549088521 NM_DispKBI_FS_Wakeup 0 "Peripherie_Wakeup__Ursache_nicht_bekannt" 1 "Bus_Wakeup" 2 "KL15_HW" 3 "KL30_Reset" ;
VAL_ 2549088272 Gateway_Abschaltstufe 0 "keine_Einschraenkung" 1 "Funktionseinschraenkung" ;
VAL_ 2549088272 Gateway_KompSchutz 0 "inaktiv" 1 "aktiv" ;
VAL_ 2549088272 Gateway_Nachlauftyp 0 "Komm_bei_KL15_EIN" 1 "Komm_nach_KL15_AUS" 2 "Komm_bei_KL15_AUS" ;
VAL_ 2549088272 Gateway_Transport_Mode 0 "keine_Einschraenkung" 1 "Funktionseinschraenkung" ;
VAL_ 2549088272 GW_KD_Fehler 0 "kein_KD_Fehler" 1 "KD_Fehler" ;
VAL_ 2549088272 KN_GW_DiagPfad 0 "aktiv" 1 "inaktiv" ;
VAL_ 2549088272 NM_Gateway_Wakeup 0 "Peripherie_Wakeup__Ursache_nicht_bekannt" 1 "Bus_Wakeup" 2 "KL15_HW" 3 "ACAN_Wakeup" 4 "FCAN_Wakeup" 5 "KCAN_Wakeup" 6 "ICAN_Wakeup" 7 "DiagCAN_Wakeup" 8 "ECAN_Wakeup" 9 "Energie_LIN_Wakeup" 10 "Bedien_LIN_Wakeup" 11 "HybridCAN_Wakeup" 12 "Flexray_Wakeup" 13 "MFL_WakeUp" 14 "Ethernet" 15 "DCAN_Wakeup" 16 "K2CAN_Wakeup" 17 "CCAN" 18 "AFSCAN_Wakeup" 19 "LIN1" 20 "LIN2" 21 "LIN3" 22 "LIN4" 23 "LIN5" 24 "LIN6" 25 "FASCAN" 26 "FAS2CAN" 27 "MDKCAN" 32 "FlexRay_Branch1_WakeUp" 33 "FlexRay_Branch2_WakeUp" 34 "FlexRay_Branch3_WakeUp" 35 "FlexRay_Branch4_WakeUp" 36 "FlexRay_Branch5_WakeUp" 37 "FlexRay_Branch6_WakeUp" 38 "FlexRay_Branch7_WakeUp" 39 "FlexRay_Branch8_WakeUp" 40 "FlexRay_Branch9_WakeUp" 41 "FlexRay_Branch10_WakeUp" 42 "FlexRay_Branch11_WakeUp" 43 "FlexRay_Branch12_WakeUp" 44 "FlexRay_Branch13_WakeUp" 45 "FlexRay_Branch14_WakeUp" 46 "FlexRay_Branch15_WakeUp" 47 "FlexRay_Branch16_WakeUp" 128 "Energiemanagement" 129 "Funktionswakeup_OBDC" 130 "Hochvoltenergiemanagement" 131 "CWU_empfangen" 132 "Fuer_Bus_relevanten_FC_empfangen" 133 "OnlineDienst_empfangen" 134 "HV_Aktivieren" 135 "HV_Deaktivieren" 136 "VTS_Suche_DriverCard" 137 "VTS_Hupen_Blinken" 138 "Remote_Vehicle_Status" 139 "Plug_and_Charge" 140 "VTS_Wakeup_Infotainment" 141 "EMHLR" 142 "NFcGW_fordert_OTA_FC_an" 143 "Komponentenschutz" 144 "UserStateServer" 145 "Dimmung" 146 "Kessy" 147 "StandardAussenlicht" 148 "ParkKoordinator" 149 "HVLMDynamicChargingPOI" 150 "HVLMChargingManagementServer" 151 "HVLMExtendedChargingMonitoring" 152 "Zentralverriegelung" 153 "FunctionOnDemand" 154 "IAA" 155 "StandKlimatisierung" 156 "RealTimeMonitor" 157 "Klemmensteuerung" ;
VAL_ 2549088283 HUD_Abschaltstufe 0 "keine_Einschraenkung" 1 "Funktionseinschraenkung" ;
VAL_ 2549088283 HUD_KD_Fehler 0 "Kein_KD_Fehler" 1 "KD_Fehler" ;
VAL_ 2549088283 HUD_KompSchutz 0 "inaktiv" 1 "aktiv" ;
VAL_ 2549088283 HUD_Nachlauftyp 0 "Komm_bei_KL15_EIN" 1 "Komm_nach_KL15_AUS" 2 "Komm_bei_KL15_AUS" ;
VAL_ 2549088283 HUD_Transport_Mode 0 "keine_Einschraenkung" 1 "Funktionseinschraenkung" ;
VAL_ 2549088283 KN_HUD_BusKnockOut 0 "Funktion_nicht_ausgeloest" 1 "Veto_aktiv" 2 "Funktion_ausgeloest" 3 "Funktion_deaktiviert" ;
VAL_ 2549088283 KN_HUD_BusKnockOutTimer 255 "BusKnockOut_deaktiviert" ;
VAL_ 2549088283 KN_HUD_DiagPfad 0 "aktiv" 1 "inaktiv" ;
VAL_ 2549088283 KN_HUD_ECUKnockOut 0 "Funktion_nicht_ausgeloest" 1 "Veto_war_aktiv" 2 "Funktion_ausgeloest" 3 "Funktion_deaktiviert" ;
VAL_ 2549088283 KN_HUD_ECUKnockOutTimer 63 "ECUKnockOut_deaktiviert" ;
VAL_ 2549088283 NM_HUD_Wakeup 0 "Peripherie_Wakeup_Ursache_nicht_bekannt" 1 "Bus_Wakeup" 2 "KL15_HW" ;
VAL_ 2549088371 Info_El_Abschaltstufe 0 "keine_Einschraenkung" 1 "Funktionseinschraenkung" ;
VAL_ 2549088371 Info_El_KD_Fehler 0 "Kein_KD_Fehler" 1 "KD_Fehler" ;
VAL_ 2549088371 Info_El_KompSchutz 0 "inaktiv" 1 "aktiv" ;
VAL_ 2549088371 Info_El_Nachlauftyp 0 "Komm_bei_KL15_EIN" 1 "Komm_nach_KL15_AUS" 2 "Komm_bei_KL15_AUS" ;
VAL_ 2549088371 Info_El_Transport_Mode 0 "keine_Einschraenkung" 1 "Funktionseinschraenkung" ;
VAL_ 2549088371 KN_Info_El_BusKnockOutTimer 255 "BusKnockOut_deaktiviert" ;
VAL_ 2549088371 KN_Info_El_DiagPfad 0 "aktiv" 1 "inaktiv" ;
VAL_ 2549088371 NM_Info_El_Wakeup 0 "Peripherie_Wakeup__Ursache_nicht_bekannt" 1 "Bus_Wakeup" 2 "KL15_HW" 3 "Eject_Button" 4 "Remote_Lock_Unlock" 5 "Remote_Standheizung" 128 "WakeUp_Lock_Anf" 129 "Display_On_Anf" 130 "HMI_OnlineUpdate" ;
VAL_ 2549088276 KBI_KD_Fehler 0 "kein_KD_Fehler" 1 "KD_Fehler" ;
VAL_ 2549088276 KN_KBI_DiagPfad 0 "aktiv" 1 "inaktiv" ;
VAL_ 2549088276 KN_Kombi_BusKnockOut 0 "Funktion_nicht_ausgeloest" 1 "Veto_aktiv" 2 "Funktion_ausgeloest" 3 "Funktion_deaktiviert" ;
VAL_ 2549088276 KN_Kombi_BusKnockOutTimer 255 "BusKnockOut_deaktiviert" ;
VAL_ 2549088276 KN_Kombi_ECUKnockOut 0 "Funktion_nicht_ausgeloest" 1 "Veto_war_aktiv" 2 "Funktion_ausgeloest" 3 "Funktion_deaktiviert" ;
VAL_ 2549088276 KN_Kombi_ECUKnockOutTimer 63 "ECUKnockOut_deaktiviert" ;
VAL_ 2549088276 Kombi_Abschaltstufe 0 "keine_Einschraenkung" 1 "Funktionseinschraenkung" ;
VAL_ 2549088276 Kombi_KompSchutz 0 "inaktiv" 1 "aktiv" ;
VAL_ 2549088276 Kombi_Nachlauftyp 0 "Komm_bei_KL15_EIN" 1 "Komm_nach_KL15_AUS" 2 "Komm_bei_KL15_AUS" ;
VAL_ 2549088276 Kombi_Transport_Mode 0 "keine_Einschraenkung" 1 "Funktionseinschraenkung" ;
VAL_ 2549088276 NM_Kombi_Lokalaktiv 0 "war_nicht_lokal_aktiv" 1 "war_lokal_aktiv" ;
VAL_ 2549088276 NM_Kombi_Subsystemaktiv 0 "Subsystem_war_nicht_lokalaktiv" 1 "war_lokalaktiv" ;
VAL_ 2549088276 NM_Kombi_Wakeup 0 "Peripherie_Wakeup__Ursache_nicht_bekannt" 1 "Bus_Wakeup" 2 "KL15_HW" 3 "KL30_Reset" 128 "Timer_abgelaufen" ;
VAL_ 2549088524 KN_SmLi_01_DiagPfad 0 "aktiv" 1 "inaktiv" ;
VAL_ 2549088524 KN_SmLi_BusKnockOut 0 "Funktion_nicht_ausgeloest" 1 "Veto_aktiv" 2 "Funktion_ausgeloest" 3 "Funktion_deaktiviert" ;
VAL_ 2549088524 KN_SmLi_BusKnockOutTimer 255 "BusKnockOut_deaktiviert" ;
VAL_ 2549088524 KN_SmLi_ECUKnockOut 0 "Funktion_nicht_ausgeloest" 1 "Veto_war_aktiv" 2 "Funktion_ausgeloest" 3 "Funktion_deaktiviert" ;
VAL_ 2549088524 KN_SmLi_ECUKnockOutTimer 63 "ECUKnockOut_deaktiviert" ;
VAL_ 2549088524 NM_SmLi_01_Wakeup 0 "Peripherie_Wakeup__Ursache_nicht_bekannt" 1 "Bus_Wakeup" 2 "KL15_HW" 3 "KL30" ;
VAL_ 2549088524 SmLi_01_Abschaltstufe 0 "keine_Einschraenkung" 1 "Funktionseinschraenkung" ;
VAL_ 2549088524 SmLi_01_KD_Fehler 0 "kein_KD_Fehler" 1 "KD_Fehler" ;
VAL_ 2549088524 SmLi_01_KompSchutz 0 "inaktiv" 1 "aktiv" ;
VAL_ 2549088524 SmLi_01_Nachlauftyp 0 "Komm_bei_KL15_EIN" 1 "Komm_nach_KL15_AUS" 2 "Komm_bei_KL15_AUS" ;
VAL_ 2549088524 SmLi_01_Transport_Mode 0 "keine_Einschraenkung" 1 "Funktionseinschraenkung" ;
VAL_ 779 KBI_Anzeigefehler_LDW 0 "nicht vorhanden bzw. unterstï?½tzt" 1 "Anzeige iO" 2 "Anzeigefehler" 3 "nicht definiert" ;
VAL_ 779 KBI_Anzeigefehler_SWA 0 "nicht vorhanden bzw. unterstï?½tzt" 1 "Anzeige iO" 2 "Anzeigefehler" 3 "nicht definiert" ;
VAL_ 779 KBI_ARA_in_Anzeige 0 "ARA nicht in Anzeige" 1 "ARA in Anzeige" ;
VAL_ 779 KBI_Einheit_Tacho 0 "km/h" 1 "mph" ;
VAL_ 779 KBI_Handbremse 0 "nicht_angezogen" 1 "angezogen" ;
VAL_ 779 KBI_MFA_v_Einheit_01 0 "kmh" 1 "mph" ;
VAL_ 779 KBI_PLA_in_Anzeige 0 "PLA_nicht_in_Anzeige" 1 "PLA_in_Anzeige" ;
VAL_ 779 KBI_Systemstatus 0 "KBI_IO" 1 "KBI_System_Failure" ;
VAL_ 779 KBI_Tankwarnung 0 "Lampe aus" 1 "Lampe ein" ;
VAL_ 779 KBI_Tankwarnung_ungueltig 0 "KBI_Tankwarnung_gueltig" 1 "KBI_Tankwarnung_ungueltig" ;
VAL_ 779 KBI_Taster_Fahrwerk 0 "nicht_betaetigt" 1 "betaetigt" ;
VAL_ 779 KBI_Taster_Lift 0 "nicht_betaetigt" 1 "betaetigt" ;
VAL_ 779 KBI_Vorglueh_System_Lampe 0 "Lampe aus" 1 "Lampe ein" ;
VAL_ 1719 KBI_FoD_PopUP_Quittiert 0 "nicht_quittiert" 1 "Meldung_quittiert" ;
VAL_ 1719 KBI_FStatus_Tank 0 "Tankfï?½llstand i.O." 1 "Tankfï?½llstand n.i.O" ;
VAL_ 1720 KBI_GAP_Warn_Zeit_abgelaufen 0 "Zaehler_nicht_abgelaufen" 1 "Zaehler_abgelaufen" ;
VAL_ 1720 KBI_Max_Tankinhalt 254 "Init" 255 "Fehler" ;
VAL_ 1720 KBI_Nachtanken_erkannt 0 "Geberbetrieb" 1 "Nachtankmodus" ;
VAL_ 1720 KBI_Tankfuellstand_Prozent 126 "Init" 127 "Fehler" ;
VAL_ 1720 KBI_Tankinhalt_hochaufl 16382 "Init" 16383 "Fehler" ;
VAL_ 2527679639 AuthTime_Trigger_Distribution 0 "inaktiv" 1 "aktiv" ;
VAL_ 2527679639 KBI_FoD_VirtualCockpitPlus_State 0 "Init" 1 "locked" 2 "unlocked" ;
VAL_ 2527679639 KBI_Min_Tankinhalt 126 "Init" 127 "Fehler" ;
VAL_ 2589283631 KBI_BC_Reset_E1 0 "SG_Reset" 1 "Reset_Zaehler" 2 "Reset_Zaehler" 3 "Reset_Zaehler" 4 "Reset_Zaehler" 5 "Reset_Zaehler" 6 "Reset_Zaehler" 7 "Init" ;
VAL_ 2589283631 KBI_Tankinhalt_roh 2046 "Init" 2047 "Fehler" ;
VAL_ 1614 KBI_HUD_Data_01 0 "Init" ;
VAL_ 1614 KBI_HUD_Data_02 0 "Init" ;
VAL_ 1614 KBI_HUD_Data_03 0 "Init" ;
VAL_ 1614 KBI_HUD_Data_04 0 "Init" ;
VAL_ 1614 KBI_HUD_Data_05 0 "Init" ;
VAL_ 1614 KBI_HUD_Data_06 0 "Init" ;
VAL_ 1614 KBI_HUD_Data_07 0 "Init" ;
VAL_ 1614 KBI_HUD_Data_08 0 "Init" ;
VAL_ 919 aLDW_FoD_Status 0 "Init" 1 "Funktion_inaktiv" 2 "Funktion_aktiv" ;
VAL_ 919 HC_Uss_Anforderung 0 "Ultraschallsensoren Aus" 1 "Ultraschallsensoren An" ;
VAL_ 919 LDW_Frueh_Spaet 0 "frueh_frueh_aktiv" 1 "frueh_spaet_aktiv" 2 "spaet_spaet_aktiv" 3 "Fehler" ;
VAL_ 919 LDW_Gong 0 "kein akustisches Signal" 1 "Gong_1" 2 "Gong_2" 3 "Gong_3" ;
VAL_ 919 LDW_Lernmodus_seitenabhaengig 0 "links_aus__rechts_aus" 1 "HCCA_links_an__rechts_an" 2 "HCCA_links_an__rechts_Warnung" 3 "HCCA_links_Warnung__rechts_an" 4 "links_gestrichelt_rechts_Warnung" 5 "links_outlined__rechts_outlined" 6 "links_outlined__rechts_an" 7 "links_outlined__rechts_Warnung" 8 "links_Warnung_rechts_gestrichel" 9 "links_an__rechts_outlined" 10 "links_an__rechts_an" 11 "links_an__rechts_Warnung" 12 "links_und_rechts_gestrichelt" 13 "links_Warnung__rechts_outlined" 14 "links_Warnung__rechts_an" 15 "links_Warnung__rechts_Warnung" ;
VAL_ 919 LDW_Seite_DLCTLC 0 "links" 1 "rechts" ;
VAL_ 919 LDW_Status_Anzeige 0 "Init_keine_Anzeige" 1 "Lenkeingriff" 2 "Deaktiviert" 3 "Passiv" 4 "Aktiv" 6 "nicht_definiert" 7 "nicht_definiert" ;
VAL_ 919 LDW_Status_Grid 0 "keine_Anzeige" 1 "reduzierte_Anzeige" 2 "komplette_Anzeige" ;
VAL_ 919 LDW_Status_LED_gelb 0 "LDW-Status gelb aus" 1 "LDW-Status gelb aktiv" ;
VAL_ 919 LDW_Status_LED_gruen 0 "LDW-Status gruen aus" 1 "LDW-Status gruen aktiv" ;
VAL_ 919 LDW_Texte 0 "keine_Anzeige" 1 "Laneassist_zur_Zeit_n_verfuegbar" 2 "Laneassist_Systemfehler" 3 "Laneassist_zur_Zeit_keine_SSicht" 4 "Laneassist_Fahreruebernahme" 5 "Laneassist_n_verfuegbar_FoD" 6 "Emergency_Alert_Fahreruebernahme" 7 "Laneassist_FahreruebernahmeLeise" 8 "Laneassist_FahreruebernahmeStumm" 9 "EA_Fahrstreifenwechsel" 10 "Laneassist_Deaktiviert" 11 "Laneassist_Fahreruebernahme_hoch" 12 "Laneassist_mittig_fahren" 13 "Laneassist_adaptiv_aktiv" 14 "Laneassist_adaptiv_deaktiv" 15 "Systgr_Fzgfueh_sofort_uebernehm" ;
VAL_ 919 LDW_TLC 31 "Init" ;
VAL_ 810 EPS_Akustiksignal 0 "Akustiksignal_nicht_aktiv" 1 "Akustiksignal_aktiv" ;
VAL_ 810 EPS_Anf_KL 0 "keine_Anforderung" 1 "Anforderung_Kuehlung" ;
VAL_ 810 EPS_ARA_Status 0 "EPS_ARA_Deaktiv" 1 "EPS_ARA_Init" 2 "EPS_ARA_Fehler_mit_Eintrag" 3 "reserviert" 4 "reserviert" 5 "reserviert" 6 "EPS_ARA_Lenkwinkel_aktiv" 7 "EPS_ARA_Abgewiesen" 8 "EPS_ARA_Funktionsbereit" 9 "reserviert" 10 "EPS_ARA_Abbruch" 11 "reserviert" 12 "reserviert" 13 "reserviert" 14 "reserviert" 15 "reserviert" ;
VAL_ 810 EPS_Charisma_FahrPr 0 "keine_Funktion" 1 "Programm_1" 2 "Programm_2" 3 "Programm_3" 4 "Programm_4" 5 "Programm_5" 6 "Programm_6" 7 "Programm_7" 8 "Programm_8" 9 "Programm_9" 10 "Programm_10" 11 "Programm_11" 12 "Programm_12" 13 "Programm_13" 14 "Programm_14" 15 "Programm_15" ;
VAL_ 810 EPS_Charisma_Status 0 "Init" 1 "verfuegbar" 2 "nicht_verfuegbar" 3 "asynchron_durch_Fahrerwunsch" ;
VAL_ 810 EPS_Endanschlag 0 "Init_bzw_Defaultlenkhub" 1 "Lenkhubaufweitung_1" 2 "EA_nicht_angelernt_bzw_Initialisierung_nicht_abgeschlossen" 3 "Fehler" ;
VAL_ 810 EPS_Fehlerlampe 0 "Lampe_aus" 1 "Lampe_ein" ;
VAL_ 810 EPS_Lenkerposition 0 "unbekannt" 1 "Linkslenker" 2 "Rechtslenker" ;
VAL_ 810 EPS_PLA_Status 0 "EPS_PLA_Deaktiv" 1 "EPS_PLA_Init" 2 "EPS_PLA_Fehler_mit_Eintrag" 3 "reserviert" 4 "reserviert" 5 "reserviert" 6 "EPS_PLA_Lenkwinkel_aktiv" 7 "EPS_PLA_Abgewiesen" 8 "EPS_PLA_Funktionsbereit" 9 "reserviert" 10 "EPS_PLA_Abbruch" 11 "reserviert" 12 "reserviert" 13 "reserviert" 14 "reserviert" 15 "reserviert" ;
VAL_ 810 EPS_SpannungsAnf 0 "keine_Anforderung" 1 "Anforderung_Stufe1" 2 "Anforderung_Stufe2" 3 "Anforderung_Stufe3" ;
VAL_ 810 EPS_VZ_Zst_Offset_Geradeaus 0 "pos_VZ" 1 "neg_VZ" ;
VAL_ 810 EPS_Warnungen 0 "kein_Text" 1 "Text_1" 2 "Text_2" 3 "Text_3" 4 "Text_4" 5 "Text_5" ;
VAL_ 810 EPS_Zst_Offset_Geradeaus 510 "Init" 511 "Fehler" ;
VAL_ 981 BCM1_Abblendlicht_Anf 0 "Licht_nicht_angefordert" 1 "Licht ist einzuschalten" ;
VAL_ 981 BCM1_Adaptive_Lichtvert_Anf 0 "Aus" 1 "Ein" ;
VAL_ 981 BCM1_Allwetterlicht_Anf 0 "Licht_nicht_angefordert" 1 "Licht_ist_einzuschalten" ;
VAL_ 981 BCM1_Autobahnlicht_Anf 0 "Licht_nicht_angefordert" 1 "Licht ist einzuschalten" ;
VAL_ 981 BCM1_CH_aktiv 0 "Inaktiv" 1 "Aktiv" ;
VAL_ 981 BCM1_CH_LH_aktiv 0 "Comming_Home_Bzw._Leaving_Home_nicht_aktiv" 1 "Comming Home bzw. Leaving Home aktiv" ;
VAL_ 981 BCM1_Fahrlicht_Hinweis 0 "kein_Fahrlicht_Hinweis" 1 "Fahrlicht_Hinweis" ;
VAL_ 981 BCM1_Fernlicht_Anf 0 "Licht_nicht_angefordert" 1 "Licht ist einzuschalten" ;
VAL_ 981 BCM1_Gleitende_Leuchtw_Anf 0 "Aus" 1 "Ein" ;
VAL_ 981 BCM1_GLW_Fernlicht_Anf 0 "Aus" 1 "Ein" ;
VAL_ 981 BCM1_Hinweis_Lichtnachlauf 0 "inaktiv" 1 "aktiv" ;
VAL_ 981 BCM1_Kurvenlicht_links_Anf 0 "linkes_Kurvenlicht/Abbiegelicht_durch_BCM1_nicht_angesteuert" 1 "linkes_Kurven/Abbiegelicht_durch_BCM1_angesteuert" ;
VAL_ 981 BCM1_Kurvenlicht_rechts_Anf 0 "rechtes_Kurvenlicht/Abbiegelicht_durch_BCM1_nicht_angesteuert" 1 "rechtes_Kurvenlicht/Abbiegelicht_durch_BCM1_angesteuert" ;
VAL_ 981 BCM1_LH_aktiv 0 "Inaktiv" 1 "Aktiv" ;
VAL_ 981 BCM1_Lichtwarn_Texte 0 "keine_Warnung" 1 "Standlichtwarnung" 2 "Parklichtwarnung" 3 "Nebelschlusslichtwarnung" ;
VAL_ 981 BCM1_Nebellicht_Anf 0 "Licht_nicht_angefordert" 1 "Licht ist einzuschalten" ;
VAL_ 981 BCM1_Nebelschluss_Ahg_Anf 0 "Licht_nicht_angefordert" 1 "Licht ist einzuschalten" ;
VAL_ 981 BCM1_Nebelschluss_Fzg_Anf 0 "Licht_nicht_angefordert" 1 "Licht_ist_einzuschalten" ;
VAL_ 981 BCM1_Parklicht_li_Anf 0 "Licht_nicht_angefordert" 1 "Licht ist einzuschalten" ;
VAL_ 981 BCM1_Parklicht_re_Anf 0 "Licht_nicht_angefordert" 1 "Licht ist einzuschalten" ;
VAL_ 981 BCM1_Regenlicht_Anf 0 "Licht_nicht_angefordert" 1 "Licht ist einzuschalten" ;
VAL_ 981 BCM1_Schlusslicht_Anf 0 "Licht_nicht_angefordert" 1 "Licht ist einzuschalten" ;
VAL_ 981 BCM1_Signaturlicht_Anf 0 "Licht_nicht_angefordert" 1 "Licht_ist_einzuschalten" ;
VAL_ 981 BCM1_Standlicht_Anf 0 "Licht_nicht_angefordert" 1 "Licht ist einzuschalten" ;
VAL_ 981 BCM1_Tagfahrlicht_Anf 0 "Licht_nicht_angefordert" 1 "Licht ist einzuschalten" ;
VAL_ 981 BCM1_Touristen_Licht_Anf 0 "Licht_nicht_angefordert" 1 "Anforderung von Touristenlicht" ;
VAL_ 981 BCM1_Umfeldleuchten_Anf 0 "Licht_nicht_angefordert" 1 "Licht_ist_einzuschalten" ;
VAL_ 981 BCM_Rueckfahrlicht_Anf 0 "Licht_nicht_angefordert" 1 "Licht_angefordert" ;
VAL_ 981 TFL_Matrix_Variante01_Anf 0 "nicht_angefordert" 1 "angefordert" ;
VAL_ 981 TFL_Matrix_Variante02_Anf 0 "nicht_angefordert" 1 "angefordert" ;
VAL_ 981 TFL_Matrix_Variante03_Anf 0 "nicht_angefordert" 1 "angefordert" ;
VAL_ 981 TFL_Matrix_Variante04_Anf 0 "nicht_angefordert" 1 "angefordert" ;
VAL_ 982 BRL_als_SHL 0 "nicht_aktiv" 1 "aktiv" ;
VAL_ 982 LH_3_Bremsl_def 0 "OK" 1 "hochgesetzte Bremsleuchte defekt" ;
VAL_ 982 LH_Aussenlicht_def 0 "OK" 1 "defekt" ;
VAL_ 982 LH_Blinker_HL_akt 1 "Blinker hinten links aktiv" ;
VAL_ 982 LH_Blinker_HR_akt 1 "Blinker hinten rechts aktiv" ;
VAL_ 982 LH_Blinker_li_def 0 "OK" 1 "Blinker hinten links defekt" ;
VAL_ 982 LH_Blinker_re_def 0 "OK" 1 "Blinker hinten rechts defekt" ;
VAL_ 982 LH_Brems_Blk_li_def 0 "OK" 1 "defekt" ;
VAL_ 982 LH_Brems_Blk_re_def 0 "OK" 1 "defekt" ;
VAL_ 982 LH_Bremsl_li_def 0 "OK" 1 "mindestens ein Bremslicht hinten links defekt" ;
VAL_ 982 LH_Bremsl_li_ges_def 0 "OK" 1 "Alle Bremslichter hinten links defekt" ;
VAL_ 982 LH_Bremsl_mi_def 0 "OK" 1 "defekt" ;
VAL_ 982 LH_Bremsl_re_def 0 "OK" 1 "mindestens ein Bremslicht hinten rechts defekt" ;
VAL_ 982 LH_Bremsl_re_ges_def 0 "OK" 1 "Alle Bremslichter hinten rechts defekt" ;
VAL_ 982 LH_Bremslicht_H_aktiv 1 "Bremslicht hinten aktiv" ;
VAL_ 982 LH_Diag_LED_li_def 0 "OK" 1 "Heckleuchte_links_defekt" ;
VAL_ 982 LH_Diag_LED_re_def 0 "OK" 1 "Heckleuchte_rechts_defekt" ;
VAL_ 982 LH_Diag_Status_li_def 0 "OK" 1 "Aussenlicht_Diagnose_Systemstoerung_links" ;
VAL_ 982 LH_Diag_Status_re_def 0 "OK" 1 "Aussenlict_Diagnose_Systemstoerung_rechts" ;
VAL_ 982 LH_Kennzl_def 0 "OK" 1 "Kennzeichenbeleuchtung hinten defekt" ;
VAL_ 982 LH_Nebel_li_def 0 "OK" 1 "" ;
VAL_ 982 LH_Nebel_mi_def 0 "OK" 1 "" ;
VAL_ 982 LH_Nebel_re_def 0 "OK" 1 "Nebelschlusslicht hinten rechts defekt" ;
VAL_ 982 LH_Nebelschluss_aktiv 0 "nicht aktiv" 1 "aktiv" ;
VAL_ 982 LH_Parklicht_HL_aktiv 0 "nicht aktiv" 1 "Parklicht hinten links aktiv" ;
VAL_ 982 LH_Parklicht_HR_aktiv 0 "nicht aktiv" 1 "Parklicht hinten rechts aktiv" ;
VAL_ 982 LH_Rueckf_li_def 0 "OK" 1 "Rï?½ckfahrlicht hinten links defekt" ;
VAL_ 982 LH_Rueckf_mi_def 0 "OK" 1 "Rï?½ckfahllicht Mitte defekt" ;
VAL_ 982 LH_Rueckf_re_def 0 "OK" 1 "Rï?½ckfahrlicht hinten rechts defekt" ;
VAL_ 982 LH_Rueckfahrlicht_aktiv 0 "nicht_aktiv" 1 "aktiv" ;
VAL_ 982 LH_Schluss_Brems_li_def 0 "OK" 1 "defekt" ;
VAL_ 982 LH_Schluss_Brems_mi_def 0 "OK" 1 "Defekt" ;
VAL_ 982 LH_Schluss_Brems_Nebel_li_def 0 "iO" 1 "defekt" ;
VAL_ 982 LH_Schluss_Brems_Nebel_re_def 0 "iO" 1 "defekt" ;
VAL_ 982 LH_Schluss_Brems_re_def 0 "OK" 1 "defekt" ;
VAL_ 982 LH_Schluss_Nebel_li_def 0 "OK" 1 "defekt" ;
VAL_ 982 LH_Schluss_Nebel_re_def 0 "OK" 1 "defekt" ;
VAL_ 982 LH_Schlusslicht_li_def 0 "OK" 1 "mindestens ein Schlusslicht hinten links defekt" ;
VAL_ 982 LH_Schlusslicht_mi_def 0 "OK" 1 "defekt" ;
VAL_ 982 LH_Schlusslicht_re_def 0 "OK" 1 "mindestens ein Schlusslicht hinten rechts defekt" ;
VAL_ 982 LH_SL_BRL_BLK_li_def 0 "OK" 1 "defekt" ;
VAL_ 982 LH_SL_BRL_BLK_re_def 0 "OK" 1 "defekt" ;
VAL_ 982 LH_Standlicht_H_aktiv 1 "Standlicht hinten aktiv" ;
VAL_ 982 LH_Zusatzschlussl_def 0 "OK" 1 "mindestens_ein_Zusatzschlusslicht_defekt" ;
VAL_ 1624 BCM1_Licht_Dunkelheit_aktiv 0 "inaktiv" 1 "aktiv" ;
VAL_ 1624 LV_Abbiegelicht_li_def 0 "OK" 1 "defekt" ;
VAL_ 1624 LV_Abbiegelicht_re_def 0 "OK" 1 "defekt" ;
VAL_ 1624 LV_Abblend_Fernlicht_li_def 0 "OK" 1 "defekt" ;
VAL_ 1624 LV_Abblend_Fernlicht_re_def 0 "OK" 1 "defekt" ;
VAL_ 1624 LV_Abblendlicht_Anzeige 0 "inaktiv" 1 "aktiv" ;
VAL_ 1624 LV_Abblendlicht_li_def 0 "OK" 1 "defekt" ;
VAL_ 1624 LV_Abblendlicht_re_def 0 "OK" 1 "defekt" ;
VAL_ 1624 LV_Abblendlicht_TFL_li_def 0 "OK" 1 "defekt" ;
VAL_ 1624 LV_Abblendlicht_TFL_re_def 0 "OK" 1 "defekt" ;
VAL_ 1624 LV_AFL_aktiv_Anzeige 0 "nicht aktiv" 1 "aktiv" ;
VAL_ 1624 LV_AFL_defekt 0 "OK" 1 "defekt" ;
VAL_ 1624 LV_Aussenlicht_def 0 "OK" 1 "defekt" ;
VAL_ 1624 LV_Blinker_li_def 0 "OK" 1 "defekt" ;
VAL_ 1624 LV_Blinker_re_def 0 "OK" 1 "defekt" ;
VAL_ 1624 LV_Blinker_VL_aktiv 0 "inaktiv" 1 "aktiv" ;
VAL_ 1624 LV_Blinker_VR_aktiv 0 "inaktiv" 1 "aktiv" ;
VAL_ 1624 LV_Blk_li_Seite_def 0 "OK" 1 "defekt" ;
VAL_ 1624 LV_Blk_re_Seite_def 0 "OK" 1 "defekt" ;
VAL_ 1624 LV_Fernlicht_Anzeige 0 "nicht aktiv" 1 "aktiv" ;
VAL_ 1624 LV_Fernlicht_li_def 0 "OK" 1 "defekt" ;
VAL_ 1624 LV_Fernlicht_re_def 0 "OK" 1 "defekt" ;
VAL_ 1624 LV_FLA_aktiv_Anzeige 0 "aus" 1 "ein" ;
VAL_ 1624 LV_FLA_defekt 0 "i.O." 1 "FLA defekt" ;
VAL_ 1624 LV_FLA_Sensor_blockiert 0 "i.O." 1 "FLA-Sensor blockiert" ;
VAL_ 1624 LV_LED_Scheinwerfer_li_def 0 "OK" 1 "defekt" ;
VAL_ 1624 LV_LED_Scheinwerfer_re_def 0 "OK" 1 "defekt" ;
VAL_ 1624 LV_MXB_Status_Anzeige 0 "MXB_aus" 1 "MXB_regelt" 2 "MXB_volles_Fernlicht" 3 "MXB_und_Laser_aktiv" ;
VAL_ 1624 LV_Nebellicht_Anzeige 0 "nicht aktiv" 1 "aktiv" ;
VAL_ 1624 LV_Nebellicht_li_def 0 "OK" 1 "defekt" ;
VAL_ 1624 LV_Nebellicht_re_def 0 "OK" 1 "defekt" ;
VAL_ 1624 LV_Nebellicht_TFL_li_def 0 "OK" 1 "defekt" ;
VAL_ 1624 LV_Nebellicht_TFL_re_def 0 "OK" 1 "defekt" ;
VAL_ 1624 LV_Nebelschlusslicht_Anzeige 0 "nicht aktiv" 1 "aktiv" ;
VAL_ 1624 LV_Standlicht_Anzeige 0 "nicht aktiv" 1 "aktiv" ;
VAL_ 1624 LV_Standlicht_li_def 0 "OK" 1 "defekt" ;
VAL_ 1624 LV_Standlicht_re_def 0 "OK" 1 "defekt" ;
VAL_ 1624 LV_Standlicht_TFL_li_def 0 "OK" 1 "defekt" ;
VAL_ 1624 LV_Standlicht_TFL_re_def 0 "OK" 1 "defekt" ;
VAL_ 1624 LV_Tagfahrlicht_Anzeige 0 "nicht aktiv" 1 "aktiv" ;
VAL_ 1624 LV_Tagfahrlicht_li_def 0 "OK" 1 "defekt" ;
VAL_ 1624 LV_Tagfahrlicht_re_def 0 "OK" 1 "defekt" ;
VAL_ 2527679675 LiSi_Defrost_Taste 0 "Taste_nicht_betaetigt" 1 "Taste_betaetigt" 2 "Fehler" 3 "Init_oder_nicht_verbaut" ;
VAL_ 2527679675 LiSi_FSH_Taste 0 "Taste_nicht_betaetigt" 1 "Taste_betaetigt" 2 "Fehler" 3 "Init_oder_nicht_verbaut" ;
VAL_ 2527679675 LiSi_HSH_Taste 0 "Taste_nicht_betaetigt" 1 "Taste_betaetigt" 2 "Fehler" 3 "Init_oder_nicht_verbaut" ;
VAL_ 2527679675 LiSi_Touch_Event 0 "nicht_betaetigt" 1 "Tippen" 2 "Wischen_Slide" 3 "Geste" 4 "Doppeltippen" 5 "Longpress_1" 6 "Longpress_2" 7 "Longpress_3" 8 "Press" 9 "Strongpress" 10 "reserviert" 11 "reserviert" 12 "reserviert" 13 "reserviert" 14 "Taktgeber_Inkrement" 15 "Fehler" ;
VAL_ 2527679675 LTM_Autolicht 0 "Taste_unbetaetigt" 1 "Taste_betaetigt" 2 "Taste_nicht_verbaut" ;
VAL_ 2527679675 LTM_Beruehrung 0 "Beruehrung_inaktiv" 1 "Beruehrung_aktiv" 2 "Beruehrungssensor_nicht_verbaut" ;
VAL_ 2527679675 LTM_Lokalaktiv 0 "war_nicht_lokal_aktiv" 1 "war_lokal_aktiv" ;
VAL_ 2527679675 LTM_Nebellicht 0 "Taste_unbetaetigt" 1 "Taste_betaetigt" 2 "Taste_nicht_verbaut" ;
VAL_ 2527679675 LTM_Nebelschlusslicht 0 "Taste_unbetaetigt" 1 "Taste_betaetigt" 2 "Taste_nicht_verbaut" ;
VAL_ 2527679675 LTM_ResponseError 0 "normal" 1 "Fehler" ;
VAL_ 2527679675 LTM_StatusLichttastenmodul 0 "Lichttastenmodul_betriebsbereit" 2 "Init" 3 "Fehler_oder_defekt" ;
VAL_ 2527679675 LTM_Variante 0 "Ein_Tasten_Bedienung" 1 "Drei_Tasten_Bedienung" 2 "Variante_3" 3 "Variante_4" ;
VAL_ 134 LWI_Lenkradw_Geschw 510 "Init" 511 "Fehler" ;
VAL_ 134 LWI_Lenkradwinkel 8190 "Init" 8191 "Fehler" ;
VAL_ 134 LWI_QBit_Lenkradwinkel 0 "gï?½ltiger Wert" 1 "ausserhalb der Spezifikation" ;
VAL_ 134 LWI_QBit_Sub_Daten 0 "LWS-Subinfo real (Lenkradwinkelinformation ADS-tauglich) " 1 "LWS-Subinfo simuliert (Lenkradwinkelinformation nicht ADS-tauglich )" ;
VAL_ 134 LWI_Sensorstatus 0 "iO" 1 "nicht kalibriert" ;
VAL_ 134 LWI_VZ_Lenkradw_Geschw 0 "positiv_links_von_der_Nullstellung" 1 "negativ" ;
VAL_ 134 LWI_VZ_Lenkradwinkel 0 "positiv_links_von_der_Nullstellung" 1 "negativ" ;
